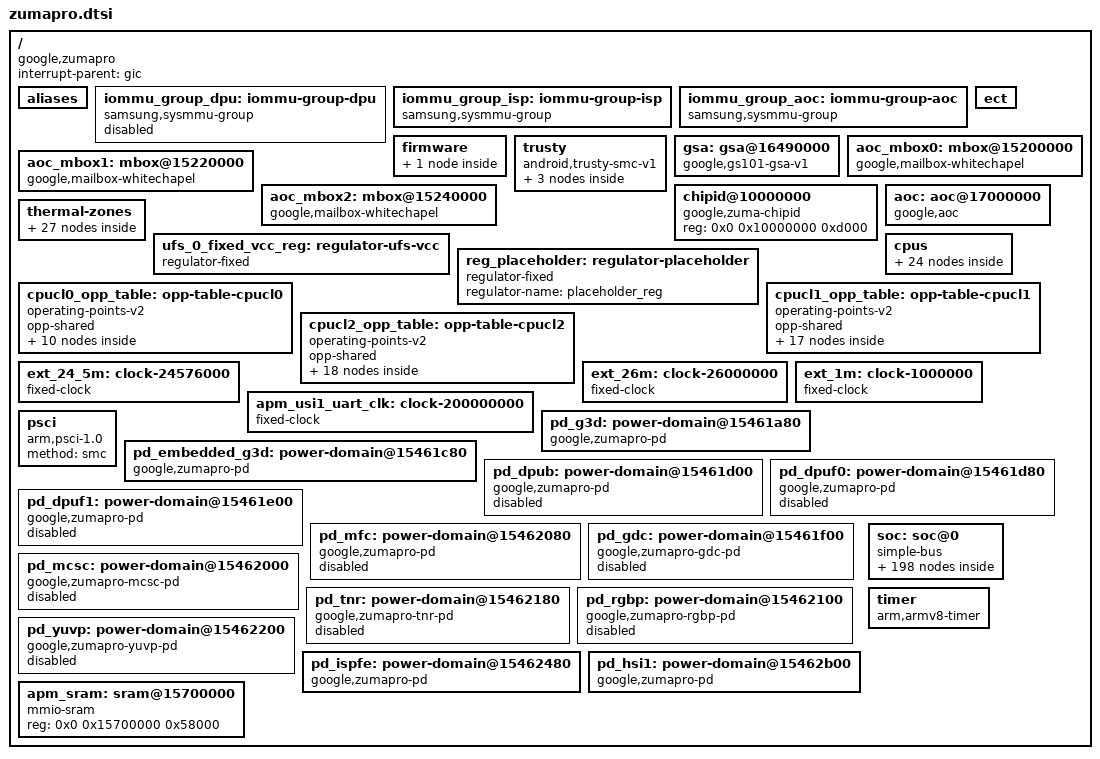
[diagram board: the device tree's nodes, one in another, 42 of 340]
// SPDX-License-Identifier: GPL-2.0-only
/*
 * Google Tensor G4 "Zumapro" SoC skeleton.
 *
 * Hardware values are taken from the downstream Pixel 9a/Tegu dump in
 * ../../../../../../research/dumped.dts unless another source is named.
 */

#include <dt-bindings/clock/google,zumapro-acpm.h>
#include <dt-bindings/clock/google,zumapro.h>
#include <dt-bindings/gpio/gpio.h>
#include <dt-bindings/interconnect/google,zumapro.h>
#include <dt-bindings/interrupt-controller/arm-gic.h>
#include <dt-bindings/interrupt-controller/irq.h>
#include <dt-bindings/interconnect/google,zumapro.h>
#include <dt-bindings/thermal/thermal.h>
#include <dt-bindings/soc/samsung,exynos-usi.h>
#include "zumapro-pinctrl.h"

/ {
	/*
	 * Source: downstream compatible strings are "google,ZUMA PRO TEGU",
	 * "google,ZUMA PRO" in research/dumped.dts:6.  The lowercase spelling
	 * follows the upstream convention documented in google.yaml.
	 */
	compatible = "google,zumapro";
	#address-cells = <2>;
	#size-cells = <1>;

	/* Source: interrupt-parent points at the GIC in research/dumped.dts:7. */
	interrupt-parent = <&gic>;

	/*
	 * Source: downstream aliases in research/dumped.dts:5759-5772.
	 * Keep the pinctrl aliases aligned with downstream controller numbering.
	 */
	aliases {
		pinctrl0 = &pinctrl_alive;
		pinctrl1 = &pinctrl_eint;
		pinctrl2 = &pinctrl_far_alive;
		pinctrl3 = &pinctrl_gsacore0;
		pinctrl4 = &pinctrl_gsacore1;
		pinctrl5 = &pinctrl_gsacore2;
		pinctrl6 = &pinctrl_gsacore3;
		pinctrl7 = &pinctrl_gsacore4;
		pinctrl8 = &pinctrl_hsi0;
		pinctrl9 = &pinctrl_hsi1;
		pinctrl10 = &pinctrl_hsi2;
		pinctrl11 = &pinctrl_peric0;
		pinctrl12 = &pinctrl_peric1;
		i2c2 = &hsi2c_2;
		i2c3 = &hsi2c_3;
		i2c4 = &hsi2c_4;
		i2c5 = &hsi2c_5;
		i2c6 = &hsi2c_6;
		i2c9 = &hsi2c_9;
		i2c10 = &hsi2c_10;
		ufs0 = &ufs_0;
	};

	/*
	 * Source: downstream iommu_group_dpu in zumapro-sysmmu.dtsi and
	 * research/dumped.dts:762.  TRACE NEEDED: validate how the downstream
	 * v9 group driver maps DECON0's two DPUF System MMUs before wiring a
	 * mainline DECON node to this group.
	 */
	iommu_group_dpu: iommu-group-dpu {
		compatible = "samsung,sysmmu-group";
		status = "disabled";
	};

	/*
	 * Source: downstream iommu_group_isp in research/dumped.dts:768.  The
	 * camera's three System MMUs share one group and one page table, and
	 * the v9 driver requires the group object to exist: without a
	 * samsung,iommu-group phandle it falls back to generic_device_group(),
	 * whose group carries no driver data, and every attach then fails with
	 * -EPROBE_DEFER -- which the IOMMU core warns about and does not
	 * retry, leaving the camera on dma-direct.
	 */
	iommu_group_isp: iommu-group-isp {
		compatible = "samsung,sysmmu-group";
	};

	/*
	 * Source: downstream iommu_group_aoc in research/dumped.dts:837.
	 * The AoC device references this group via samsung,iommu-group.
	 * Enabled (unlike the DPU group above) because AoC is being wired up.
	 */
	iommu_group_aoc: iommu-group-aoc {
		compatible = "samsung,sysmmu-group";
	};

	/*
	 * Source: GS101 upstream binding requires an empty ect node
	 * (Documentation/devicetree/bindings/arm/google.yaml).  The Zumapro
	 * downstream tree also has ECT reserved memory at dumped.dts:1320.
	 */
	ect {
	};

	/*
	 * Source: gs101.dtsi ACPM pattern.  Protocol identity with gs101 was
	 * hardware-verified on the Pixel 9a: the channel table at SRAM+0xa000
	 * parses with the mainline gs101 initdata structs (16 channels, PMIC
	 * on channel 2), and a full boot of the downstream kernel traced
	 * under the m1n1 hypervisor showed the identical doorbell/queue/PMIC
	 * wire protocol, so the gs101 fallback compatible drives the zumapro
	 * ACPM firmware unmodified.  See research/tracing/acpm-channels.md
	 * and research/tracing/acpm-boot-rail-snapshot.md.
	 */
	firmware {
		acpm_ipc: power-management {
			compatible = "google,zumapro-acpm-ipc",
				     "google,gs101-acpm-ipc";
			mboxes = <&ap2apm_mailbox>;
			shmem = <&apm_sram>;
			/*
			 * clk-acpm registers its ACPM-DVFS clocks against this
			 * node (the child clk device has no of_node, so the clk
			 * core falls back to the parent), so consumers reference
			 * them as <&acpm_ipc id>, where id is the ACPM DVFS
			 * domain index (e.g. 7 = G3D, 8 = G3DL2).
			 */
			#clock-cells = <1>;

		};
	};

	/*
	 * Trusty TEE.  SMC transport to the bootloader-started Trusty (TZSW);
	 * no MMIO.  Children are the IRQ forwarder, the log, and the virtio
	 * transport that carries tipc.  ipi-range mirrors research/dumped.dts
	 * (trusty/irq ipi-range = <8 15 8>).  Needed for the AoC GSA-hwmgr
	 * firmware-start path (docs/platform/aoc.md).
	 */
	trusty {
		compatible = "android,trusty-smc-v1";

		irq {
			compatible = "android,trusty-irq-v1";
			ipi-range = <8 15 8>;
		};

		log {
			compatible = "android,trusty-log-v1";
		};

		virtio {
			compatible = "android,trusty-virtio-v1";
		};
	};

	/*
	 * Google Security Authenticator (GSA) client.  Hardware mailbox at
	 * 0x16490000 for firmware-image authentication, plus a Trusty tipc
	 * channel (hwmgr) for coprocessor start.  The s2mpu phandle and the
	 * log-region / gsa_gsc child are omitted -- pKVM, GSC and the GSA log
	 * are disabled for this minimal bring-up.  Needed to authenticate and
	 * start AoC (docs/platform/aoc.md).  IRQ from research/dumped.dts
	 * (gsa-ns interrupts = <0 0x177 4>).
	 */
	gsa: gsa@16490000 {
		compatible = "google,gs101-gsa-v1";
		reg = <0x0 0x16490000 0x1000>;
		interrupts = <GIC_SPI 375 IRQ_TYPE_LEVEL_HIGH 0>;
	};

	/*
	 * Whitechapel mailbox controllers for AoC.  Source: downstream
	 * mbox@15200000/15220000/15240000 in research/dumped.dts:13198-13232.
	 * Each carries 16 AoC<->AP channels; the AoC node below fans all 48
	 * out through them.  reg/interrupts/mbox-name and the
	 * wc-mbox-non-wake-channels mask are verbatim from the dump.
	 */
	aoc_mbox0: mbox@15200000 {
		compatible = "google,mailbox-whitechapel";
		reg = <0x0 0x15200000 0x1000>;
		interrupts = <GIC_SPI 77 IRQ_TYPE_LEVEL_HIGH 0>;
		mbox-name = "aoc_a32_ap";
		#mbox-cells = <1>;
		wc-mbox-non-wake-channels = <0xf000>;
	};

	aoc_mbox1: mbox@15220000 {
		compatible = "google,mailbox-whitechapel";
		reg = <0x0 0x15220000 0x1000>;
		interrupts = <GIC_SPI 78 IRQ_TYPE_LEVEL_HIGH 0>;
		mbox-name = "aoc_f1_ap";
		#mbox-cells = <1>;
		wc-mbox-non-wake-channels = <0xf000>;
	};

	aoc_mbox2: mbox@15240000 {
		compatible = "google,mailbox-whitechapel";
		reg = <0x0 0x15240000 0x1000>;
		interrupts = <GIC_SPI 79 IRQ_TYPE_LEVEL_HIGH 0>;
		mbox-name = "aoc_p6_ap";
		#mbox-cells = <1>;
		wc-mbox-non-wake-channels = <0xf000>;
	};

	/*
	 * SoC chip-id block.  Source: downstream chipid@10000000 in
	 * research/dumped.dts:14927 (reg verbatim).  No in-tree driver binds this
	 * compatible; the AoC chip-id reader (aoc_chipid.c) maps it to forward the
	 * SoC product-id/type/revision to AoC firmware via fw_data.
	 */
	chipid@10000000 {
		compatible = "google,zuma-chipid";
		reg = <0x0 0x10000000 0xd000>;
	};

	/*
	 * Always-On Compute coprocessor.  Source: downstream aoc@17000000 in
	 * research/dumped.dts:13234.  reg regions (blk_aoc, aoc_req, aoc_s2mpu,
	 * ssmt_aoc), the watchdog interrupt, the 48-channel mailbox fan-out and
	 * every scalar tuning word are verbatim from the dump.  Dropped from the
	 * dump: pinctrl-0/-names (driver never uses pinctrl; the phandle pointed
	 * at aoc-vsync-pins) and sensor_1v8/3v3-supply + sensor_power_list (would
	 * pull in regulators; sensor power is deferred).
	 */
	aoc: aoc@17000000 {
		compatible = "google,aoc";
		reg = <0x0 0x17000000 0x2000000>,
		      <0x0 0x154b0000 0x1000>,
		      <0x0 0x190c0000 0x1000>,
		      <0x0 0x19060000 0x5000>;
		reg-names = "blk_aoc", "aoc_req", "aoc_s2mpu", "ssmt_aoc";
		interrupts = <GIC_SPI 130 IRQ_TYPE_LEVEL_HIGH 0>;
		interrupt-names = "watchdog";
		iommus = <&sysmmu_aoc>;
		samsung,iommu-group = <&iommu_group_aoc>;
		memory-region = <&aoc_reserved>;
		/* gsa-enabled = "true"; -- read as a bool; a string value warns */
		gsa-enabled;
		gsa-device = <&gsa>;
		mbox-channels = <48>;
		mbox-names = "aoc2ap";
		mboxes = <&aoc_mbox0 0>, <&aoc_mbox0 1>, <&aoc_mbox0 2>,
			 <&aoc_mbox0 3>, <&aoc_mbox0 4>, <&aoc_mbox0 5>,
			 <&aoc_mbox0 6>, <&aoc_mbox0 7>, <&aoc_mbox0 8>,
			 <&aoc_mbox0 9>, <&aoc_mbox0 10>, <&aoc_mbox0 11>,
			 <&aoc_mbox0 12>, <&aoc_mbox0 13>, <&aoc_mbox0 14>,
			 <&aoc_mbox0 15>,
			 <&aoc_mbox1 0>, <&aoc_mbox1 1>, <&aoc_mbox1 2>,
			 <&aoc_mbox1 3>, <&aoc_mbox1 4>, <&aoc_mbox1 5>,
			 <&aoc_mbox1 6>, <&aoc_mbox1 7>, <&aoc_mbox1 8>,
			 <&aoc_mbox1 9>, <&aoc_mbox1 10>, <&aoc_mbox1 11>,
			 <&aoc_mbox1 12>, <&aoc_mbox1 13>, <&aoc_mbox1 14>,
			 <&aoc_mbox1 15>,
			 <&aoc_mbox2 0>, <&aoc_mbox2 1>, <&aoc_mbox2 2>,
			 <&aoc_mbox2 3>, <&aoc_mbox2 4>, <&aoc_mbox2 5>,
			 <&aoc_mbox2 6>, <&aoc_mbox2 7>, <&aoc_mbox2 8>,
			 <&aoc_mbox2 9>, <&aoc_mbox2 10>, <&aoc_mbox2 11>,
			 <&aoc_mbox2 12>, <&aoc_mbox2 13>, <&aoc_mbox2 14>,
			 <&aoc_mbox2 15>;
		acpm-ipc-channel = <0x0d>;
		force-vnom = <0x00>;
		pcu-base = <0x1400000>;
		gpio-base = <0x1c00000>;
		pcu-db-set-offset = <0x1f004>;
		pcu-db-clr-offset = <0x1f008>;
		cp-aperture-start-offset = <0x7fdf80>;
		cp-aperture-end-offset = <0x7fffff>;
		clock-divider = <0x01>;
		channel-max-pending-msgs = <0x80>;
		block-channel-threshold = <0x40>;
		notify-on-state-transition = "true";
		hotword-supported = "true";
		chre-supported = "true";
		aoc-board-cfg = "TG4";
		aoc-board-id = <0x60b02>;
		aoc-board-rev = <0x10000>;
		prevent-fw-load = <0x00>;
		gnss-type = <0x02>;
	};

	/*
	 * ACPM TMU zones.  The ACPM firmware only *measures* on a bare boot (its
	 * throttling governor is configured by the downstream kernel, not the
	 * bootloader), so the CPU-cluster zones own throttling in Linux via
	 * cpufreq cooling under the power_allocator (IPA) PID governor -- the
	 * mainline analog of downstream's use-pi-thermal.  step_wise only
	 * limit-cycles on the fast X4; IPA holds the setpoint (HW-validated).
	 * Each CPU zone has a SINGLE passive control trip (the IPA setpoint,
	 * downstream BIG 90 / MID,LITTLE 95, dumped.dts:17894+) plus a critical
	 * backstop.  With one passive trip IPA runs always-on and its band is the
	 * control temperature itself, so estimate_pid_constants() derives gentle
	 * gains (k_po~17) -- a second "switch-on" passive trip narrows the band
	 * into steep gains and resets the PID integral whenever the fast X4 dips
	 * below it, collapsing the controller into a bang-bang relay (HW-confirmed
	 * 45<->100 C swing).  sustainable-power is measured per cluster with the
	 * S2MPG14 ODPM meter under an all-core load: BIG=1200 (its draw while IPA
	 * holds it at the 90 C trip); MID=1500 and LITTLE=1000 are the clusters'
	 * full-tilt power -- they only reach ~80/60 C, well below their 95 C trip,
	 * so their value is a never-actuated safety-net feed-forward.
	 * Cluster<->sensor: cpu7 (X4)=BIG tzid0, cpu4 (A720)=MID tzid1, cpu0
	 * (A520)=LITTLE tzid2.  G3D/ISP/TPU/AUR stay monitor-only.
	 *
	 * Trip *detection* is now the TMU interrupt's job: it fires when the zone
	 * leaves the thermal core's trip window, so a hard ramp no longer waits
	 * for a poll to be noticed.  polling-delay-passive stays at 25 ms because
	 * IPA's PID needs periodic samples once it is regulating; the interrupt
	 * arms that state immediately instead of up to a poll period late.
	 *
	 * polling-delay must NOT be 0, even with interrupts.  These zones have a
	 * single passive trip, so gov_power_allocator's setup leaves
	 * params->trip_switch_on NULL (it is the *first* of two or more passive
	 * trips), and power_allocator_manage() gates allow_maximum_power() on it.
	 * IPA therefore has no explicit release path here: it only unwinds a
	 * throttle through repeated allocate_power() calls as the zone cools.
	 * Once the zone drops out of the trip's hysteresis band tz->passive falls
	 * to 0 and the 25 ms passive poll stops, so with polling-delay = 0 nothing
	 * would ever run the governor again and the last cooling state would stick
	 * forever -- HW-observed: cpu7 pinned at 13/17 (1745 of 3105 MHz) at 41 C
	 * idle until something else poked the zone.  The cool-side poll is what
	 * releases the throttle, which is why 1 s is enough now that it no longer
	 * has to *detect* anything.  (Upstream gs101 can use 0 because its ladder
	 * has two passive trips, so allow_maximum_power() is reachable there.)
	 */
	thermal-zones {
		big-thermal {
			polling-delay = <1000>;
			polling-delay-passive = <25>;
			thermal-sensors = <&tmu_top 0>;
			sustainable-power = <1200>;

			trips {
				/*
				 * Single passive trip = always-on IPA: the band is
				 * the control temperature itself (90 C), which makes
				 * estimate_pid_constants() derive gentle gains
				 * (k_po~17).  A second "switch-on" passive trip would
				 * narrow the band into steep gains AND reset the PID
				 * integral every time the fast X4 dips below it, which
				 * degrades the controller into a bang-bang relay
				 * (HW-confirmed).  This is also step_wise's throttle
				 * point when that fallback governor is selected.
				 */
				big_alert: throttle {
					temperature = <90000>;
					hysteresis = <5000>;
					type = "passive";
				};

				big_crit: critical {
					temperature = <115000>;
					hysteresis = <1000>;
					type = "critical";
				};
			};

			cooling-maps {
				map0 {
					trip = <&big_alert>;
					cooling-device = <&cpu7 THERMAL_NO_LIMIT THERMAL_NO_LIMIT>;
				};
			};
		};

		mid-thermal {
			polling-delay = <1000>;
			polling-delay-passive = <25>;
			thermal-sensors = <&tmu_top 1>;
			/*
			 * Measured ~1500 mW full-tilt (ODPM, all-core load); MID
			 * peaks ~80 C, 15 C below its control trip, so like LITTLE
			 * this is a never-actuated safety-net feed-forward.
			 */
			sustainable-power = <1500>;

			trips {
				/* Always-on IPA, single passive trip; see big-thermal. */
				mid_alert: throttle {
					temperature = <95000>;
					hysteresis = <5000>;
					type = "passive";
				};

				mid_crit: critical {
					temperature = <115000>;
					hysteresis = <1000>;
					type = "critical";
				};
			};

			cooling-maps {
				map0 {
					trip = <&mid_alert>;
					cooling-device = <&cpu4 THERMAL_NO_LIMIT THERMAL_NO_LIMIT>;
				};
			};
		};

		little-thermal {
			polling-delay = <1000>;
			polling-delay-passive = <25>;
			thermal-sensors = <&tmu_top 2>;
			/*
			 * Measured ~1000 mW full-tilt (ODPM, all-core load -- the
			 * EM estimate of ~440 mW was ~2x low for the A520).  LITTLE
			 * peaks ~60 C, 35 C below its control trip, so this never
			 * actuates; it is a safety-net feed-forward only.
			 */
			sustainable-power = <1000>;

			trips {
				/* Always-on IPA, single passive trip; see big-thermal. */
				little_alert: throttle {
					temperature = <95000>;
					hysteresis = <5000>;
					type = "passive";
				};

				little_crit: critical {
					temperature = <115000>;
					hysteresis = <1000>;
					type = "critical";
				};
			};

			cooling-maps {
				map0 {
					trip = <&little_alert>;
					cooling-device = <&cpu0 THERMAL_NO_LIMIT THERMAL_NO_LIMIT>;
				};
			};
		};

		/*
		 * Throttle temps are downstream's (throttle 90 C, and a 115 C
		 * critical backstop matching the CPU zones).  The sensor reads
		 * live at all times because pd_g3d is samsung,always-on, so
		 * there is no collapsed-domain reading to guard against.
		 *
		 * sustainable-power is the measured full-tilt figure, matching
		 * the top of the OPP table's own measured power (glmark2 pinned
		 * at 940 MHz reached only 63 C, so the part sustains this
		 * without approaching the trip -- like MID and LITTLE, this is a
		 * feed-forward safety net rather than something that actuates).
		 *
		 * It has to be set explicitly, and not just for accuracy: with a
		 * single passive trip the IPA gains come from
		 * estimate_pid_constants() as sustainable_power over the control
		 * temperature, so a small value truncates k_po and k_pu to ZERO
		 * and the budget collapses to sustainable_power alone.  Letting
		 * the kernel estimate it here produced 28 mW, which pinned the
		 * GPU at cooling state 7 -- capped at 521 MHz -- while idling at
		 * 48 C, 40 C below the trip.
		 */
		g3d-thermal {
			polling-delay = <1000>;
			polling-delay-passive = <25>;
			thermal-sensors = <&tmu_sub 0>;
			sustainable-power = <740>;

			trips {
				/* Always-on IPA, single passive trip; see big-thermal. */
				g3d_alert: throttle {
					temperature = <90000>;
					hysteresis = <5000>;
					type = "passive";
				};

				g3d_crit: critical {
					temperature = <115000>;
					hysteresis = <1000>;
					type = "critical";
				};
			};

			cooling-maps {
				map0 {
					trip = <&g3d_alert>;
					cooling-device = <&gpu THERMAL_NO_LIMIT THERMAL_NO_LIMIT>;
				};
			};
		};

		isp-thermal {
			polling-delay = <0>;
			polling-delay-passive = <0>;
			thermal-sensors = <&tmu_sub 1>;
		};

		tpu-thermal {
			polling-delay = <0>;
			polling-delay-passive = <0>;
			thermal-sensors = <&tmu_sub 2>;
		};

		aur-thermal {
			polling-delay = <0>;
			polling-delay-passive = <0>;
			thermal-sensors = <&tmu_sub 3>;
		};
	};

	/*
	 * Source: dumped.dts:7858-7863. The pre-guest m1n1 readout shows
	 * gpp0-1 is an output but low at handoff, so Linux must assert this
	 * fixed-regulator GPIO before UFS link startup.
	 */
	ufs_0_fixed_vcc_reg: regulator-ufs-vcc {
		compatible = "regulator-fixed";
		regulator-name = "ufs-vcc";
		gpio = <&gpp0 1 GPIO_ACTIVE_HIGH>;
		regulator-boot-on;
		enable-active-high;
	};

	/*
	 * Placeholder supply for rails that are real but not yet driver-managed,
	 * mirroring the gs101 reg_placeholder approach.  The USB controller/PHY
	 * rails (downstream m_ldo8/m_ldo9/m_ldo19 under sub_pd_hsi0, left enabled
	 * by the bootloader) are wired here so the mainline drivers'
	 * regulator_get() calls resolve to a real fixed supply rather than an
	 * implicit dummy.
	 *
	 * TODO: replace with the real s2mpg14/15 PMIC rails once that driver
	 * exists.  Expected mapping: vdd -> m_ldo8, vdda12 -> m_ldo9, and
	 * vdd33 (plus the eUSB repeater) -> m_ldo19.
	 */
	reg_placeholder: regulator-placeholder {
		compatible = "regulator-fixed";
		regulator-name = "placeholder_reg";
	};

	cpus {
		/*
		 * Source: CPU address/size cells match research/dumped.dts:3065-3066.
		 */
		#address-cells = <2>;
		#size-cells = <0>;

		/*
		 * Source: downstream cpu-map is flattened in dumped.dts:3068-3106,
		 * while the cluster grouping below follows downstream cpupm/acme
		 * sibling CPU groups in dumped.dts:3248-3275 and 3327-3369.
		 */
		cpu-map {
			cluster0 {
				core0 {
					cpu = <&cpu0>;
				};
				core1 {
					cpu = <&cpu1>;
				};
				core2 {
					cpu = <&cpu2>;
				};
				core3 {
					cpu = <&cpu3>;
				};
			};

			cluster1 {
				core0 {
					cpu = <&cpu4>;
				};
				core1 {
					cpu = <&cpu5>;
				};
				core2 {
					cpu = <&cpu6>;
				};
			};

			cluster2 {
				core0 {
					cpu = <&cpu7>;
				};
			};
		};

		/*
		 * Source: reg, enable-method, idle-state assignment, capacity, and
		 * dynamic power values are copied from research/dumped.dts:3108-3188.
		 * Downstream only reports compatible = "arm,armv9.2"; the concrete
		 * Cortex compatibles below are inferred from the downstream Hayes,
		 * Hunter, and Hunter-ELP idle-state names at dumped.dts:3198,
		 * dumped.dts:3210, and dumped.dts:3222.  Verify against MIDR on
		 * hardware before treating the CPU compatible strings as final.
		 */
		cpu0: cpu@0 {
			device_type = "cpu";
			compatible = "arm,cortex-a520";
			reg = <0x0 0x0>;
			clocks = <&acpm_ipc ZUMAPRO_CLK_ACPM_DVFS_CPUCL0>;
			operating-points-v2 = <&cpucl0_opp_table>;
			enable-method = "psci";
			cpu-idle-states = <&hayes_cpu_sleep>;
			capacity-dmips-mhz = <0xc1>;
			dynamic-power-coefficient = <0x46>;
			#cooling-cells = <2>;
		};

		cpu1: cpu@100 {
			device_type = "cpu";
			compatible = "arm,cortex-a520";
			reg = <0x0 0x100>;
			clocks = <&acpm_ipc ZUMAPRO_CLK_ACPM_DVFS_CPUCL0>;
			operating-points-v2 = <&cpucl0_opp_table>;
			enable-method = "psci";
			cpu-idle-states = <&hayes_cpu_sleep>;
			capacity-dmips-mhz = <0xc1>;
			dynamic-power-coefficient = <0x46>;
		};

		cpu2: cpu@200 {
			device_type = "cpu";
			compatible = "arm,cortex-a520";
			reg = <0x0 0x200>;
			clocks = <&acpm_ipc ZUMAPRO_CLK_ACPM_DVFS_CPUCL0>;
			operating-points-v2 = <&cpucl0_opp_table>;
			enable-method = "psci";
			cpu-idle-states = <&hayes_cpu_sleep>;
			capacity-dmips-mhz = <0xc1>;
			dynamic-power-coefficient = <0x46>;
		};

		cpu3: cpu@300 {
			device_type = "cpu";
			compatible = "arm,cortex-a520";
			reg = <0x0 0x300>;
			clocks = <&acpm_ipc ZUMAPRO_CLK_ACPM_DVFS_CPUCL0>;
			operating-points-v2 = <&cpucl0_opp_table>;
			enable-method = "psci";
			cpu-idle-states = <&hayes_cpu_sleep>;
			capacity-dmips-mhz = <0xc1>;
			dynamic-power-coefficient = <0x46>;
		};

		cpu4: cpu@400 {
			device_type = "cpu";
			compatible = "arm,cortex-a720";
			reg = <0x0 0x400>;
			clocks = <&acpm_ipc ZUMAPRO_CLK_ACPM_DVFS_CPUCL1>;
			operating-points-v2 = <&cpucl1_opp_table>;
			enable-method = "psci";
			cpu-idle-states = <&hunter_cpu_sleep>;
			capacity-dmips-mhz = <0x39f>;
			dynamic-power-coefficient = <0x201>;
			#cooling-cells = <2>;
		};

		cpu5: cpu@500 {
			device_type = "cpu";
			compatible = "arm,cortex-a720";
			reg = <0x0 0x500>;
			clocks = <&acpm_ipc ZUMAPRO_CLK_ACPM_DVFS_CPUCL1>;
			operating-points-v2 = <&cpucl1_opp_table>;
			enable-method = "psci";
			cpu-idle-states = <&hunter_cpu_sleep>;
			capacity-dmips-mhz = <0x39f>;
			dynamic-power-coefficient = <0x201>;
		};

		cpu6: cpu@600 {
			device_type = "cpu";
			compatible = "arm,cortex-a720";
			reg = <0x0 0x600>;
			clocks = <&acpm_ipc ZUMAPRO_CLK_ACPM_DVFS_CPUCL1>;
			operating-points-v2 = <&cpucl1_opp_table>;
			enable-method = "psci";
			cpu-idle-states = <&hunter_cpu_sleep>;
			capacity-dmips-mhz = <0x39f>;
			dynamic-power-coefficient = <0x201>;
		};

		cpu7: cpu@700 {
			device_type = "cpu";
			compatible = "arm,cortex-x4";
			reg = <0x0 0x700>;
			clocks = <&acpm_ipc ZUMAPRO_CLK_ACPM_DVFS_CPUCL2>;
			operating-points-v2 = <&cpucl2_opp_table>;
			enable-method = "psci";
			cpu-idle-states = <&hunterelp_cpu_sleep>;
			capacity-dmips-mhz = <0x400>;
			dynamic-power-coefficient = <0x2f5>;
			#cooling-cells = <2>;
		};

		idle-states {
			/*
			 * Source: idle-state values come from research/dumped.dts:3195-3228.
			 * entry-method is normalized to "psci" per psci.yaml; downstream
			 * used "arm,psci".
			 */
			entry-method = "psci";

			hayes_cpu_sleep: cpu-hayes-sleep {
				idle-state-name = "c2";
				compatible = "arm,idle-state";
				arm,psci-suspend-param = <0x10000>;
				local-timer-stop;
				entry-latency-us = <0x46>;
				exit-latency-us = <0xa0>;
				min-residency-us = <0x7d0>;
			};

			hunter_cpu_sleep: cpu-hunter-sleep {
				idle-state-name = "c2";
				compatible = "arm,idle-state";
				arm,psci-suspend-param = <0x10000>;
				local-timer-stop;
				entry-latency-us = <0x96>;
				exit-latency-us = <0xbe>;
				min-residency-us = <0x9c4>;
			};

			hunterelp_cpu_sleep: cpu-hunterelp-sleep {
				idle-state-name = "c2";
				compatible = "arm,idle-state";
				arm,psci-suspend-param = <0x10000>;
				local-timer-stop;
				entry-latency-us = <0xeb>;
				exit-latency-us = <0xdc>;
				min-residency-us = <0xdac>;
			};
		};
	};

	/*
	 * CPU operating points for the three clusters.  Frequencies are the
	 * downstream pixel-em "default" profile (research/dumped.dts:3360, the
	 * cpu0/cpu4/cpu7 ladders) and match the exynos-acme per-domain
	 * min/max-freq at research/dumped.dts:3326-3370.  The supplying clock is
	 * the ACPM DVFS domain for each cluster (CPUCL0/1/2 = ids 2/3/4 per
	 * private/.../cal-if/zuma/acpm_dvfs_zuma.h), so ACPM owns the rail
	 * voltage; cpufreq-dt binds via the platdev fallback once cpu@0 has
	 * operating-points-v2.
	 *
	 * opp-microvolt is NOT actuated here: the CPUs carry no cpu-supply, so the
	 * OPP core never programs a rail (ACPM still owns voltage).  It exists only
	 * so cpufreq-dt builds an Energy Model (P = C*V^2*f), which makes the
	 * cpufreq cooling devices power actors so the thermal power_allocator (IPA)
	 * governor can hold the CPU zones at their trip instead of letting step_wise
	 * oscillate.  These values are an ESTIMATED monotonic V/f curve (~0.6 V min
	 * to ~1.05 V max); IPA's feedback tolerates the approximation.
	 * TODO: replace with the real per-chip ASV ladder read from the ACPM fvmap
	 * at runtime (a small fvmap-reader EM driver; see docs/subsystems/power/reference/thermal-acpm-tmu.md).
	 */
	cpucl0_opp_table: opp-table-cpucl0 {
		compatible = "operating-points-v2";
		opp-shared;

		opp-820000000  { opp-hz = /bits/ 64 <820000000>;  opp-microvolt = <600000>; };
		opp-955000000  { opp-hz = /bits/ 64 <955000000>;  opp-microvolt = <625000>; };
		opp-1098000000 { opp-hz = /bits/ 64 <1098000000>; opp-microvolt = <650000>; };
		opp-1197000000 { opp-hz = /bits/ 64 <1197000000>; opp-microvolt = <675000>; };
		opp-1328000000 { opp-hz = /bits/ 64 <1328000000>; opp-microvolt = <700000>; };
		opp-1425000000 { opp-hz = /bits/ 64 <1425000000>; opp-microvolt = <725000>; };
		opp-1548000000 { opp-hz = /bits/ 64 <1548000000>; opp-microvolt = <755000>; };
		opp-1696000000 { opp-hz = /bits/ 64 <1696000000>; opp-microvolt = <800000>; };
		opp-1849000000 { opp-hz = /bits/ 64 <1849000000>; opp-microvolt = <850000>; };
		opp-1950000000 { opp-hz = /bits/ 64 <1950000000>; opp-microvolt = <900000>; };
	};

	cpucl1_opp_table: opp-table-cpucl1 {
		compatible = "operating-points-v2";
		opp-shared;

		opp-357000000  { opp-hz = /bits/ 64 <357000000>;  opp-microvolt = <575000>; };
		opp-578000000  { opp-hz = /bits/ 64 <578000000>;  opp-microvolt = <600000>; };
		opp-648000000  { opp-hz = /bits/ 64 <648000000>;  opp-microvolt = <615000>; };
		opp-787000000  { opp-hz = /bits/ 64 <787000000>;  opp-microvolt = <640000>; };
		opp-910000000  { opp-hz = /bits/ 64 <910000000>;  opp-microvolt = <665000>; };
		opp-1065000000 { opp-hz = /bits/ 64 <1065000000>; opp-microvolt = <690000>; };
		opp-1221000000 { opp-hz = /bits/ 64 <1221000000>; opp-microvolt = <715000>; };
		opp-1328000000 { opp-hz = /bits/ 64 <1328000000>; opp-microvolt = <740000>; };
		opp-1418000000 { opp-hz = /bits/ 64 <1418000000>; opp-microvolt = <765000>; };
		opp-1549000000 { opp-hz = /bits/ 64 <1549000000>; opp-microvolt = <790000>; };
		opp-1795000000 { opp-hz = /bits/ 64 <1795000000>; opp-microvolt = <825000>; };
		opp-1945000000 { opp-hz = /bits/ 64 <1945000000>; opp-microvolt = <850000>; };
		opp-2130000000 { opp-hz = /bits/ 64 <2130000000>; opp-microvolt = <890000>; };
		opp-2245000000 { opp-hz = /bits/ 64 <2245000000>; opp-microvolt = <915000>; };
		opp-2367000000 { opp-hz = /bits/ 64 <2367000000>; opp-microvolt = <940000>; };
		opp-2450000000 { opp-hz = /bits/ 64 <2450000000>; opp-microvolt = <965000>; };
		opp-2600000000 { opp-hz = /bits/ 64 <2600000000>; opp-microvolt = <1000000>; };
	};

	cpucl2_opp_table: opp-table-cpucl2 {
		compatible = "operating-points-v2";
		opp-shared;

		opp-700000000  { opp-hz = /bits/ 64 <700000000>;  opp-microvolt = <600000>; };
		opp-1164000000 { opp-hz = /bits/ 64 <1164000000>; opp-microvolt = <640000>; };
		opp-1396000000 { opp-hz = /bits/ 64 <1396000000>; opp-microvolt = <665000>; };
		opp-1557000000 { opp-hz = /bits/ 64 <1557000000>; opp-microvolt = <690000>; };
		opp-1745000000 { opp-hz = /bits/ 64 <1745000000>; opp-microvolt = <715000>; };
		opp-1885000000 { opp-hz = /bits/ 64 <1885000000>; opp-microvolt = <740000>; };
		opp-1999000000 { opp-hz = /bits/ 64 <1999000000>; opp-microvolt = <765000>; };
		opp-2147000000 { opp-hz = /bits/ 64 <2147000000>; opp-microvolt = <790000>; };
		opp-2294000000 { opp-hz = /bits/ 64 <2294000000>; opp-microvolt = <815000>; };
		opp-2363000000 { opp-hz = /bits/ 64 <2363000000>; opp-microvolt = <840000>; };
		opp-2499000000 { opp-hz = /bits/ 64 <2499000000>; opp-microvolt = <865000>; };
		opp-2687000000 { opp-hz = /bits/ 64 <2687000000>; opp-microvolt = <900000>; };
		opp-2802000000 { opp-hz = /bits/ 64 <2802000000>; opp-microvolt = <940000>; };
		opp-2914000000 { opp-hz = /bits/ 64 <2914000000>; opp-microvolt = <975000>; };
		opp-2943000000 { opp-hz = /bits/ 64 <2943000000>; opp-microvolt = <990000>; };
		opp-2970000000 { opp-hz = /bits/ 64 <2970000000>; opp-microvolt = <1000000>; };
		opp-3015000000 { opp-hz = /bits/ 64 <3015000000>; opp-microvolt = <1025000>; };
		opp-3105000000 { opp-hz = /bits/ 64 <3105000000>; opp-microvolt = <1050000>; };
	};

	/*
	 * Source: fixed clock frequencies/names are from research/dumped.dts:15042-15070.
	 *
	 * ext_24_5m is the 24.576 MHz oscillator (fin_pll / OSCCLK), the PLL and
	 * CMU reference: downstream cal-if sets FIN_HZ_24P576M and the device's
	 * debugfs reads fin_pll = 24576000.  This is the clock the CMU "oscclk"
	 * inputs use.  Do NOT confuse it with ext_26m below, which is the separate
	 * 26 MHz TCXO (UMUX_CLKCMU_HSI0_TCXO) and is not the CMU oscclk.
	 */
	ext_24_5m: clock-24576000 {
		compatible = "fixed-clock";
		#clock-cells = <0>;
		clock-frequency = <24576000>;
		clock-output-names = "oscclk";
	};

	ext_26m: clock-26000000 {
		compatible = "fixed-clock";
		#clock-cells = <0>;
		clock-frequency = <26000000>;
		clock-output-names = "ext-26m";
	};

	ext_1m: clock-1000000 {
		compatible = "fixed-clock";
		#clock-cells = <0>;
		clock-frequency = <1000000>;
		clock-output-names = "ext-1m";
	};

	/*
	 * BLK_ALIVE APM_USI1 UART (uart18 = Bluetooth HCI) baud clock.
	 * Downstream dmesg reports "155d0000.serial: Clock rate : 200000000".
	 * CMU_APM is not modeled yet and this rail is owned by ACPM and left
	 * running, so model it as a fixed-clock; replace with the real
	 * DOUT_CLK_APM_USI1_UART once CMU_APM lands.
	 */
	apm_usi1_uart_clk: clock-200000000 {
		compatible = "fixed-clock";
		#clock-cells = <0>;
		clock-frequency = <200000000>;
		clock-output-names = "apm_usi1_uart";
	};

	/*
	 * Source: PSCI compatible/method are from research/dumped.dts:3235-3239.
	 */
	psci {
		compatible = "arm,psci-1.0";
		method = "smc";
	};

	/*
	 * GPU (Mali-G715 / Tensor G4 "G3D") PM domains.  Source: downstream
	 * research/dumped_uart.dts:2699-2719 and the Phase-0 power-on trace
	 * (docs/subsystems/gpu/reference/gpu-power-trace-results.md).  Two domains: pd_g3d (top, the
	 * EL3-protected PMU register -> secure SMC path) and pd_embedded_g3d
	 * (the shader cores, a child of pd_g3d).
	 *
	 * Both are samsung,always-on.  On silicon the bootloader hands the GPU
	 * over fully powered (both PMU status regs 0x15461a84/0x15461c84 read 1),
	 * and the mainline power-OFF sequence times out on the cores domain (the
	 * CMU handshake the downstream pmucal performs around the transition is
	 * not yet replicated here), so genpd_power_off_unused cannot gate them.
	 * For first light we adopt the live, powered state (as the display splash
	 * pipeline does) instead of exercising an unproven off->on cycle; real
	 * runtime-PM power-cycling can drop always-on once the off-sequence works.
	 */
	pd_g3d: power-domain@15461a80 {
		compatible = "google,zumapro-pd";
		reg = <0x0 0x15461a80 0x20>,
		      <0x0 0x1ee00800 0x4>;
		reg-names = "pmu", "cmu";
		samsung,secure-pd-id = <0x1ee10204>;
		samsung,always-on;
		#power-domain-cells = <0>;
		label = "G3D";
	};

	pd_embedded_g3d: power-domain@15461c80 {
		compatible = "google,zumapro-pd";
		reg = <0x0 0x15461c80 0x20>;
		reg-names = "pmu";
		power-domains = <&pd_g3d>;
		samsung,always-on;
		#power-domain-cells = <0>;
		label = "G3D_CORES";
	};

	/*
	 * Display PM domains.  Source: downstream zumapro-pm-domains.dtsi and
	 * research/dumped.dts:2721-2754.  Keep disabled until the display clock,
	 * SysMMU, DSIM, and DECON drivers can consume them together; enabling
	 * these too early could hand genpd control of the bootloader splash path.
	 */
	pd_dpub: power-domain@15461d00 {
		compatible = "google,zumapro-pd";
		reg = <0x0 0x15461d00 0x20>,
		      <0x0 0x19400800 0x4>;
		reg-names = "pmu", "cmu";
		samsung,secure-pd-id = <0x19410204>;
		samsung,always-on;
		#power-domain-cells = <0>;
		label = "DPUB";
		status = "disabled";
	};

	pd_dpuf0: power-domain@15461d80 {
		compatible = "google,zumapro-pd";
		reg = <0x0 0x15461d80 0x20>,
		      <0x0 0x19800800 0x4>;
		reg-names = "pmu", "cmu";
		samsung,secure-pd-id = <0x19810204>;
		samsung,always-on;
		#power-domain-cells = <0>;
		power-domains = <&pd_dpub>;
		label = "DPUF0";
		status = "disabled";
	};

	pd_dpuf1: power-domain@15461e00 {
		compatible = "google,zumapro-pd";
		reg = <0x0 0x15461e00 0x20>,
		      <0x0 0x19c00800 0x4>;
		reg-names = "pmu", "cmu";
		samsung,secure-pd-id = <0x19c10204>;
		samsung,always-on;
		#power-domain-cells = <0>;
		power-domains = <&pd_dpub>;
		label = "DPUF1";
		status = "disabled";
	};

	/* MFC PMU configuration/status and secure TZPC save/restore identifier. */
	pd_mfc: power-domain@15462080 {
		compatible = "google,zumapro-pd";
		reg = <0x0 0x15462080 0x20>;
		reg-names = "pmu";
		samsung,secure-pd-id = <0x1a410204>;
		#power-domain-cells = <0>;
		label = "MFC";
		status = "disabled";
	};

	/*
	 * BLK_GDC is also a BE-core dependency: downstream documents that RGBP's
	 * command loader resides there, even when GDC receives no per-frame
	 * program.  Its dedicated compatible restores the CMU and opens the S2MPU
	 * before the GDC System MMU resumes.  Keep it passive with the other
	 * back-end domains until the native BE-core driver owns their lifecycle.
	 */
	pd_gdc: power-domain@15461f00 {
		compatible = "google,zumapro-gdc-pd";
		reg = <0x0 0x15461f00 0x20>,
		      <0x0 0x1d400000 0x10000>,
		      <0x0 0x1d420000 0x404>,
		      <0x0 0x1d4f0000 0x10000>;
		reg-names = "pmu", "cmu", "bus", "s2mpu0";
		samsung,secure-pd-id = <0x1d410204>;
		#power-domain-cells = <0>;
		label = "GDC";
		status = "disabled";
	};

	/*
	 * BLK_MCSC is the final scaler/output domain in the camera back end.
	 * Source: downstream pd-mcsc@15462000 and the Pixel 9a camera startup
	 * trace.  Its dedicated compatible restores the CMU/Q-channel state and
	 * opens the S2MPU before the MCSC System MMU resumes.  Keep it passive
	 * until BE-core owns the MCSC reset and interrupt lifecycle.
	 */
	pd_mcsc: power-domain@15462000 {
		compatible = "google,zumapro-mcsc-pd";
		reg = <0x0 0x15462000 0x20>,
		      <0x0 0x1d000000 0x10000>,
		      <0x0 0x1d020000 0x10c>,
		      <0x0 0x1d0d0000 0x10000>;
		reg-names = "pmu", "cmu", "bus", "s2mpu0";
		samsung,secure-pd-id = <0x1d010204>;
		#power-domain-cells = <0>;
		label = "MCSC";
		status = "disabled";
	};

	/*
	 * BLK_TNR contains the GTNR merge and align blocks.  Source: downstream
	 * pd-tnr@15462180 and the Pixel 9a camera startup trace.  All three
	 * S2MPUs reset closed with the shared domain, so restore them together
	 * even though the initial spatial GTNR path only consumes merge S0/S1.
	 * Keep the domain passive until BE-core owns the GTNR lifecycle.
	 */
	pd_tnr: power-domain@15462180 {
		compatible = "google,zumapro-tnr-pd";
		reg = <0x0 0x15462180 0x20>,
		      <0x0 0x1cc00000 0x10000>,
		      <0x0 0x1cc20000 0x110>,
		      <0x0 0x1ccb0000 0x10000>,
		      <0x0 0x1ccf0000 0x10000>,
		      <0x0 0x1cd30000 0x10000>;
		reg-names = "pmu", "cmu", "bus", "s2mpu0", "s2mpu1",
			    "s2mpu2";
		samsung,secure-pd-id = <0x1cc10204>;
		#power-domain-cells = <0>;
		label = "TNR";
		status = "disabled";
	};

	/*
	 * Camera back-end processing domains.  Source: downstream Zumapro
	 * pd-rgbp@15462100 and pd-yuvp@15462200.  MCFP lives in BLK_RGBP;
	 * YUVP is a separate domain.  Their dedicated compatibles replay the
	 * source-backed CMU/Q-channel state and open the S2MPUs at the genpd
	 * power-on boundary, before any System MMU can resume.  Keep both passive
	 * until the native BE-core driver owns the processing-block resets.
	 */
	pd_rgbp: power-domain@15462100 {
		compatible = "google,zumapro-rgbp-pd";
		reg = <0x0 0x15462100 0x20>,
		      <0x0 0x1c400000 0x10000>,
		      <0x0 0x1c420000 0x404>,
		      <0x0 0x1c4d0000 0x10000>,
		      <0x0 0x1c510000 0x10000>;
		reg-names = "pmu", "cmu", "bus", "s2mpu0", "s2mpu1";
		samsung,secure-pd-id = <0x1c410204>;
		#power-domain-cells = <0>;
		label = "RGBP";
		status = "disabled";
	};

	pd_yuvp: power-domain@15462200 {
		compatible = "google,zumapro-yuvp-pd";
		reg = <0x0 0x15462200 0x20>,
		      <0x0 0x1c800000 0x10000>,
		      <0x0 0x1c820000 0x10c>,
		      <0x0 0x1c8a0000 0x10000>;
		reg-names = "pmu", "cmu", "bus", "s2mpu0";
		samsung,secure-pd-id = <0x1c810204>;
		#power-domain-cells = <0>;
		label = "YUVP";
		status = "disabled";
	};

	/*
	 * BLK_ISPFE is the camera receive complex: the CSIS link/PHY block, the
	 * ISPFE front end and its PDMA.  Source: downstream
	 * research/dumped.dts:2892-2901 (pd-ispfe@15462480: need_smc
	 * 0x1c010204, cmu_id 0x1c000000).
	 *
	 * Unlike the display and G3D domains this one is neither always-on nor
	 * disabled: the driver powers it up when it opens the block, and
	 * exynos_pd_probe() reads the live PMU state before pm_genpd_init(), so
	 * a domain found off is registered off.  Whether it *is* off when the
	 * kernel takes over has not been measured, and it matters: if the
	 * bootloader leaves it powered (as it does for DPU and G3D),
	 * genpd_power_off_unused() will run the off-sequence against it at
	 * late_initcall_sync, which no zumapro domain has yet done on real
	 * silicon.  The sequence matches downstream's ispfe_off[] exactly --
	 * CMU CONTROLLER_OPTION bit 24 clear, then PMU 0x2480 bit 0 clear --
	 * so it should be safe, but it is not proven.
	 *
	 * Powering the domain does NOT bring CMU_ISPFE up.  Downstream's
	 * ispfe_on[] is two PMU accesses; the CMU is programmed separately by
	 * pmucal_rae_restore_seq() replaying 51 saved registers into
	 * 0x1c000000 -- the NOC mux user at +0x600, two dividers at
	 * +0x1800/+0x1804, and a QCH_CON run from +0x301c that includes the
	 * block's own Q-channel and one per CSIS link.  exynos_pd_power() only
	 * writes the CONTROLLER_OPTION at +0x800, so the rest is the ISPFE
	 * driver's job.  (The downstream LWIS node's UMUX_CLKCMU_ISPFE is not a
	 * CMU_TOP gate to add: in an unfiltered capture of a whole camera
	 * session the only CMU_TOP writes are the CIS_CLK Q-channels, which are
	 * the sensor master clocks.)
	 */
	pd_ispfe: power-domain@15462480 {
		compatible = "google,zumapro-pd";
		reg = <0x0 0x15462480 0x20>,
		      <0x0 0x1c000800 0x4>;
		reg-names = "pmu", "cmu";
		samsung,secure-pd-id = <0x1c010204>;
		#power-domain-cells = <0>;
		label = "ISPFE";
	};

	/*
	 * BLK_HSI1 hosts the modem's PCIe CH0 root complex (Gen3 x2).
	 * Downstream leaves its exynos-pd node disabled (the domain is never
	 * kernel-managed there, and ACPM has a dedicated SYS_SLEEP_HSI1ON
	 * suspend mode for when the modem link stays up), so model it
	 * always-on: if the bootloader hands the domain over powered this is
	 * a no-op, and if not, genpd powers it up before the CMU_HSI1/PCIe
	 * probes touch the block.  PMU offset and secure ID are from
	 * research/dumped.dts:2927-2936 (pd-hsi1@15462B00: need_smc
	 * 0x12010204, cmu_id 0x12000000).
	 */
	pd_hsi1: power-domain@15462b00 {
		compatible = "google,zumapro-pd";
		reg = <0x0 0x15462b00 0x20>,
		      <0x0 0x12000800 0x4>;
		reg-names = "pmu", "cmu";
		samsung,secure-pd-id = <0x12010204>;
		samsung,always-on;
		#power-domain-cells = <0>;
		label = "HSI1";
	};

	soc: soc@0 {
		compatible = "simple-bus";
		#address-cells = <1>;
		#size-cells = <1>;

		/*
		 * Source: bus shape follows upstream GS101 in gs101.dtsi:529-532.
		 * The 0x40000000 span covers the MMIO addresses used below from the
		 * downstream dump.  The second window passes through the PCIe CH1
		 * outbound + ECAM region at 0x6000_0000..0x6100_0000 (the pcie@13120000
		 * "config" reg and "ranges" memory window) which lives above the first
		 * span; without it of_translate_address() returns OF_BAD_ADDR for those.
		 */
		ranges = <0x0 0x0 0x0 0x40000000>,
			 /*
			  * PCIe CH0 (modem) outbound + ECAM window: the
			  * pcie@12100000 "config" reg (0x40ffe000) and its
			  * memory window (CPU 0x40000000 -> PCI 0x14e00000)
			  * start exactly at the top of the first span.
			  */
			 <0x40000000 0x0 0x40000000 0x1000000>,
			 <0x60000000 0x0 0x60000000 0x1000000>;

		/*
		 * Source: downstream CMU_TOP block base/size and PERIC0 parent
		 * registers are from the Zuma cmucal-sfr.c tables.  This first
		 * upstream clock slice only exposes the PERIC0 feeds used by the
		 * already-working debug UART.
		 */
		cmu_top: clock-controller@26040000 {
			compatible = "google,zumapro-cmu-top";
			reg = <0x26040000 0x10000>;
			#clock-cells = <1>;
			clocks = <&ext_24_5m>;
			clock-names = "oscclk";
		};

		/* MFC NoC QoS ports, from the downstream Zuma BTS description. */
		bts: interconnect@26c48380 {
			compatible = "google,zumapro-bts";
			reg = <0x26c48380 0x80>, <0x26c48400 0x80>;
			reg-names = "mfc0", "mfc1";
			clocks = <&acpm_ipc ZUMAPRO_CLK_ACPM_DVFS_MIF>,
				 <&acpm_ipc ZUMAPRO_CLK_ACPM_DVFS_INT>;
			clock-names = "mif", "int";
			#interconnect-cells = <1>;
			status = "disabled";
		};

		/*
		 * CMU_MISC clocks the Multi-Core Timer (MCT).  Modelled only far
		 * enough to gate the MCT register-access pclk; the NOC USER mux
		 * selects either the oscillator or the CMU_TOP MISC feed.
		 */
		cmu_misc: clock-controller@10010000 {
			compatible = "google,zumapro-cmu-misc";
			reg = <0x10010000 0x10000>;
			#clock-cells = <1>;
			clocks = <&ext_24_5m>,
				 <&cmu_top CLK_DOUT_CMU_MISC_NOC>;
			clock-names = "oscclk", "bus";
		};

		/*
		 * The two TMU instances.  The firmware owns the TMU: the AP maps
		 * only the INTPEND registers and takes the interrupt, and does
		 * temperatures, thresholds and IRQ acknowledge over ACPM IPC
		 * channel 9 (hardware-verified,
		 * research/tracing/acpm-channels.md).
		 *
		 * The thermal-sensor cell is the index local to each instance;
		 * the driver maps it to the global firmware tzid.  Sources:
		 * downstream BIG/MID/LITTLE@100A0000 and G3D/ISP/TPU/AUR@100B0000
		 * (research/dumped.dts:17702-17878).
		 *
		 * No clocks property: the TMU APB PCLK gates the INTPEND reads,
		 * but CMU_MISC has no TMU gates modelled yet and the bootloader
		 * leaves the clock running.  See docs/subsystems/power/reference/thermal-acpm-tmu.md.
		 */
		tmu_top: tmu@100a0000 {
			compatible = "google,zumapro-tmu-top";
			reg = <0x100a0000 0x800>;
			interrupts = <GIC_SPI 787 IRQ_TYPE_LEVEL_HIGH 0>;
			samsung,acpm-ipc = <&acpm_ipc>;
			#thermal-sensor-cells = <1>;
		};

		tmu_sub: tmu@100b0000 {
			compatible = "google,zumapro-tmu-sub";
			reg = <0x100b0000 0x800>;
			interrupts = <GIC_SPI 804 IRQ_TYPE_LEVEL_HIGH 0>;
			samsung,acpm-ipc = <&acpm_ipc>;
			#thermal-sensor-cells = <1>;
		};

		/*
		 * CMU_HSI0 feeds the USB block (DWC3 + USB-DRD/eUSB PHY).  The
		 * base and the CMU_TOP NOC feed come from research/dumped.dts and
		 * the downstream zuma cmucal tables.  The USB reference clock is
		 * not a CMU_TOP feed; it is derived from the CMU_HSI0-internal
		 * PLL_USB (see clk-zumapro.c and docs/archive/usb/needs-hardware-2026-05.md).
		 * USB is already running at fastboot handoff.
		 */
		cmu_hsi0: clock-controller@11000000 {
			compatible = "google,zumapro-cmu-hsi0";
			reg = <0x11000000 0x10000>;
			#clock-cells = <1>;
			clocks = <&ext_24_5m>,
				 <&cmu_top CLK_DOUT_CMU_HSI0_NOC>,
				 <&cmu_top CLK_DOUT_CMU_HSI0_PERI>;
			clock-names = "oscclk", "noc", "peri";
		};

		/*
		 * Source: display CMU bases come from dumped.dts pd-dpub,
		 * pd-dpuf0, and pd-dpuf1 cmu_id values; register offsets come
		 * from downstream Zuma CMUCAL.  TRACE NEEDED: validate selected
		 * display mux parents/rates under Linux before allowing DRM to
		 * program those clocks.
		 */
		cmu_dpub: clock-controller@19400000 {
			compatible = "google,zumapro-cmu-dpub";
			reg = <0x19400000 0x10000>;
			#clock-cells = <1>;
			clocks = <&ext_24_5m>,
				 <&cmu_top CLK_DOUT_CMU_DPUB_NOC>,
				 <&cmu_top CLK_DOUT_CMU_DPUB_DSIM>;
			clock-names = "oscclk", "bus", "dsim";
			power-domains = <&pd_dpub>;
			status = "disabled";
		};

		cmu_dpuf0: clock-controller@19800000 {
			compatible = "google,zumapro-cmu-dpuf0";
			reg = <0x19800000 0x8000>;
			#clock-cells = <1>;
			clocks = <&ext_24_5m>,
				 <&cmu_top CLK_DOUT_CMU_DPUF0_NOC>;
			clock-names = "oscclk", "bus";
			power-domains = <&pd_dpuf0>;
			status = "disabled";
		};

		cmu_dpuf1: clock-controller@19c00000 {
			compatible = "google,zumapro-cmu-dpuf1";
			reg = <0x19c00000 0x8000>;
			#clock-cells = <1>;
			clocks = <&ext_24_5m>,
				 <&cmu_top CLK_DOUT_CMU_DPUF1_NOC>;
			clock-names = "oscclk", "bus";
			power-domains = <&pd_dpuf1>;
			status = "disabled";
		};

		cmu_mfc: clock-controller@1a400000 {
			compatible = "google,zumapro-cmu-mfc";
			reg = <0x1a400000 0x10000>;
			#clock-cells = <1>;
			clocks = <&ext_24_5m>,
				 <&cmu_top CLK_DOUT_CMU_MFC_MFC>;
			clock-names = "oscclk", "bus";
			power-domains = <&pd_mfc>;
			samsung,sysreg = <&sysreg_mfc>;
			status = "disabled";
		};

		/*
		 * CMU_MFC accesses this only while the domain is active. A clock
		 * reference here would pin the runtime-PM clock provider on.
		 */
		sysreg_mfc: syscon@1a420000 {
			compatible = "google,zumapro-mfc-sysreg", "syscon";
			reg = <0x1a420000 0x1000>;
			status = "disabled";
		};

		/* One SysMMU with two PMMUs, both using stream configuration 0x138. */
		sysmmu_mfc: iommu@1a470000 {
			compatible = "samsung,sysmmu-v9";
			reg = <0x1a470000 0x10000>;
			clocks = <&cmu_mfc CLK_GOUT_MFC_SYSMMU_S0_CLK>;
			clock-names = "gate";
			interrupts = <GIC_SPI 518 IRQ_TYPE_LEVEL_HIGH 0>,
				     <GIC_SPI 519 IRQ_TYPE_LEVEL_HIGH 0>;
			power-domains = <&pd_mfc>;
			samsung,qos = <15>;
			samsung,secure-irq;
			samsung,secure-base = <0x1a480000>;
			samsung,port-name = "MFC";
			samsung,pmmu0-default-stream = <0x138>;
			samsung,pmmu1-default-stream = <0x138>;
			#iommu-cells = <0>;
			access-controllers = <&s2mpu_mfc>;
			status = "disabled";
		};

		/* MFC's stage-2 protection unit shares the SysMMU clock domain. */
		s2mpu_mfc: access-controller@1a4a0000 {
			compatible = "google,zumapro-s2mpu";
			reg = <0x1a4a0000 0x10000>;
			clocks = <&cmu_mfc CLK_GOUT_MFC_SYSMMU_S0_CLK>;
			clock-names = "bus";
			interrupts = <GIC_SPI 520 IRQ_TYPE_LEVEL_HIGH 0>;
			power-domains = <&pd_mfc>;
			#access-controller-cells = <0>;
			status = "disabled";
		};

		mfc: codec@1a4d0000 {
			compatible = "google,zumapro-mfc";
			reg = <0x1a4d0000 0x10000>;
			interrupts = <GIC_SPI 515 IRQ_TYPE_LEVEL_HIGH 0>;
			clocks = <&cmu_mfc CLK_GOUT_MFC_MFC_ACLK>,
				 <&acpm_ipc ZUMAPRO_CLK_ACPM_DVFS_MFC>;
			clock-names = "mfc", "sclk_mfc";
			interconnects = <&bts ZUMAPRO_BTS_MASTER_MFC
					 &bts ZUMAPRO_BTS_SLAVE_MIF>;
			interconnect-names = "memory";
			power-domains = <&pd_mfc>;
			iommus = <&sysmmu_mfc>;
			status = "disabled";
		};


		/*
		 * Source: downstream sysmmu_dpuf0/sysmmu_dpuf1 in
		 * zumapro-sysmmu.dtsi and research/dumped.dts:882-916.  These
		 * are Samsung System MMU v9 blocks, not compatible with the
		 * legacy mainline Exynos System MMU driver.  Keep them disabled
		 * until the v9 driver can program the PMMU stream tables and
		 * secure fault registers.
		 */
		sysmmu_dpuf0: iommu@19840000 {
			compatible = "samsung,sysmmu-v9";
			reg = <0x19840000 0x10000>;
			interrupts = <GIC_SPI 277 IRQ_TYPE_LEVEL_HIGH 0>,
				     <GIC_SPI 278 IRQ_TYPE_LEVEL_HIGH 0>;
			power-domains = <&pd_dpuf0>;
			samsung,qos = <15>;
			samsung,secure-irq;
			samsung,secure-base = <0x19850000>;
			samsung,port-name = "DPU F0";
			samsung,pmmu0-default-stream = <0x600014a>;
			samsung,pmmu0-stream-property =
				<0x01 0x600014a 0x101 0x40 0x7f>,
				<0x02 0xa01011b 0x101 0x01 0x7f>,
				<0x03 0xa01011b 0x101 0x41 0x7f>,
				<0x04 0x2015a 0x101 0x08 0x7f>,
				<0x05 0x2015a 0x101 0x48 0x7f>,
				<0x06 0x103015a 0x101 0x0c 0x7f>,
				<0x07 0x103015a 0x101 0x4c 0x7f>,
				<0x08 0xb04011b 0x101 0x09 0x7f>,
				<0x09 0xb04011b 0x101 0x49 0x7f>,
				<0x0a 0xc05010b 0x101 0x0d 0x7f>,
				<0x0b 0xc05010b 0x101 0x4d 0x7f>,
				<0x0c 0x706013a 0x101 0x10 0x7f>,
				<0x0d 0x706010a 0x101 0x50 0x7f>,
				<0x0e 0xd07011b 0x101 0x11 0x7f>,
				<0x0f 0xd07011b 0x101 0x51 0x7f>,
				<0x10 0x208015a 0x101 0x18 0x7f>,
				<0x11 0x208015a 0x101 0x58 0x7f>,
				<0x12 0x309015a 0x101 0x1c 0x7f>,
				<0x13 0x309015a 0x101 0x5c 0x7f>,
				<0x14 0xe0a011b 0x101 0x19 0x7f>,
				<0x15 0xe0a011b 0x101 0x59 0x7f>,
				<0x16 0xf0b010b 0x101 0x1d 0x7f>,
				<0x17 0xf0b010b 0x101 0x5d 0x7f>,
				<0x18 0x140c010b 0x101 0x13 0x7f>,
				<0x19 0x140c010b 0x101 0x53 0x7f>,
				<0x1a 0x150d010b 0x101 0x0b 0x7f>,
				<0x1b 0x150d010b 0x101 0x4b 0x7f>,
				<0x1c 0x160e010b 0x201 0x00 0x7f>,
				<0x1d 0x160e010b 0x201 0x40 0x7f>,
				<0x1e 0x170f010b 0x201 0x10 0x7f>,
				<0x1f 0x170f010b 0x201 0x50 0x7f>,
				<0x20 0x1814010b 0x201 0x04 0x7f>,
				<0x21 0x1814010b 0x201 0x44 0x7f>,
				<0x22 0x1915010b 0x201 0x14 0x7f>,
				<0x23 0x1915010b 0x201 0x54 0x7f>,
				<0x24 0x1010011b 0x101 0x21 0x7f>,
				<0x25 0x1010011b 0x101 0x61 0x7f>,
				<0x26 0x1111011b 0x101 0x29 0x7f>,
				<0x27 0x1111011b 0x101 0x69 0x7f>,
				<0x28 0x1212010b 0x101 0x2d 0x7f>,
				<0x29 0x1212010b 0x101 0x6d 0x7f>,
				<0x2a 0x1313011b 0x101 0x31 0x7f>,
				<0x2b 0x1313011b 0x101 0x71 0x7f>;
			samsung,pmmu1-default-stream = <0x800014a>;
			samsung,pmmu1-stream-property =
				<0x01 0x800014a 0x101 0x60 0x7f>,
				<0x02 0x1001011b 0x101 0x21 0x7f>,
				<0x03 0x1001011b 0x101 0x61 0x7f>,
				<0x04 0x402015a 0x101 0x28 0x7f>,
				<0x05 0x402015a 0x101 0x68 0x7f>,
				<0x06 0x503015a 0x101 0x2c 0x7f>,
				<0x07 0x503015a 0x101 0x6c 0x7f>,
				<0x08 0x1104011b 0x101 0x29 0x7f>,
				<0x09 0x1104011b 0x101 0x69 0x7f>,
				<0x0a 0x1205010b 0x101 0x2d 0x7f>,
				<0x0b 0x1205010b 0x101 0x6d 0x7f>,
				<0x0c 0x906014a 0x101 0x30 0x7f>,
				<0x0d 0x906014a 0x101 0x70 0x7f>,
				<0x0e 0x1307011b 0x101 0x31 0x7f>,
				<0x0f 0x1307011b 0x101 0x71 0x7f>,
				<0x10 0x1a08011a 0x101 0x2b 0x7f>,
				<0x11 0x1a08011a 0x101 0x6b 0x7f>,
				<0x12 0xa09011b 0x101 0x01 0x7f>,
				<0x13 0xa09011b 0x101 0x41 0x7f>,
				<0x14 0xb0a011b 0x101 0x09 0x7f>,
				<0x15 0xb0a011b 0x101 0x49 0x7f>,
				<0x16 0xc0b011b 0x101 0x0d 0x7f>,
				<0x17 0xc0b011b 0x101 0x4d 0x7f>,
				<0x18 0xd0c011b 0x101 0x11 0x7f>,
				<0x19 0xd0c011b 0x101 0x51 0x7f>,
				<0x1a 0xe0d011b 0x101 0x19 0x7f>,
				<0x1b 0xe0d011b 0x101 0x59 0x7f>,
				<0x1c 0xf0e011b 0x101 0x1d 0x7f>,
				<0x1d 0xf0e011b 0x101 0x5d 0x7f>;
			#iommu-cells = <0>;
			status = "disabled";
		};

		sysmmu_dpuf1: iommu@19c40000 {
			compatible = "samsung,sysmmu-v9";
			reg = <0x19c40000 0x10000>;
			interrupts = <GIC_SPI 304 IRQ_TYPE_LEVEL_HIGH 0>,
				     <GIC_SPI 305 IRQ_TYPE_LEVEL_HIGH 0>;
			power-domains = <&pd_dpuf1>;
			samsung,qos = <15>;
			samsung,secure-irq;
			samsung,secure-base = <0x19c50000>;
			samsung,port-name = "DPU F1";
			samsung,pmmu0-default-stream = <0x600014a>;
			samsung,pmmu0-stream-property =
				<0x01 0x600014a 0x101 0x40 0x7f>,
				<0x02 0xa01011b 0x101 0x01 0x7f>,
				<0x03 0xa01011b 0x101 0x41 0x7f>,
				<0x04 0x2015a 0x101 0x08 0x7f>,
				<0x05 0x2015a 0x101 0x48 0x7f>,
				<0x06 0x103015a 0x101 0x0c 0x7f>,
				<0x07 0x103015a 0x101 0x4c 0x7f>,
				<0x08 0xb04011b 0x101 0x09 0x7f>,
				<0x09 0xb04011b 0x101 0x49 0x7f>,
				<0x0a 0xc05010b 0x101 0x0d 0x7f>,
				<0x0b 0xc05010b 0x101 0x4d 0x7f>,
				<0x0c 0x706013a 0x101 0x10 0x7f>,
				<0x0d 0x706010a 0x101 0x50 0x7f>,
				<0x0e 0xd07011b 0x101 0x11 0x7f>,
				<0x0f 0xd07011b 0x101 0x51 0x7f>,
				<0x10 0x208015a 0x101 0x18 0x7f>,
				<0x11 0x208015a 0x101 0x58 0x7f>,
				<0x12 0x309015a 0x101 0x1c 0x7f>,
				<0x13 0x309015a 0x101 0x5c 0x7f>,
				<0x14 0xe0a011b 0x101 0x19 0x7f>,
				<0x15 0xe0a011b 0x101 0x59 0x7f>,
				<0x16 0xf0b010b 0x101 0x1d 0x7f>,
				<0x17 0xf0b010b 0x101 0x5d 0x7f>,
				<0x18 0x140c010b 0x101 0x13 0x7f>,
				<0x19 0x140c010b 0x101 0x53 0x7f>,
				<0x1a 0x150d010b 0x101 0x0b 0x7f>,
				<0x1b 0x150d010b 0x101 0x4b 0x7f>,
				<0x1c 0x160e010b 0x201 0x00 0x7f>,
				<0x1d 0x160e010b 0x201 0x40 0x7f>,
				<0x1e 0x170f010b 0x201 0x10 0x7f>,
				<0x1f 0x170f010b 0x201 0x50 0x7f>,
				<0x20 0x1814010b 0x201 0x04 0x7f>,
				<0x21 0x1814010b 0x201 0x44 0x7f>,
				<0x22 0x1915010b 0x201 0x14 0x7f>,
				<0x23 0x1915010b 0x201 0x54 0x7f>,
				<0x24 0x1010011b 0x101 0x21 0x7f>,
				<0x25 0x1010011b 0x101 0x61 0x7f>,
				<0x26 0x1111011b 0x101 0x29 0x7f>,
				<0x27 0x1111011b 0x101 0x69 0x7f>,
				<0x28 0x1212010b 0x101 0x2d 0x7f>,
				<0x29 0x1212010b 0x101 0x6d 0x7f>,
				<0x2a 0x1313011b 0x101 0x31 0x7f>,
				<0x2b 0x1313011b 0x101 0x71 0x7f>;
			samsung,pmmu1-default-stream = <0x800014a>;
			samsung,pmmu1-stream-property =
				<0x01 0x800014a 0x101 0x60 0x7f>,
				<0x02 0x1001011b 0x101 0x21 0x7f>,
				<0x03 0x1001011b 0x101 0x61 0x7f>,
				<0x04 0x402015a 0x101 0x28 0x7f>,
				<0x05 0x402015a 0x101 0x68 0x7f>,
				<0x06 0x503015a 0x101 0x2c 0x7f>,
				<0x07 0x503015a 0x101 0x6c 0x7f>,
				<0x08 0x1104011b 0x101 0x29 0x7f>,
				<0x09 0x1104011b 0x101 0x69 0x7f>,
				<0x0a 0x1205010b 0x101 0x2d 0x7f>,
				<0x0b 0x1205010b 0x101 0x6d 0x7f>,
				<0x0c 0x906014a 0x101 0x30 0x7f>,
				<0x0d 0x906014a 0x101 0x70 0x7f>,
				<0x0e 0x1307011b 0x101 0x31 0x7f>,
				<0x0f 0x1307011b 0x101 0x71 0x7f>,
				<0x10 0x1a08011a 0x101 0x2b 0x7f>,
				<0x11 0x1a08011a 0x101 0x6b 0x7f>,
				<0x12 0xa09011b 0x101 0x01 0x7f>,
				<0x13 0xa09011b 0x101 0x41 0x7f>,
				<0x14 0xb0a011b 0x101 0x09 0x7f>,
				<0x15 0xb0a011b 0x101 0x49 0x7f>,
				<0x16 0xc0b011b 0x101 0x0d 0x7f>,
				<0x17 0xc0b011b 0x101 0x4d 0x7f>,
				<0x18 0xd0c011b 0x101 0x11 0x7f>,
				<0x19 0xd0c011b 0x101 0x51 0x7f>,
				<0x1a 0xe0d011b 0x101 0x19 0x7f>,
				<0x1b 0xe0d011b 0x101 0x59 0x7f>,
				<0x1c 0xf0e011b 0x101 0x1d 0x7f>,
				<0x1d 0xf0e011b 0x101 0x5d 0x7f>;
			#iommu-cells = <0>;
			status = "disabled";
		};

		/*
		 * Source: downstream sysmmu@19090000 in research/dumped.dts:1266.
		 * AoC's Samsung System MMU v9.  The boot log confirms the pairing:
		 * "aoc 17000000.aoc: has sysmmu 19090000.sysmmu".  reg, both fault
		 * interrupts, secure-base and the PMMU0 stream table are verbatim
		 * from the dump.  No power-domains: the dump node has none and no
		 * pd_aoc label exists.  The dump's sysmmu,leave-enabled-on-suspend
		 * is dropped -- the v9 driver never reads it and the binding is
		 * additionalProperties:false.  Left enabled to match the dump.
		 */
		sysmmu_aoc: iommu@19090000 {
			compatible = "samsung,sysmmu-v9";
			reg = <0x19090000 0x10000>;
			interrupts = <GIC_SPI 132 IRQ_TYPE_LEVEL_HIGH 0>,
				     <GIC_SPI 133 IRQ_TYPE_LEVEL_HIGH 0>;
			samsung,qos = <15>;
			samsung,secure-irq;
			samsung,secure-base = <0x190a0000>;
			samsung,port-name = "AOC";
			samsung,pmmu0-default-stream = <0x10b>;
			samsung,pmmu0-stream-property =
				<0x01 0x100010b 0x301 0x02 0x3f>,
				<0x02 0x10b 0x301 0x03 0x3f>,
				<0x03 0x10b 0x301 0x04 0x3f>,
				<0x04 0x10b 0x301 0x05 0x3f>,
				<0x05 0x10b 0x301 0x06 0x3f>,
				<0x06 0x10b 0x301 0x09 0x3f>,
				<0x07 0x10b 0x301 0x0a 0x3f>,
				<0x08 0x10b 0x301 0x0b 0x3f>,
				<0x09 0x10b 0x301 0x0c 0x3f>,
				<0x0a 0x10b 0x301 0x0d 0x3f>,
				<0x0b 0x10b 0x301 0x0e 0x3f>,
				<0x0c 0x10b 0x301 0x20 0x3f>,
				<0x0d 0x10b 0x301 0x21 0x3f>,
				<0x0e 0x10b 0x301 0x22 0x3f>,
				<0x0f 0x10b 0x301 0x23 0x3f>,
				<0x10 0x10b 0x301 0x24 0x3f>,
				<0x11 0x10b 0x301 0x25 0x3f>,
				<0x12 0x10b 0x301 0x26 0x3f>,
				<0x13 0x10b 0x301 0x27 0x3f>,
				<0x14 0x10b 0x301 0x28 0x3f>,
				<0x15 0x10b 0x301 0x30 0x3f>,
				<0x16 0x10b 0x301 0x31 0x3f>,
				<0x17 0x10b 0x301 0x32 0x3f>,
				<0x18 0x10b 0x301 0x33 0x3f>,
				<0x19 0x10b 0x301 0x34 0x3f>,
				<0x1a 0x10b 0x301 0x35 0x3f>,
				<0x1b 0x10b 0x301 0x36 0x3f>,
				<0x1c 0x10b 0x301 0x37 0x3f>,
				<0x1d 0x10b 0x301 0x38 0x3f>;
			#iommu-cells = <0>;
		};

		/*
		 * Source: downstream drmdpp0/drmdecon0 in
		 * research/dumped.dts:222-235 and 585-628.  These are
		 * topology-only for now; keep disabled until the passive
		 * scaffold has been followed by trace-validated register access.
		 */
		dpp0: dpp@19900000 {
			compatible = "google,zumapro-dpp";
			reg = <0x19900000 0x1000>,
			      <0x19930000 0x1000>,
			      <0x19940000 0x4000>,
			      <0x19950000 0x1000>,
			      <0x19960000 0x1000>,
			      <0x19980000 0x1000>;
			reg-names = "dma", "dpp", "scl_coef", "sramc",
				    "hdr_comm", "hdr";
			interrupts = <GIC_SPI 256 IRQ_TYPE_LEVEL_HIGH 0>,
				     <GIC_SPI 265 IRQ_TYPE_LEVEL_HIGH 0>;
			interrupt-names = "dma", "dpp";
			google,dpp-attributes = <0x6d0867>; /* downstream attr */
			google,axi-port = <0>; /* downstream port */
			google,scale-down = <4>; /* downstream scale_down */
			google,scale-up = <8>; /* downstream scale_up */
			google,dpp-id = <0>; /* downstream dpp,id */
			status = "disabled";
		};

		decon0: display-controller@19470000 {
			compatible = "google,zumapro-decon";
			reg = <0x19470000 0x6000>,
			      <0x19480000 0xe000>,
			      <0x19490000 0x10000>,
			      <0x194a0000 0xe000>,
			      <0x194d0000 0xf000>,
			      <0x194f0000 0x10000>,
			      <0x1990e000 0x1000>;
			reg-names = "main", "win", "sub", "wincon", "dqe",
				    "dqe-cgc", "cgc-dma";
			interrupts = <GIC_SPI 243 IRQ_TYPE_LEVEL_HIGH 0>,
				     <GIC_SPI 242 IRQ_TYPE_LEVEL_HIGH 0>,
				     <GIC_SPI 241 IRQ_TYPE_LEVEL_HIGH 0>,
				     <GIC_SPI 240 IRQ_TYPE_LEVEL_HIGH 0>,
				     <GIC_SPI 239 IRQ_TYPE_LEVEL_HIGH 0>,
				     <GIC_SPI 255 IRQ_TYPE_LEVEL_HIGH 0>;
			interrupt-names = "frame_start", "frame_done", "extra",
					  "dimming_start", "dimming_end",
					  "cgc-dma";
			google,decon-id = <0>; /* downstream decon,id */
			google,cgc-dma-id = <18>; /* downstream cgc-dma,id */
			iommus = <&sysmmu_dpuf0>, <&sysmmu_dpuf1>;
			samsung,iommu-group = <&iommu_group_dpu>;
			samsung,tzmp;
			power-domains = <&pd_dpuf0>, <&pd_dpuf1>;
			google,max-windows = <14>; /* downstream max_win */
			dpps = <&dpp0>;
			status = "disabled";

			ports {
				#address-cells = <1>;
				#size-cells = <0>;

				port@0 {
					reg = <0>;

					decon0_out: endpoint {
						remote-endpoint = <&dsi0_in>;
					};
				};
			};
		};

		/*
		 * Source: downstream disp_ss@19421000 in research/dumped.dts:476.
		 * The D-PHY driver uses offset 0x8 to hand DPHY reset ownership to
		 * software and release M_RESETN_M0.  TRACE NEEDED: validate those
		 * sysreg writes during the first DSIM enable/disable experiment.
		 */
		sysreg_dpub: syscon@19421000 {
			compatible = "google,zumapro-disp-sysreg", "syscon";
			reg = <0x19421000 0x10>;
			clocks = <&cmu_dpub CLK_GOUT_DPUB_SYSREG_PCLK>;
			power-domains = <&pd_dpub>;
			status = "disabled";
		};

		/*
		 * Source: downstream dphy_m4s4_dsim0@19460000 plus the DSIM-owned
		 * "dphy-extra" and "dphy" ranges in research/dumped.dts:483-494.
		 * Mainline keeps the DSIM register window separate and gives these
		 * PHY windows to the PHY provider to avoid overlapping resources.
		 */
		mipi_phy_dsim0: phy@19460000 {
			compatible = "google,zumapro-mipi-dphy";
			reg = <0x19460000 0x100>,
			      <0x19460100 0x700>;
			reg-names = "bias", "dphy";
			#phy-cells = <1>;
			clocks = <&ext_24_5m>;
			clock-names = "ref";
			samsung,sysreg = <&sysreg_dpub>;
			samsung,id = <0>;
			power-domains = <&pd_dpub>;
			status = "disabled";
		};

		/*
		 * Source: downstream drmdsim@19440000 in research/dumped.dts:491.
		 * The downstream binding uses phy-names = "dsim_dphy"; the mainline
		 * binding uses the common "dsim" name while the driver keeps a
		 * downstream-compatible fallback.
		 */
		dsi0: dsi@19440000 {
			compatible = "google,zumapro-mipi-dsi";
			reg = <0x19440000 0x300>;
			interrupts = <GIC_SPI 252 IRQ_TYPE_LEVEL_HIGH 0>;
			clocks = <&cmu_dpub CLK_GOUT_DPUB_DSIM0_ALVCLK>,
				 <&cmu_dpub CLK_GOUT_DPUB_DSIM0_OSCCLK>;
			clock-names = "bus", "osc";
			power-domains = <&pd_dpub>;
			phys = <&mipi_phy_dsim0 0>;
			phy-names = "dsim";
			samsung,pll-clock-frequency = <24576000>;
			samsung,burst-clock-frequency = <1102000000>;
			samsung,esc-clock-frequency = <20000000>;
			vddcore-supply = <&reg_placeholder>;
			vddio-supply = <&reg_placeholder>;
			#address-cells = <1>;
			#size-cells = <0>;
			status = "disabled";

			panel: panel@0 {
				compatible = "google,gs-tg4c";
				reg = <0>;
				reset-gpios = <&gpp0 0 GPIO_ACTIVE_HIGH>;
				te-gpios = <&gpp0 3 GPIO_ACTIVE_HIGH>;
				pinctrl-names = "default";
				pinctrl-0 = <&disp_te_pri_on>;
				vci-supply = <&reg_placeholder>;
				vddi-supply = <&reg_placeholder>;
				vddd-supply = <&reg_placeholder>;
				status = "disabled";

				port {
					panel_in: endpoint {
						remote-endpoint = <&dsi0_out>;
					};
				};
			};

			ports {
				#address-cells = <1>;
				#size-cells = <0>;

				port@0 {
					reg = <0>;

					dsi0_in: endpoint {
						remote-endpoint = <&decon0_out>;
					};
				};

				port@1 {
					reg = <1>;

					dsi0_out: endpoint {
						data-lanes = <1 2 3 4>;
						remote-endpoint = <&panel_in>;
					};
				};
			};
		};

		/*
		 * GPU: Mali-G715 (Valhall CSF, arch 11.2, product tTUx), driven by
		 * mainline panthor.  Register base, interrupts and power domains are
		 * the downstream mali@1F000000 node.  Disabled here; enabled per
		 * board in zumapro-tegu.dts once the CSF firmware blob is staged.
		 *
		 * Clocks are ACPM-backed.  The GPU has two independent ACPM DVFS
		 * domains, each with its own PLL and its own S2MPG15 rail: G3D
		 * (ACPM id 7, PLL_G3D, the shader stacks) and G3DL2 (id 8,
		 * PLL_G3D_L2, the top-level/L2 block).  Downstream drives them as a
		 * paired ladder, and only the G3D column is unique per operating
		 * point -- the G3DL2 column repeats (four shader points share L2
		 * 900 MHz).  The OPP core keys on clock index 0, so index 0 must be
		 * G3D; G3DL2 rides along as "coregroup".
		 *
		 * No mali-supply: the S2MPG15 GPU bucks are regulator-always-on and
		 * ACPM applies the ASV/ECT voltage for the frequency it is asked
		 * for, so every OPP is frequency-only and the AP never programs a
		 * GPU rail.
		 */
		gpu: gpu@1f000000 {
			compatible = "google,zumapro-mali", "arm,mali-valhall-csf";
			reg = <0x1f000000 0x480000>;
			#cooling-cells = <2>;
			clocks = <&acpm_ipc ZUMAPRO_CLK_ACPM_DVFS_G3D>,
				 <&acpm_ipc ZUMAPRO_CLK_ACPM_DVFS_G3DL2>;
			clock-names = "core", "coregroup";
			interrupts = <GIC_SPI 347 IRQ_TYPE_LEVEL_HIGH 0>,
				     <GIC_SPI 348 IRQ_TYPE_LEVEL_HIGH 0>,
				     <GIC_SPI 346 IRQ_TYPE_LEVEL_HIGH 0>;
			interrupt-names = "job", "mmu", "gpu";
			operating-points-v2 = <&gpu_opp_table>;
			power-domains = <&pd_g3d>, <&pd_embedded_g3d>;
			power-domain-names = "top", "cores";
			status = "disabled";

			/*
			 * The downstream 14-row DVFS table, whose top row is
			 * this part's declared 940 MHz shader maximum.
			 * Each row carries both rates, G3D first and G3DL2
			 * second, because ACPM moves only the domain it is asked
			 * for: requesting 302 MHz on G3D leaves PLL_G3D_L2 at its
			 * 160 MHz idle setting, so the pairing has to come from
			 * here.
			 *
			 * opp-microwatt is what the Energy Model is built from,
			 * and these are MEASURED: mean ODPM S2S_VDD_G3D over a
			 * 10 s glmark2 terrain run pinned at each rung, rounded
			 * to 10 mW, about the noise floor of the reading.  Three
			 * points came back 2-4% below the rung beneath them --
			 * inside that noise -- and were raised one step to keep
			 * the table increasing.
			 *
			 * Two known biases, both understating, which is the safe
			 * direction for a thermal budget: ODPM does not meter the
			 * L2 rail (S8S_VDD_G3D_L2 is not one of the 12 muxed
			 * channels), and the figures include whatever the
			 * compositor was doing at the time.
			 *
			 * This replaces a dynamic-power-coefficient plus invented
			 * per-OPP voltages, which underestimated the bottom rung
			 * by 4.7x -- 28 mW modelled against 135 mW measured.
			 */
			gpu_opp_table: opp-table {
				compatible = "operating-points-v2";

				opp-150000000 {
					opp-hz = /bits/ 64 <150000000>,
						 /bits/ 64 <160000000>;
					opp-microwatt = <140000>;
				};

				opp-302000000 {
					opp-hz = /bits/ 64 <302000000>,
						 /bits/ 64 <386000000>;
					opp-microwatt = <210000>;
				};

				opp-337000000 {
					opp-hz = /bits/ 64 <337000000>,
						 /bits/ 64 <430000000>;
					opp-microwatt = <240000>;
				};

				opp-376000000 {
					opp-hz = /bits/ 64 <376000000>,
						 /bits/ 64 <531000000>;
					opp-microwatt = <250000>;
				};

				opp-419000000 {
					opp-hz = /bits/ 64 <419000000>,
						 /bits/ 64 <531000000>;
					opp-microwatt = <270000>;
				};

				opp-467000000 {
					opp-hz = /bits/ 64 <467000000>,
						 /bits/ 64 <659000000>;
					opp-microwatt = <320000>;
				};

				opp-521000000 {
					opp-hz = /bits/ 64 <521000000>,
						 /bits/ 64 <659000000>;
					opp-microwatt = <350000>;
				};

				opp-580000000 {
					opp-hz = /bits/ 64 <580000000>,
						 /bits/ 64 <749000000>;
					opp-microwatt = <420000>;
				};

				opp-649000000 {
					opp-hz = /bits/ 64 <649000000>,
						 /bits/ 64 <749000000>;
					opp-microwatt = <430000>;
				};

				opp-723000000 {
					opp-hz = /bits/ 64 <723000000>,
						 /bits/ 64 <900000000>;
					opp-microwatt = <500000>;
				};

				opp-807000000 {
					opp-hz = /bits/ 64 <807000000>,
						 /bits/ 64 <900000000>;
					opp-microwatt = <550000>;
				};

				opp-850000000 {
					opp-hz = /bits/ 64 <850000000>,
						 /bits/ 64 <900000000>;
					opp-microwatt = <600000>;
				};

				opp-890000000 {
					opp-hz = /bits/ 64 <890000000>,
						 /bits/ 64 <900000000>;
					opp-microwatt = <610000>;
				};

				opp-940000000 {
					opp-hz = /bits/ 64 <940000000>,
						 /bits/ 64 <950000000>;
					opp-microwatt = <740000>;
				};
			};
		};

		/*
		 * Legacy exynos4210-mct global/local timer block.  On Zumapro its
		 * interrupts are not wired -- the L0-L7 SPIs below are actually
		 * raised by the v3 MCT block (mct_v3@100d0000), and the legacy
		 * global comparator IRQ (G0, SPI 754) never fires.  Driving it with
		 * the exynos4210-mct driver hangs deep idle (broadcast never wakes)
		 * and SMP bring-up (local timers never tick), so keep it disabled
		 * and use the v3 block instead.  Source: research/dumped.dts.
		 */
		mct: timer@10050000 {
			compatible = "samsung,exynos4210-mct";
			reg = <0x10050000 0x800>;
			clocks = <&ext_24_5m>, <&cmu_misc CLK_GOUT_MISC_MCT_PCLK>;
			clock-names = "fin_pll", "mct";
			interrupts = <GIC_SPI 754 IRQ_TYPE_LEVEL_HIGH 0>,
				     <GIC_SPI 755 IRQ_TYPE_LEVEL_HIGH 0>,
				     <GIC_SPI 756 IRQ_TYPE_LEVEL_HIGH 0>,
				     <GIC_SPI 757 IRQ_TYPE_LEVEL_HIGH 0>,
				     <GIC_SPI 758 IRQ_TYPE_LEVEL_HIGH 0>,
				     <GIC_SPI 759 IRQ_TYPE_LEVEL_HIGH 0>,
				     <GIC_SPI 760 IRQ_TYPE_LEVEL_HIGH 0>,
				     <GIC_SPI 761 IRQ_TYPE_LEVEL_HIGH 0>,
				     <GIC_SPI 762 IRQ_TYPE_LEVEL_HIGH 0>,
				     <GIC_SPI 763 IRQ_TYPE_LEVEL_HIGH 0>,
				     <GIC_SPI 764 IRQ_TYPE_LEVEL_HIGH 0>,
				     <GIC_SPI 765 IRQ_TYPE_LEVEL_HIGH 0>;
			status = "disabled";
		};

		/*
		 * v3 MCT: free-running counter + per-CPU comparators in the
		 * always-on MISC block.  The comparators keep counting across the
		 * c2 CPU power-down state in which the ARM architected timer stops,
		 * so each one is registered below the architected timer's rating and
		 * becomes its CPU's one-shot wakeup device -- no broadcast timer is
		 * needed (and this SoC has no usable global comparator).  Interrupts
		 * are the nine local lines L0-L8 (GIC_SPI 758-766); the driver uses
		 * one per possible CPU.  reg/clocks/div from downstream zuma cmucal
		 * + DT.
		 */
		mct_v3: timer@100d0000 {
			compatible = "samsung,exynos-mct-v3";
			reg = <0x100d0000 0x800>;
			clocks = <&ext_24_5m>, <&cmu_misc CLK_GOUT_MISC_MCT_PCLK>;
			clock-names = "fin_pll", "mct";
			interrupts = <GIC_SPI 758 IRQ_TYPE_LEVEL_HIGH 0>,
				     <GIC_SPI 759 IRQ_TYPE_LEVEL_HIGH 0>,
				     <GIC_SPI 760 IRQ_TYPE_LEVEL_HIGH 0>,
				     <GIC_SPI 761 IRQ_TYPE_LEVEL_HIGH 0>,
				     <GIC_SPI 762 IRQ_TYPE_LEVEL_HIGH 0>,
				     <GIC_SPI 763 IRQ_TYPE_LEVEL_HIGH 0>,
				     <GIC_SPI 764 IRQ_TYPE_LEVEL_HIGH 0>,
				     <GIC_SPI 765 IRQ_TYPE_LEVEL_HIGH 0>,
				     <GIC_SPI 766 IRQ_TYPE_LEVEL_HIGH 0>;
			div = <1>;
		};

		/*
		 * Source: GIC address, redistributor size, and PPI partitions are
		 * from research/dumped.dts:15011-15031.
		 */
		gic: interrupt-controller@10400000 {
			compatible = "arm,gic-v3";
			#address-cells = <0>;
			#interrupt-cells = <4>;
			interrupt-controller;
			reg = <0x10400000 0x10000>,
			      <0x10440000 0x200000>;
			interrupts = <GIC_PPI 9 IRQ_TYPE_LEVEL_HIGH 0>;

			ppi-partitions {
				ppi_cluster0: interrupt-partition-0 {
					affinity = <&cpu0 &cpu1 &cpu2 &cpu3 &cpu4 &cpu5 &cpu6>;
				};

				ppi_cluster1: interrupt-partition-1 {
					affinity = <&cpu7>;
				};
			};
		};

		/*
		 * Source: downstream CMU_PERIC0 block base/size is from
		 * cmucal-sfr.c.  The sysreg range is from the downstream
		 * zumapro-usi.dtsi sysreg_peric0 node.
		 */
		cmu_peric0: clock-controller@10800000 {
			compatible = "google,zumapro-cmu-peric0";
			reg = <0x10800000 0x10000>;
			#clock-cells = <1>;
			clocks = <&ext_24_5m>,
				 <&cmu_top CLK_DOUT_CMU_PERIC0_NOC>,
				 <&cmu_top CLK_DOUT_CMU_PERIC0_IP>;
			clock-names = "oscclk", "bus", "ip";
			samsung,sysreg = <&sysreg_peric0>;
		};

		sysreg_peric0: syscon@10820000 {
			compatible = "google,zumapro-peric0-sysreg", "syscon";
			reg = <0x10820000 0x10000>;
		};

		/*
		 * Source: debug UART address, IRQ, FIFO size, and CMU_PERIC0
		 * clock path are from research/dumped.dts:15121-15136 and the
		 * downstream Zuma cmucal data.  The compatible and clock-name
		 * spelling use the upstream GS101 UART binding/driver.
		 */
		serial_0: serial@10870000 {
			compatible = "google,gs101-uart";
			reg = <0x10870000 0x100>;
			clocks = <&cmu_peric0 CLK_GOUT_PERIC0_USI0_UART_PCLK>,
				 <&cmu_peric0 CLK_GOUT_PERIC0_USI0_UART_IPCLK>;
			clock-names = "uart", "clk_uart_baud0";
			interrupts = <GIC_SPI 641 IRQ_TYPE_LEVEL_HIGH 0>;
			pinctrl-names = "default";
			pinctrl-0 = <&uart0_bus>;
			samsung,uart-fifosize = <256>;
			status = "okay";
		};

		/*
		 * The four camera buses.  USI2..USI5 in I2C mode carry,
		 * respectively, the ultrawide sensor and its EEPROM, the front
		 * sensor and its EEPROM, the auxiliary devices (camera PMIC,
		 * PP3200_CAM_BB buck-boost, flash LED driver), and the main
		 * sensor with its combined AF/OIS/EEPROM part.
		 *
		 * Source: research/dumped.dts hsi2c@10890000, hsi2c@108A0000,
		 * hsi2c@108B0000 and hsi2c@108C0000 for the addresses, IRQs,
		 * bus rates and USI mode offsets, and zumapro-pinctrl.dtsi for
		 * the pinmux.  The USI mode register offsets follow the same
		 * +0x4 stride as USI6's 0x1014.  Devices live in the board
		 * file.
		 *
		 * Each USI's serial-engine clock is pinned to the 200 MHz the
		 * vendor kernel asks for, off the PERIC0 IP feed.  Nothing
		 * else selects that mux, so without this each bus would
		 * inherit whatever the bootloader left -- possibly oscclk at
		 * 24.576 MHz -- and i2c-exynos5 derives its bus timing from
		 * that rate with no lower bound check.  The rate request stops
		 * at the mux, which carries CLK_SET_RATE_NO_REPARENT and does
		 * not propagate, so it cannot disturb the PERIC0 IP feed the
		 * debug UART shares.
		 */
		usi2: usi@108900c0 {
			compatible = "google,gs101-usi", "samsung,exynos850-usi";
			reg = <0x108900c0 0x20>;
			ranges;
			#address-cells = <1>;
			#size-cells = <1>;
			clocks = <&cmu_peric0 CLK_GOUT_PERIC0_USI2_USI_PCLK>,
				 <&cmu_peric0 CLK_DOUT_PERIC0_USI2_USI>;
			clock-names = "pclk", "ipclk";
			assigned-clocks = <&cmu_peric0 CLK_MOUT_PERIC0_USI2_USI_USER>,
					  <&cmu_peric0 CLK_DOUT_PERIC0_USI2_USI>;
			assigned-clock-parents = <&cmu_top CLK_DOUT_CMU_PERIC0_IP>;
			assigned-clock-rates = <0>, <200000000>;
			samsung,sysreg = <&sysreg_peric0 0x1004>;
			status = "disabled";

			hsi2c_2: i2c@10890000 {
				compatible = "google,gs101-hsi2c",
					     "samsung,exynosautov9-hsi2c";
				reg = <0x10890000 0xc0>;
				#address-cells = <1>;
				#size-cells = <0>;
				clocks = <&cmu_peric0 CLK_DOUT_PERIC0_USI2_USI>,
					 <&cmu_peric0 CLK_GOUT_PERIC0_USI2_USI_PCLK>;
				clock-names = "hsi2c", "hsi2c_pclk";
				interrupts = <GIC_SPI 643 IRQ_TYPE_LEVEL_HIGH 0>;
				pinctrl-names = "default";
				pinctrl-0 = <&hsi2c2_bus>;
				clock-frequency = <400000>;
				status = "disabled";
			};
		};

		usi3: usi@108a00c0 {
			compatible = "google,gs101-usi", "samsung,exynos850-usi";
			reg = <0x108a00c0 0x20>;
			ranges;
			#address-cells = <1>;
			#size-cells = <1>;
			clocks = <&cmu_peric0 CLK_GOUT_PERIC0_USI3_USI_PCLK>,
				 <&cmu_peric0 CLK_DOUT_PERIC0_USI3_USI>;
			clock-names = "pclk", "ipclk";
			assigned-clocks = <&cmu_peric0 CLK_MOUT_PERIC0_USI3_USI_USER>,
					  <&cmu_peric0 CLK_DOUT_PERIC0_USI3_USI>;
			assigned-clock-parents = <&cmu_top CLK_DOUT_CMU_PERIC0_IP>;
			assigned-clock-rates = <0>, <200000000>;
			samsung,sysreg = <&sysreg_peric0 0x1008>;
			status = "disabled";

			hsi2c_3: i2c@108a0000 {
				compatible = "google,gs101-hsi2c",
					     "samsung,exynosautov9-hsi2c";
				reg = <0x108a0000 0xc0>;
				#address-cells = <1>;
				#size-cells = <0>;
				clocks = <&cmu_peric0 CLK_DOUT_PERIC0_USI3_USI>,
					 <&cmu_peric0 CLK_GOUT_PERIC0_USI3_USI_PCLK>;
				clock-names = "hsi2c", "hsi2c_pclk";
				interrupts = <GIC_SPI 644 IRQ_TYPE_LEVEL_HIGH 0>;
				pinctrl-names = "default";
				pinctrl-0 = <&hsi2c3_bus>;
				clock-frequency = <400000>;
				status = "disabled";
			};
		};

		usi4: usi@108b00c0 {
			compatible = "google,gs101-usi", "samsung,exynos850-usi";
			reg = <0x108b00c0 0x20>;
			ranges;
			#address-cells = <1>;
			#size-cells = <1>;
			clocks = <&cmu_peric0 CLK_GOUT_PERIC0_USI4_USI_PCLK>,
				 <&cmu_peric0 CLK_DOUT_PERIC0_USI4_USI>;
			clock-names = "pclk", "ipclk";
			assigned-clocks = <&cmu_peric0 CLK_MOUT_PERIC0_USI4_USI_USER>,
					  <&cmu_peric0 CLK_DOUT_PERIC0_USI4_USI>;
			assigned-clock-parents = <&cmu_top CLK_DOUT_CMU_PERIC0_IP>;
			assigned-clock-rates = <0>, <200000000>;
			samsung,sysreg = <&sysreg_peric0 0x100c>;
			status = "disabled";

			hsi2c_4: i2c@108b0000 {
				compatible = "google,gs101-hsi2c",
					     "samsung,exynosautov9-hsi2c";
				reg = <0x108b0000 0xc0>;
				#address-cells = <1>;
				#size-cells = <0>;
				clocks = <&cmu_peric0 CLK_DOUT_PERIC0_USI4_USI>,
					 <&cmu_peric0 CLK_GOUT_PERIC0_USI4_USI_PCLK>;
				clock-names = "hsi2c", "hsi2c_pclk";
				interrupts = <GIC_SPI 645 IRQ_TYPE_LEVEL_HIGH 0>;
				pinctrl-names = "default";
				pinctrl-0 = <&hsi2c4_bus>;
				/* The rate the vendor kernel runs this bus at. */
				clock-frequency = <390000>;
				status = "disabled";
			};
		};

		usi5: usi@108c00c0 {
			compatible = "google,gs101-usi", "samsung,exynos850-usi";
			reg = <0x108c00c0 0x20>;
			ranges;
			#address-cells = <1>;
			#size-cells = <1>;
			clocks = <&cmu_peric0 CLK_GOUT_PERIC0_USI5_USI_PCLK>,
				 <&cmu_peric0 CLK_DOUT_PERIC0_USI5_USI>;
			clock-names = "pclk", "ipclk";
			assigned-clocks = <&cmu_peric0 CLK_MOUT_PERIC0_USI5_USI_USER>,
					  <&cmu_peric0 CLK_DOUT_PERIC0_USI5_USI>;
			assigned-clock-parents = <&cmu_top CLK_DOUT_CMU_PERIC0_IP>;
			assigned-clock-rates = <0>, <200000000>;
			samsung,sysreg = <&sysreg_peric0 0x1010>;
			status = "disabled";

			hsi2c_5: i2c@108c0000 {
				compatible = "google,gs101-hsi2c",
					     "samsung,exynosautov9-hsi2c";
				reg = <0x108c0000 0xc0>;
				#address-cells = <1>;
				#size-cells = <0>;
				clocks = <&cmu_peric0 CLK_DOUT_PERIC0_USI5_USI>,
					 <&cmu_peric0 CLK_GOUT_PERIC0_USI5_USI_PCLK>;
				clock-names = "hsi2c", "hsi2c_pclk";
				interrupts = <GIC_SPI 646 IRQ_TYPE_LEVEL_HIGH 0>;
				pinctrl-names = "default";
				pinctrl-0 = <&hsi2c5_bus>;
				clock-frequency = <400000>;
				status = "disabled";
			};
		};

		/*
		 * Source: downstream hsi2c_6 and USI6 pinmux data are from
		 * zumapro-usi.dtsi and zumapro-pinctrl.dtsi.  Only the bare
		 * controller is enabled for now; consumers stay out until the
		 * bus is validated on hardware.
		 */
		usi6: usi@108d00c0 {
			compatible = "google,gs101-usi", "samsung,exynos850-usi";
			reg = <0x108d00c0 0x20>;
			ranges;
			#address-cells = <1>;
			#size-cells = <1>;
			clocks = <&cmu_peric0 CLK_GOUT_PERIC0_USI6_USI_PCLK>,
				 <&cmu_peric0 CLK_DOUT_PERIC0_USI6_USI>;
			clock-names = "pclk", "ipclk";
			samsung,sysreg = <&sysreg_peric0 0x1014>;
			status = "disabled";

			hsi2c_6: i2c@108d0000 {
				compatible = "google,gs101-hsi2c",
					     "samsung,exynosautov9-hsi2c";
				reg = <0x108d0000 0xc0>;
				#address-cells = <1>;
				#size-cells = <0>;
				clocks = <&cmu_peric0 CLK_DOUT_PERIC0_USI6_USI>,
					 <&cmu_peric0 CLK_GOUT_PERIC0_USI6_USI_PCLK>;
				clock-names = "hsi2c", "hsi2c_pclk";
				interrupts = <GIC_SPI 647 IRQ_TYPE_LEVEL_HIGH 0>;
				pinctrl-names = "default";
				pinctrl-0 = <&hsi2c6_bus>;
				status = "disabled";
			};
		};

		/*
		 * Source: downstream CMU_PERIC1 block base/size is from
		 * cmucal-sfr.c.  The sysreg range, USI10 address, IRQ,
		 * mode offset, pinmux, and EEPROM child are from
		 * research/dumped.dts and downstream zumapro-usi.dtsi.
		 */
		cmu_peric1: clock-controller@10c00000 {
			compatible = "google,zumapro-cmu-peric1";
			reg = <0x10c00000 0x10000>;
			#clock-cells = <1>;
			clocks = <&ext_24_5m>,
				 <&cmu_top CLK_DOUT_CMU_PERIC1_NOC>,
				 <&cmu_top CLK_DOUT_CMU_PERIC1_IP>;
			clock-names = "oscclk", "bus", "ip";
			samsung,sysreg = <&sysreg_peric1>;
		};

		sysreg_peric1: syscon@10c20000 {
			compatible = "google,zumapro-peric1-sysreg", "syscon";
			reg = <0x10c20000 0x10000>;
		};

		/*
		 * BLK_ALIVE APM sysreg.  Hosts the APM USI SW_CONF (protocol
		 * select) registers; APM_USI1 SW_CONF is at offset 0x4.  Base and
		 * offset are from research/dumped.dts:5787 (syscon@154204E0) and
		 * the downstream serial@155D0000 samsung,usi-offset = <0x4>.
		 */
		sysreg_apm: syscon@154204e0 {
			compatible = "google,zumapro-apm-sysreg", "syscon";
			reg = <0x154204e0 0x1000>;
		};

		/*
		 * BLK_ALIVE APM_USI1 in UART mode = "uart18" (ttySAC18), the
		 * Bluetooth HCI transport for the BCM4383 combo chip.  UART base,
		 * IRQ (GIC_SPI 71) and the USI SW_CONF offset are from
		 * research/dumped.dts serial@155D0000; the gpa3 4-wire pinmux is
		 * uart18_bus.  Unlike the peric USI nodes the bootloader does not
		 * pre-select UART mode on this always-on block, so the USI wrapper
		 * sets samsung,mode = <USI_MODE_UART>.  Reg split (serial 0xc0,
		 * USI at +0xc0) follows the exynosautov920 USI-UART pattern so the
		 * two windows do not overlap.
		 */
		usi_apm_uart: usi@155d00c0 {
			compatible = "google,gs101-usi", "samsung,exynos850-usi";
			reg = <0x155d00c0 0x20>;
			ranges;
			#address-cells = <1>;
			#size-cells = <1>;
			clocks = <&apm_usi1_uart_clk>, <&apm_usi1_uart_clk>;
			clock-names = "pclk", "ipclk";
			samsung,sysreg = <&sysreg_apm 0x4>;
			samsung,mode = <USI_MODE_UART>;
			status = "disabled";

			serial_18: serial@155d0000 {
				compatible = "google,gs101-uart";
				reg = <0x155d0000 0xc0>;
				clocks = <&apm_usi1_uart_clk>,
					 <&apm_usi1_uart_clk>;
				clock-names = "uart", "clk_uart_baud0";
				interrupts = <GIC_SPI 71 IRQ_TYPE_LEVEL_HIGH 0>;
				pinctrl-names = "default";
				pinctrl-0 = <&uart18_bus>;
				samsung,uart-fifosize = <256>;
				status = "disabled";
			};
		};

		/*
		 * USI9 in I2C mode.  The bus carries the eUSB2 repeater at
		 * 0x3e, which is what converts the eUSB2 PHY's 1.0 V
		 * signalling to the 3.3 V D+/D- on the USB connector; on tegu
		 * it also carries NFC at 0x08 and the haptics codec at 0x43.
		 * The USI SW_CONF selector for USI9 is at sysreg_peric1 +
		 * 0x1004, one word below USI10's, as on gs101.
		 *
		 * clock-frequency is 400 kHz for bring-up; the vendor kernel
		 * runs this bus at 950 kHz, which every device on it tolerates
		 * but none requires.
		 */
		usi9: usi@10c900c0 {
			compatible = "google,gs101-usi", "samsung,exynos850-usi";
			reg = <0x10c900c0 0x20>;
			ranges;
			#address-cells = <1>;
			#size-cells = <1>;
			clocks = <&cmu_peric1 CLK_GOUT_PERIC1_USI9_USI_PCLK>,
				 <&cmu_peric1 CLK_DOUT_PERIC1_USI9_USI>;
			clock-names = "pclk", "ipclk";
			samsung,sysreg = <&sysreg_peric1 0x1004>;
			status = "disabled";

			hsi2c_9: i2c@10c90000 {
				compatible = "google,gs101-hsi2c",
					     "samsung,exynosautov9-hsi2c";
				reg = <0x10c90000 0xc0>;
				#address-cells = <1>;
				#size-cells = <0>;
				clocks = <&cmu_peric1 CLK_DOUT_PERIC1_USI9_USI>,
					 <&cmu_peric1 CLK_GOUT_PERIC1_USI9_USI_PCLK>;
				clock-names = "hsi2c", "hsi2c_pclk";
				interrupts = <GIC_SPI 657 IRQ_TYPE_LEVEL_HIGH 0>;
				clock-frequency = <400000>;
				pinctrl-names = "default";
				pinctrl-0 = <&hsi2c9_bus>;
				status = "disabled";
			};
		};

		usi10: usi@10ca00c0 {
			compatible = "google,gs101-usi", "samsung,exynos850-usi";
			reg = <0x10ca00c0 0x20>;
			ranges;
			#address-cells = <1>;
			#size-cells = <1>;
			clocks = <&cmu_peric1 CLK_GOUT_PERIC1_USI10_USI_PCLK>,
				 <&cmu_peric1 CLK_DOUT_PERIC1_USI10_USI>;
			clock-names = "pclk", "ipclk";
			samsung,sysreg = <&sysreg_peric1 0x1008>;
			status = "disabled";

			hsi2c_10: i2c@10ca0000 {
				compatible = "google,gs101-hsi2c",
					     "samsung,exynosautov9-hsi2c";
				reg = <0x10ca0000 0xc0>;
				#address-cells = <1>;
				#size-cells = <0>;
				clocks = <&cmu_peric1 CLK_DOUT_PERIC1_USI10_USI>,
					 <&cmu_peric1 CLK_GOUT_PERIC1_USI10_USI_PCLK>;
				clock-names = "hsi2c", "hsi2c_pclk";
				interrupts = <GIC_SPI 658 IRQ_TYPE_LEVEL_HIGH 0>;
				clock-frequency = <400000>;
				pinctrl-names = "default";
				pinctrl-0 = <&hsi2c10_bus>;
				status = "disabled";
			};
		};

		/*
		 * CMU_HSI1 clocks the modem's PCIe CH0 root complex (Gen3 x2,
		 * pcie@12100000).  Base and feeds are from the downstream Zuma
		 * cmucal-sfr.c/cmucal-node.c tables like CMU_HSI2 below; the
		 * block sits in pd-hsi1.
		 */
		cmu_hsi1: clock-controller@12000000 {
			compatible = "google,zumapro-cmu-hsi1";
			reg = <0x12000000 0x10000>;
			#clock-cells = <1>;
			clocks = <&ext_24_5m>,
				 <&cmu_top CLK_DOUT_CMU_HSI1_NOC>,
				 <&cmu_top CLK_DOUT_CMU_HSI1_PCIE>;
			clock-names = "oscclk", "bus", "pcie";
			samsung,sysreg = <&sysreg_hsi1>;
			power-domains = <&pd_hsi1>;
		};

		/*
		 * SYSREG_HSI1: reg base/size from research/dumped.dts:8172
		 * (the pcie@12100000 "sysreg" region).  Also the home of the
		 * HSI1 shareability control (offset 0x704) the modem's
		 * cache-coherent DMA setup will need later.
		 */
		sysreg_hsi1: syscon@12020000 {
			compatible = "google,zumapro-hsi1-sysreg", "syscon";
			reg = <0x12020000 0x2000>;
			clocks = <&cmu_hsi1 CLK_GOUT_HSI1_SYSREG_HSI1_PCLK>;
		};

		/*
		 * Source: CMU_HSI2 UFS-related registers are from downstream
		 * Zuma cmucal-sfr.c/cmucal-node.c.  The node shape follows
		 * upstream GS101, with the Zumapro base address from
		 * research/dumped.dts:4753 and downstream zuma-ufs.dtsi.
		 */
		cmu_hsi2: clock-controller@13000000 {
			compatible = "google,zumapro-cmu-hsi2";
			reg = <0x13000000 0x10000>;
			#clock-cells = <1>;
			clocks = <&ext_24_5m>,
				 <&cmu_top CLK_DOUT_CMU_HSI2_NOC>,
				 <&cmu_top CLK_DOUT_CMU_HSI2_PCIE>,
				 <&cmu_top CLK_DOUT_CMU_HSI2_UFS_EMBD>,
				 <&cmu_top CLK_DOUT_CMU_HSI2_MMC_CARD>;
			clock-names = "oscclk", "bus", "pcie", "ufs", "mmc";
			samsung,sysreg = <&sysreg_hsi2>;
		};

		sysreg_hsi2: syscon@13020000 {
			compatible = "google,zumapro-hsi2-sysreg", "syscon";
			reg = <0x13020000 0x1000>;
			clocks = <&cmu_hsi2 CLK_GOUT_HSI2_SYSREG_HSI2_PCLK>;
		};

		ufs_0: ufs@13200000 {
			compatible = "google,zumapro-ufs";
			reg = <0x13200000 0x200>,
			      <0x13201100 0x200>,
			      <0x13280000 0xa000>,
			      <0x132a0000 0x100>;
			reg-names = "hci", "vs_hci", "unipro", "ufsp";
			interrupts = <GIC_SPI 466 IRQ_TYPE_LEVEL_HIGH 0>;
			clocks = <&cmu_hsi2 CLK_GOUT_HSI2_UFS_EMBD_I_ACLK>,
				 <&cmu_hsi2 CLK_GOUT_HSI2_UFS_EMBD_I_CLK_UNIPRO>,
				 <&cmu_hsi2 CLK_GOUT_HSI2_UFS_EMBD_I_FMP_CLK>,
				 <&cmu_hsi2 CLK_GOUT_HSI2_QE_UFS_EMBD_HSI2_ACLK>,
				 <&cmu_hsi2 CLK_GOUT_HSI2_QE_UFS_EMBD_HSI2_PCLK>,
				 <&cmu_hsi2 CLK_GOUT_HSI2_SYSREG_HSI2_PCLK>;
			clock-names = "core_clk", "sclk_unipro_main", "fmp",
				      "aclk", "pclk", "sysreg";
			dma-coherent;
			freq-table-hz = <0 0>, <0 0>, <0 0>,
					<0 0>, <0 0>, <0 0>;
			pinctrl-names = "default";
			pinctrl-0 = <&ufs_rst_n &ufs_refclk_out>;
			phys = <&ufs_0_phy>;
			phy-names = "ufs-phy";
			samsung,sysreg = <&sysreg_hsi2 0x710>;
			vcc-supply = <&ufs_0_fixed_vcc_reg>;
			status = "okay";
		};

		ufs_0_phy: phy@13204000 {
			compatible = "google,zumapro-ufs-phy";
			reg = <0x13204000 0x4000>;
			reg-names = "phy-pma";
			#phy-cells = <0>;
			clocks = <&ext_24_5m>;
			clock-names = "ref_clk";
			samsung,pmu-syscon = <&pmu_system_controller 0x3ec0>;
			status = "okay";
		};

		/*
		 * PCIe GEN3_0 (CH0/HSI1) root complex and PHY for the Exynos
		 * Modem 5300 (Gen3 x2).  Addresses, interrupts and ranges are
		 * from research/dumped.dts:8161-8198 (pcie@12100000); the PHY
		 * regions are the controller's "phy"/"pcs"/"udbg"/"soc"
		 * windows.  The outbound window is non-identity: PCI
		 * 0x14e00000 maps to CPU 0x40000000 (the modem doorbell BAR
		 * lives at PCI 0x14e60000).  Both nodes stay disabled here
		 * and are enabled by the board once the endpoint's power-on
		 * sequencing is in place.
		 */
		pcie0_phy: pcie-phy@12140000 {
			compatible = "google,zumapro-pcie-x2-phy";
			reg = <0x12140000 0x3000>,
			      <0x12120000 0x5000>,
			      <0x12130000 0xd000>,
			      <0x12110000 0x5000>;
			reg-names = "pma", "pcs", "pll", "soc";
			clocks = <&cmu_hsi1 CLK_GOUT_HSI1_PCIE_GEN3_0_PHY_REFCLK_IN>,
				 <&cmu_hsi1 CLK_GOUT_HSI1_PCIE_GEN3_0_PIPE_PAL_APB_PCLK>,
				 <&cmu_hsi1 CLK_GOUT_HSI1_PCIE_GEN3_0_UDBG_APB_PCLK>;
			clock-names = "ref", "apb", "udbg";
			samsung,pmu-syscon = <&pmu_system_controller 0x3ec4>;
			power-domains = <&pd_hsi1>;
			#phy-cells = <0>;
			status = "disabled";
		};

		pcie0: pcie@12100000 {
			compatible = "google,zumapro-pcie";
			reg = <0x12100000 0x2000>,
			      <0x12400000 0x381000>,
			      <0x40ffe000 0x2000>;
			reg-names = "elbi", "dbi", "config";
			#address-cells = <3>;
			#size-cells = <2>;
			#interrupt-cells = <1>;
			device_type = "pci";
			/*
			 * "msi1".."msi4" are the DWC iMSI-RX "separated MSI"
			 * group 1-4 outputs (MSI data 32/64/96/128): the Exynos
			 * modem fires one per PKTPROC DL queue in exclusive
			 * irq_mode, each on its own GIC line so a DL reply is
			 * delivered without waiting on the shared "msi" (group 0).
			 */
			interrupts = <GIC_SPI 414 IRQ_TYPE_LEVEL_HIGH 0>,
				     <GIC_SPI 416 IRQ_TYPE_LEVEL_HIGH 0>,
				     <GIC_SPI 417 IRQ_TYPE_LEVEL_HIGH 0>,
				     <GIC_SPI 418 IRQ_TYPE_LEVEL_HIGH 0>,
				     <GIC_SPI 419 IRQ_TYPE_LEVEL_HIGH 0>,
				     <GIC_SPI 420 IRQ_TYPE_LEVEL_HIGH 0>;
			interrupt-names = "intr", "msi", "msi1", "msi2", "msi3", "msi4";
			interrupt-map-mask = <0 0 0 0>;
			interrupt-map = <0 0 0 0 &gic GIC_SPI 414 IRQ_TYPE_LEVEL_HIGH 0>;
			clocks = <&cmu_hsi1 CLK_GOUT_HSI1_PCIE_GEN3_0_DBI_ACLK>,
				 <&cmu_hsi1 CLK_GOUT_HSI1_PCIE_GEN3_0_MSTR_ACLK>,
				 <&cmu_hsi1 CLK_GOUT_HSI1_PCIE_GEN3_0_SLV_ACLK>,
				 <&cmu_hsi1 CLK_GOUT_HSI1_PCIE_GEN3_0_DRIVER_APB_CLK>;
			clock-names = "dbi", "mstr", "slv", "apb";
			phys = <&pcie0_phy>;
			phy-names = "pcie";
			samsung,pmu-syscon = <&pmu_system_controller 0x3ec4>;
			num-lanes = <2>;
			max-link-speed = <3>;
			bus-range = <0x00 0xff>;
			ranges = <0x82000000 0 0x14e00000 0x40000000 0 0xff0000>;
			power-domains = <&pd_hsi1>;
			status = "disabled";
		};

		/*
		 * PCIe GEN3A_1 root complex and PHY for the on-board WiFi
		 * (Broadcom BCM4383).  Addresses, interrupts and ranges are from
		 * research/dumped.dts:8217-8265 (pcie@13120000); the PHY register
		 * regions are the controller's "phy"/"pcs"/"udbg"/"soc" windows.
		 * Both nodes stay disabled here and are enabled by the board.
		 */
		pcie_phy: pcie-phy@13160000 {
			compatible = "google,zumapro-pcie-phy";
			reg = <0x13160000 0x3000>,
			      <0x13140000 0x5000>,
			      <0x13150000 0xd000>,
			      <0x13130000 0x5000>;
			reg-names = "pma", "pcs", "pll", "soc";
			clocks = <&cmu_hsi2 CLK_GOUT_HSI2_PCIE_GEN3A_1_PHY_REFCLK_IN>,
				 <&cmu_hsi2 CLK_GOUT_HSI2_PCIE_GEN3A_1_PIPE_PAL_APB_PCLK>,
				 <&cmu_hsi2 CLK_GOUT_HSI2_PCIE_GEN3A_1_UDBG_APB_PCLK>;
			clock-names = "ref", "apb", "udbg";
			samsung,pmu-syscon = <&pmu_system_controller 0x3ec8>;
			#phy-cells = <0>;
			status = "disabled";
		};

		pcie: pcie@13120000 {
			compatible = "google,zumapro-pcie";
			reg = <0x13120000 0x2000>,
			      <0x13400000 0x381000>,
			      <0x60ffe000 0x2000>;
			reg-names = "elbi", "dbi", "config";
			#address-cells = <3>;
			#size-cells = <2>;
			#interrupt-cells = <1>;
			device_type = "pci";
			interrupts = <GIC_SPI 439 IRQ_TYPE_LEVEL_HIGH 0>,
				     <GIC_SPI 441 IRQ_TYPE_LEVEL_HIGH 0>;
			interrupt-names = "intr", "msi";
			interrupt-map-mask = <0 0 0 0>;
			interrupt-map = <0 0 0 0 &gic GIC_SPI 439 IRQ_TYPE_LEVEL_HIGH 0>;
			clocks = <&cmu_hsi2 CLK_GOUT_HSI2_PCIE_GEN3A_1_DBI_ACLK>,
				 <&cmu_hsi2 CLK_GOUT_HSI2_PCIE_GEN3A_1_MSTR_ACLK>,
				 <&cmu_hsi2 CLK_GOUT_HSI2_PCIE_GEN3A_1_SLV_ACLK>,
				 <&cmu_hsi2 CLK_GOUT_HSI2_PCIE_GEN3A_1_DRIVER_APB_CLK>;
			clock-names = "dbi", "mstr", "slv", "apb";
			phys = <&pcie_phy>;
			phy-names = "pcie";
			samsung,pmu-syscon = <&pmu_system_controller 0x3ec8>;
			num-lanes = <1>;
			max-link-speed = <2>;
			bus-range = <0x00 0xff>;
			ranges = <0x82000000 0 0x60000000 0x60000000 0 0xff0000>;
			status = "disabled";
		};

		/*
		 * USB2 high-speed peripheral path (Pixel 9a boots over fastboot, so
		 * USB is live at handoff).  Structural template: the in-tree
		 * exynos2200.dtsi USB block; all addresses/clocks/IRQs are zumapro's
		 * own, from research/dumped.dts and the hardware MMIO trace
		 * (docs/archive/usb/needs-hardware-2026-05.md H1/H2/H3, docs/decisions/0002).
		 *
		 * The combo USB32DRD PHY's "phy" reg (0x11100000) holds the DRD
		 * link-control registers the driver writes (LINKCTRL 0x04, CLKRST
		 * 0x0c, UTMI 0x10, HSP_MISC 0x114 — trace-confirmed).  Only this
		 * single region is mapped: the SuperSpeed combo PCS (0x11130000) /
		 * PMA (0x11140000) are intentionally left out for first high-speed
		 * bring-up so the heavily-accessed SuperSpeed path is not touched.
		 * The HS init is delegated to the Synopsys eUSB2 "hs" phy below.
		 *
		 * The combo PHY itself takes no regulator supply (its driver data has
		 * none); the eUSB2 PHY and the DWC3 wrapper draw vdd/vdda12 and
		 * vdd33/vdd10 from the fixed reg_placeholder, since the real rails are
		 * PMIC-managed and left on by the bootloader.  The reused exynos2200
		 * PHY ops do drive the PMU USB2.0 isolation bit (offset 0x3eb0) via the
		 * pmu-syscon regmap on init/exit; on this live-at-handoff path the init
		 * de-isolation is effectively a no-op because it is already enabled.
		 */
		usb32drd: phy@11100000 {
			compatible = "google,zumapro-usb32drd-phy";
			reg = <0x11100000 0x200>;

			clocks = <&cmu_hsi0 CLK_MOUT_HSI0_NOC_USER>;
			clock-names = "phy";

			#phy-cells = <1>;
			phys = <&usb_hsphy>;
			phy-names = "hs";

			samsung,pmu-syscon = <&pmu_system_controller>;

			status = "okay";
		};

		/*
		 * Synopsys eUSB2 HS PHY.  The EUSBCON control block is a separate
		 * MMIO resource at 0x11110000 (downstream reg index 1); its register
		 * offsets (RST 0x0, COMMON 0x4, PLLCFG0 0x8, PLLCFG1 0xc, TX 0x14,
		 * TESTSE 0x20) match the mainline phy-snps-eusb2 Exynos variant and
		 * the downstream eusb-con-reg.h exactly (docs/decisions/0002).  "ref" is
		 * the 19.2 MHz USB reference (PLL_USB/32, trace-confirmed), which
		 * selects the eUSB2 PLL config (fb_div 0x170, ref_div 0 — matches
		 * downstream).
		 */
		usb_hsphy: phy@11110000 {
			compatible = "google,zumapro-eusb2-phy";
			reg = <0x11110000 0x200>;

			clocks = <&cmu_hsi0 CLK_DOUT_HSI0_USB>,
				 <&cmu_hsi0 CLK_MOUT_HSI0_NOC_USER>,
				 <&cmu_hsi0 CLK_DOUT_HSI0_EUSB>;
			clock-names = "ref", "bus", "ctrl";

			/* Placeholder rails until s2mpg14/15 PMIC support lands. */
			vdd-supply = <&reg_placeholder>;
			vdda12-supply = <&reg_placeholder>;

			#phy-cells = <0>;

			status = "okay";
		};

		/*
		 * DWC3 wrapper + core.  Wrapper IRQ 402 (0x192) and the snps quirks
		 * are from research/dumped.dts.  dr_mode = peripheral and
		 * maximum-speed = high-speed for first bring-up: the live DT requests
		 * super-speed with force_gen1, but mainline's exynos2200-style combo
		 * PHY ops drive only the HS (UTMI/eUSB2) path, so SuperSpeed is
		 * deferred until the combo PCS/PMA path is brought up and validated.
		 */
		usb: usb@11210000 {
			compatible = "google,zumapro-dwusb3";
			ranges = <0x0 0x11210000 0x10000>;

			clocks = <&cmu_hsi0 CLK_GOUT_HSI0_USB32DRD_LINK>,
				 <&cmu_hsi0 CLK_DOUT_HSI0_USB>,
				 <&cmu_top CLK_DOUT_CMU_HSI0_NOC>;
			clock-names = "aclk", "sclk", "bus";

			/* Placeholder rails until s2mpg14/15 PMIC support lands. */
			vdd33-supply = <&reg_placeholder>;
			vdd10-supply = <&reg_placeholder>;

			/*
			 * The USB32DRD PHY/link gates access to the child DWC3
			 * core's global registers: suspend's phy_exit() isolates
			 * the link, so the resume path must re-init the PHY before
			 * reading GUSB* registers. Needed because an aborted
			 * suspend can resume DWC3 without resuming the PHY provider.
			 */
			samsung,phy-init-before-setup;

			#address-cells = <1>;
			#size-cells = <1>;

			status = "okay";

			usb_dwc3: usb@0 {
				compatible = "snps,dwc3";
				reg = <0x0 0x10000>;

				clocks = <&cmu_hsi0 CLK_DOUT_HSI0_USB>;
				clock-names = "ref";

				interrupts = <GIC_SPI 402 IRQ_TYPE_LEVEL_HIGH 0>;

				phys = <&usb32drd 0>;
				phy-names = "usb2-phy";

				dr_mode = "peripheral";
				maximum-speed = "high-speed";

				snps,quirk-frame-length-adjustment = <0x20>;
				snps,has-lpm-erratum;
				snps,lpm-nyet-threshold = /bits/ 8 <0>;
				snps,usb2-gadget-lpm-disable;
				snps,dis-u2-freeclk-exists-quirk;
				snps,dis-u1-entry-quirk;
				snps,dis-u2-entry-quirk;
			};
		};

		/*
		 * Source: the BLK_HSI0 sysreg base/size and the USI2 SW_CONF
		 * offset (0x101c) are from research/dumped.dts spi@111D0000
		 * (samsung,usi-phandle/samsung,usi-offset) and the downstream
		 * zumapro-usi.dtsi ("BLK_HSI0 USI2_HSI0").
		 */
		sysreg_hsi0: syscon@11020000 {
			compatible = "google,zumapro-hsi0-sysreg", "syscon";
			reg = <0x11020000 0x10000>;
		};

		/*
		 * BLK_HSI0 USI2 in SPI mode: the touchscreen bus on tegu.
		 * Address/IRQ are from research/dumped.dts spi@111D0000;
		 * the node layout mirrors the in-tree gs101 USI/SPI nodes.
		 *
		 * Deliberately no "dmas": spi-s3c64xx then uses its polling
		 * fallback, so the downstream pdma1 (PL330) does not need to
		 * be brought up for first touch bring-up.
		 *
		 * No power-domains: BLK_HSI0 is kept on by the bootloader for
		 * the (always-live) USB block, like the other HSI0 nodes.
		 */
		usi2_hsi0: usi@111d00c0 {
			compatible = "google,gs101-usi", "samsung,exynos850-usi";
			reg = <0x111d00c0 0x20>;
			ranges;
			#address-cells = <1>;
			#size-cells = <1>;
			clocks = <&cmu_hsi0 CLK_GOUT_HSI0_USI2_USI_PCLK>,
				 <&cmu_hsi0 CLK_GOUT_HSI0_USI2_USI_CLK>;
			clock-names = "pclk", "ipclk";
			samsung,sysreg = <&sysreg_hsi0 0x101c>;
			status = "disabled";

			spi_20: spi@111d0000 {
				compatible = "google,gs101-spi";
				reg = <0x111d0000 0x30>;
				#address-cells = <1>;
				#size-cells = <0>;
				clocks = <&cmu_hsi0 CLK_GOUT_HSI0_USI2_USI_PCLK>,
					 <&cmu_hsi0 CLK_GOUT_HSI0_USI2_USI_CLK>;
				clock-names = "spi", "spi_busclk0";
				interrupts = <GIC_SPI 408 IRQ_TYPE_LEVEL_HIGH 0>;
				status = "disabled";
			};
		};

		/*
		 * USI3_HSI0 in SPI mode: the KEPLER GNSS receiver (spi_21 on
		 * Tegu).  Address, IRQ and sysreg offset from downstream
		 * research/dumped.dts (spi@111E0000, GIC SPI 0x199,
		 * samsung,usi-offset 0x1020); the CMU offsets behind the clock
		 * IDs come from the vendor cal-if cmucal-sfr.c.  Like spi_20
		 * and hsi2c_19, no bus pinctrl: the dumped node carries none.
		 */
		usi3_hsi0: usi@111e00c0 {
			compatible = "google,gs101-usi", "samsung,exynos850-usi";
			reg = <0x111e00c0 0x20>;
			ranges;
			#address-cells = <1>;
			#size-cells = <1>;
			clocks = <&cmu_hsi0 CLK_GOUT_HSI0_USI3_USI_PCLK>,
				 <&cmu_hsi0 CLK_GOUT_HSI0_USI3_USI_CLK>;
			clock-names = "pclk", "ipclk";
			samsung,sysreg = <&sysreg_hsi0 0x1020>;
			status = "disabled";

			spi_21: spi@111e0000 {
				compatible = "google,gs101-spi";
				reg = <0x111e0000 0x30>;
				#address-cells = <1>;
				#size-cells = <0>;
				clocks = <&cmu_hsi0 CLK_GOUT_HSI0_USI3_USI_PCLK>,
					 <&cmu_hsi0 CLK_GOUT_HSI0_USI3_USI_CLK>;
				clock-names = "spi", "spi_busclk0";
				interrupts = <GIC_SPI 409 IRQ_TYPE_LEVEL_HIGH 0>;
				status = "disabled";
			};
		};

		/*
		 * USI4_HSI0 in I2C mode: the speaker amplifiers (hsi2c_19 on
		 * Tegu).  Address/IRQ/sysreg offset from downstream
		 * zumapro-usi.dtsi and research/dumped.dts (hsi2c@111F0000,
		 * GIC SPI 0x19a, usi-offset 0x1024).  Like the working spi_20
		 * (USI2_HSI0), no bus pinctrl: the dumped node carries none and
		 * the bootloader leaves the pins muxed.
		 */
		usi4_hsi0: usi@111f00c0 {
			compatible = "google,gs101-usi", "samsung,exynos850-usi";
			reg = <0x111f00c0 0x20>;
			ranges;
			#address-cells = <1>;
			#size-cells = <1>;
			clocks = <&cmu_hsi0 CLK_GOUT_HSI0_USI4_USI_PCLK>,
				 <&cmu_hsi0 CLK_GOUT_HSI0_USI4_USI_CLK>;
			clock-names = "pclk", "ipclk";
			samsung,sysreg = <&sysreg_hsi0 0x1024>;
			status = "disabled";

			hsi2c_19: i2c@111f0000 {
				compatible = "google,gs101-hsi2c",
					     "samsung,exynosautov9-hsi2c";
				reg = <0x111f0000 0xc0>;
				#address-cells = <1>;
				#size-cells = <0>;
				clocks = <&cmu_hsi0 CLK_GOUT_HSI0_USI4_USI_CLK>,
					 <&cmu_hsi0 CLK_GOUT_HSI0_USI4_USI_PCLK>;
				clock-names = "hsi2c", "hsi2c_pclk";
				interrupts = <GIC_SPI 410 IRQ_TYPE_LEVEL_HIGH 0>;
				status = "disabled";
			};
		};

		/*
		 * Source: pinctrl controller addresses/IRQs are from:
		 *  - peric0: research/dumped.dts:3393-3397
		 *  - peric1: research/dumped.dts:4139-4143
		 *  - hsi0:   research/dumped.dts:4519-4523
		 *  - hsi1:   research/dumped.dts:4628-4632
		 *  - hsi2:   research/dumped.dts:4753-4757
		 *  - eint:   research/dumped.dts:4787-4791
		 *  - alive:  research/dumped.dts:4932-4936
		 *  - far:    research/dumped.dts:5182-5186
		 *  - gsacore blocks: research/dumped.dts:5257-5316
		 *
		 * Enable only the non-GSA pinctrl banks needed for current bring-up.
		 * HSI0/HSI1 stay disabled until their PCIe-side consumers are added.
		 * The GSA-owned banks below stay disabled because they belong to the
		 * secure GSA domain.
		 */
		pinctrl_peric0: pinctrl@10840000 {
			compatible = "google,zumapro-pinctrl";
			reg = <0x10840000 0x1000>;
			interrupts = <GIC_SPI 634 IRQ_TYPE_LEVEL_HIGH 0>;
			status = "okay";

			gpp0: gpp0-gpio-bank {
				gpio-controller;
				#gpio-cells = <2>;
				interrupt-controller;
				#interrupt-cells = <2>;
			};

			gpp1: gpp1-gpio-bank {
				gpio-controller;
				#gpio-cells = <2>;
				interrupt-controller;
				#interrupt-cells = <2>;
			};

			gpp2: gpp2-gpio-bank {
				gpio-controller;
				#gpio-cells = <2>;
				interrupt-controller;
				#interrupt-cells = <2>;
			};

			gpp3: gpp3-gpio-bank {
				gpio-controller;
				#gpio-cells = <2>;
				interrupt-controller;
				#interrupt-cells = <2>;
			};

			gpp4: gpp4-gpio-bank {
				gpio-controller;
				#gpio-cells = <2>;
				interrupt-controller;
				#interrupt-cells = <2>;
			};

			gpp5: gpp5-gpio-bank {
				gpio-controller;
				#gpio-cells = <2>;
				interrupt-controller;
				#interrupt-cells = <2>;
			};

			gpp6: gpp6-gpio-bank {
				gpio-controller;
				#gpio-cells = <2>;
				interrupt-controller;
				#interrupt-cells = <2>;
			};

			gpp7: gpp7-gpio-bank {
				gpio-controller;
				#gpio-cells = <2>;
				interrupt-controller;
				#interrupt-cells = <2>;
			};

			gpp8: gpp8-gpio-bank {
				gpio-controller;
				#gpio-cells = <2>;
				interrupt-controller;
				#interrupt-cells = <2>;
			};

			gpp9: gpp9-gpio-bank {
				gpio-controller;
				#gpio-cells = <2>;
				interrupt-controller;
				#interrupt-cells = <2>;
			};

			gpp10: gpp10-gpio-bank {
				gpio-controller;
				#gpio-cells = <2>;
				interrupt-controller;
				#interrupt-cells = <2>;
			};

			gpp11: gpp11-gpio-bank {
				gpio-controller;
				#gpio-cells = <2>;
				interrupt-controller;
				#interrupt-cells = <2>;
			};

			gpp12: gpp12-gpio-bank {
				gpio-controller;
				#gpio-cells = <2>;
				interrupt-controller;
				#interrupt-cells = <2>;
			};

			gpp13: gpp13-gpio-bank {
				gpio-controller;
				#gpio-cells = <2>;
				interrupt-controller;
				#interrupt-cells = <2>;
			};

			gpp14: gpp14-gpio-bank {
				gpio-controller;
				#gpio-cells = <2>;
				interrupt-controller;
				#interrupt-cells = <2>;
			};

			gpp15: gpp15-gpio-bank {
				gpio-controller;
				#gpio-cells = <2>;
				interrupt-controller;
				#interrupt-cells = <2>;
			};

			gpp17: gpp17-gpio-bank {
				gpio-controller;
				#gpio-cells = <2>;
				interrupt-controller;
				#interrupt-cells = <2>;
			};

			gpp16: gpp16-gpio-bank {
				gpio-controller;
				#gpio-cells = <2>;
				interrupt-controller;
				#interrupt-cells = <2>;
			};

			/* USI_PERIC0_UART_DBG */
			uart0_bus: uart0-bus-pins {
				samsung,pins = "gpp1-2", "gpp1-3";
				samsung,pin-function = <ZUMAPRO_PIN_FUNC_2>;
				samsung,pin-pud = <ZUMAPRO_PIN_PULL_NONE>;
			};

			hsi2c6_bus: hsi2c6-bus-pins {
				samsung,pins = "gpp12-0", "gpp12-1";
				samsung,pin-function = <ZUMAPRO_PIN_FUNC_3>;
				samsung,pin-pud = <ZUMAPRO_PIN_PULL_UP>;
				samsung,pin-drv = <ZUMAPRO_PIN_DRV_X1>;
			};

			/*
			 * The four camera buses.  Source:
			 * research/dumped.dts hsi2c2-bus, hsi2c3-bus,
			 * hsi2c4-bus and hsi2c5-bus.  The auxiliary bus is the
			 * odd one out, selecting no internal pull, which is
			 * what a bus with board pull-ups looks like.
			 *
			 * Downstream parks the three sensor buses as plain
			 * inputs while the camera is off (its "off_i2c" state)
			 * and only selects the I2C function on power-up, to
			 * avoid feeding an unpowered sensor through the pull.
			 * Mainline's i2c core has only a "default" state, so
			 * these stay in I2C function; the leakage is one
			 * internal pull-up per line into the sensor's I/O
			 * clamp.
			 */
			hsi2c2_bus: hsi2c2-bus-pins {
				samsung,pins = "gpp4-0", "gpp4-1";
				samsung,pin-function = <ZUMAPRO_PIN_FUNC_3>;
				samsung,pin-pud = <ZUMAPRO_PIN_PULL_UP>;
				samsung,pin-drv = <ZUMAPRO_PIN_DRV_X1>;
			};

			hsi2c3_bus: hsi2c3-bus-pins {
				samsung,pins = "gpp6-0", "gpp6-1";
				samsung,pin-function = <ZUMAPRO_PIN_FUNC_3>;
				samsung,pin-pud = <ZUMAPRO_PIN_PULL_UP>;
				samsung,pin-drv = <ZUMAPRO_PIN_DRV_X1>;
			};

			hsi2c4_bus: hsi2c4-bus-pins {
				samsung,pins = "gpp8-0", "gpp8-1";
				samsung,pin-function = <ZUMAPRO_PIN_FUNC_3>;
				samsung,pin-pud = <ZUMAPRO_PIN_PULL_NONE>;
				samsung,pin-drv = <ZUMAPRO_PIN_DRV_X1>;
			};

			hsi2c5_bus: hsi2c5-bus-pins {
				samsung,pins = "gpp10-0", "gpp10-1";
				samsung,pin-function = <ZUMAPRO_PIN_FUNC_3>;
				samsung,pin-pud = <ZUMAPRO_PIN_PULL_UP>;
				samsung,pin-drv = <ZUMAPRO_PIN_DRV_X1>;
			};

			/* Source: research/dumped.dts:3550-3561. */
			disp_te_pri_on: disp-te-pri-on-pins {
				samsung,pins = "gpp0-3";
				samsung,pin-function = <ZUMAPRO_PIN_FUNC_EINT>;
			};

			disp_te_pri_off: disp-te-pri-off-pins {
				samsung,pins = "gpp0-3";
				samsung,pin-function = <ZUMAPRO_PIN_FUNC_INPUT>;
			};
		};

		pinctrl_peric1: pinctrl@10c40000 {
			compatible = "google,zumapro-pinctrl";
			reg = <0x10c40000 0x1000>;
			interrupts = <GIC_SPI 649 IRQ_TYPE_LEVEL_HIGH 0>;
			status = "okay";

			gpp19: gpp19-gpio-bank {
				gpio-controller;
				#gpio-cells = <2>;
				interrupt-controller;
				#interrupt-cells = <2>;
			};

			gpp20: gpp20-gpio-bank {
				gpio-controller;
				#gpio-cells = <2>;
				interrupt-controller;
				#interrupt-cells = <2>;
			};

			gpp21: gpp21-gpio-bank {
				gpio-controller;
				#gpio-cells = <2>;
				interrupt-controller;
				#interrupt-cells = <2>;
			};

			gpp24: gpp24-gpio-bank {
				gpio-controller;
				#gpio-cells = <2>;
				interrupt-controller;
				#interrupt-cells = <2>;
			};

			gpp22: gpp22-gpio-bank {
				gpio-controller;
				#gpio-cells = <2>;
				interrupt-controller;
				#interrupt-cells = <2>;
			};

			gpp23: gpp23-gpio-bank {
				gpio-controller;
				#gpio-cells = <2>;
				interrupt-controller;
				#interrupt-cells = <2>;
			};

			hsi2c10_bus: hsi2c10-bus-pins {
				samsung,pins = "gpp20-0", "gpp20-1";
				samsung,pin-function = <ZUMAPRO_PIN_FUNC_2>;
				samsung,pin-pud = <ZUMAPRO_PIN_PULL_NONE>;
				samsung,pin-drv = <ZUMAPRO_PIN_DRV_X1>;
			};

			hsi2c9_bus: hsi2c9-bus-pins {
				samsung,pins = "gpp19-4", "gpp19-5";
				samsung,pin-function = <ZUMAPRO_PIN_FUNC_2>;
				samsung,pin-pud = <ZUMAPRO_PIN_PULL_NONE>;
				samsung,pin-drv = <ZUMAPRO_PIN_DRV_X1>;
			};
		};

		pinctrl_hsi0: pinctrl@12040000 {
			compatible = "google,zumapro-pinctrl";
			reg = <0x12040000 0x1000>;
			interrupts = <GIC_SPI 413 IRQ_TYPE_LEVEL_HIGH 0>;
			status = "disabled";

			gph0: gph0-gpio-bank {
				gpio-controller;
				#gpio-cells = <2>;
				interrupt-controller;
				#interrupt-cells = <2>;
			};

			gph1: gph1-gpio-bank {
				gpio-controller;
				#gpio-cells = <2>;
				interrupt-controller;
				#interrupt-cells = <2>;
			};

			gph2: gph2-gpio-bank {
				gpio-controller;
				#gpio-cells = <2>;
				interrupt-controller;
				#interrupt-cells = <2>;
			};
		};

		pinctrl_hsi1: pinctrl@13040000 {
			compatible = "google,zumapro-pinctrl";
			reg = <0x13040000 0x1000>;
			clocks = <&cmu_hsi2 CLK_GOUT_HSI2_GPIO_HSI2_PCLK>;
			clock-names = "pclk";
			interrupts = <GIC_SPI 432 IRQ_TYPE_LEVEL_HIGH 0>;
			status = "disabled";

			gph3: gph3-gpio-bank {
				gpio-controller;
				#gpio-cells = <2>;
				interrupt-controller;
				#interrupt-cells = <2>;
			};

			gph4: gph4-gpio-bank {
				gpio-controller;
				#gpio-cells = <2>;
				interrupt-controller;
				#interrupt-cells = <2>;
			};
		};

		pinctrl_hsi2: pinctrl@13060000 {
			compatible = "google,zumapro-pinctrl";
			reg = <0x13060000 0x1000>;
			clocks = <&cmu_hsi2 CLK_GOUT_HSI2_GPIO_HSI2UFS_PCLK>;
			clock-names = "pclk";
			interrupts = <GIC_SPI 433 IRQ_TYPE_LEVEL_HIGH 0>;
			status = "okay";

			gph5: gph5-gpio-bank {
				gpio-controller;
				#gpio-cells = <2>;
				interrupt-controller;
				#interrupt-cells = <2>;
			};

			ufs_rst_n: ufs-rst-n-pins {
				samsung,pins = "gph5-1";
				samsung,pin-function = <ZUMAPRO_PIN_FUNC_2>;
				samsung,pin-pud = <ZUMAPRO_PIN_PULL_NONE>;
				samsung,pin-con-pdn = <ZUMAPRO_PIN_CON_PDN_OUTPUT_HIGH>;
				samsung,pin-pud-pdn = <ZUMAPRO_PIN_PULL_NONE>;
			};

			ufs_refclk_out: ufs-refclk-out-pins {
				samsung,pins = "gph5-0";
				samsung,pin-function = <ZUMAPRO_PIN_FUNC_2>;
				samsung,pin-pud = <ZUMAPRO_PIN_PULL_NONE>;
				samsung,pin-con-pdn = <ZUMAPRO_PIN_CON_PDN_OUTPUT_HIGH>;
				samsung,pin-pud-pdn = <ZUMAPRO_PIN_PULL_NONE>;
				samsung,pin-drv = <ZUMAPRO_PIN_DRV_X3>;
			};
		};

		pinctrl_eint: pinctrl@15060000 {
			compatible = "google,zumapro-pinctrl";
			reg = <0x15060000 0x1000>;
			status = "okay";

			gpn0: gpn0-gpio-bank {
				gpio-controller;
				#gpio-cells = <2>;
				interrupt-controller;
				#interrupt-cells = <2>;
				interrupt-parent = <&gic>;
				interrupts = <GIC_SPI 0 IRQ_TYPE_LEVEL_HIGH 0>;
			};

			gpn1: gpn1-gpio-bank {
				gpio-controller;
				#gpio-cells = <2>;
				interrupt-controller;
				#interrupt-cells = <2>;
				interrupt-parent = <&gic>;
				interrupts = <GIC_SPI 1 IRQ_TYPE_LEVEL_HIGH 0>;
			};

			gpn2: gpn2-gpio-bank {
				gpio-controller;
				#gpio-cells = <2>;
				interrupt-controller;
				#interrupt-cells = <2>;
				interrupt-parent = <&gic>;
				interrupts = <GIC_SPI 2 IRQ_TYPE_LEVEL_HIGH 0>;
			};

			gpn3: gpn3-gpio-bank {
				gpio-controller;
				#gpio-cells = <2>;
				interrupt-controller;
				#interrupt-cells = <2>;
				interrupt-parent = <&gic>;
				interrupts = <GIC_SPI 3 IRQ_TYPE_LEVEL_HIGH 0>;
			};

			gpn4: gpn4-gpio-bank {
				gpio-controller;
				#gpio-cells = <2>;
				interrupt-controller;
				#interrupt-cells = <2>;
				interrupt-parent = <&gic>;
				interrupts = <GIC_SPI 4 IRQ_TYPE_LEVEL_HIGH 0>;
			};

			gpn5: gpn5-gpio-bank {
				gpio-controller;
				#gpio-cells = <2>;
				interrupt-controller;
				#interrupt-cells = <2>;
				interrupt-parent = <&gic>;
				interrupts = <GIC_SPI 5 IRQ_TYPE_LEVEL_HIGH 0>;
			};

			gpn6: gpn6-gpio-bank {
				gpio-controller;
				#gpio-cells = <2>;
				interrupt-controller;
				#interrupt-cells = <2>;
				interrupt-parent = <&gic>;
				interrupts = <GIC_SPI 6 IRQ_TYPE_LEVEL_HIGH 0>;
			};

			gpn7: gpn7-gpio-bank {
				gpio-controller;
				#gpio-cells = <2>;
				interrupt-controller;
				#interrupt-cells = <2>;
				interrupt-parent = <&gic>;
				interrupts = <GIC_SPI 7 IRQ_TYPE_LEVEL_HIGH 0>;
			};

			gpn8: gpn8-gpio-bank {
				gpio-controller;
				#gpio-cells = <2>;
				interrupt-controller;
				#interrupt-cells = <2>;
				interrupt-parent = <&gic>;
				interrupts = <GIC_SPI 8 IRQ_TYPE_LEVEL_HIGH 0>;
			};

			gpn9: gpn9-gpio-bank {
				gpio-controller;
				#gpio-cells = <2>;
				interrupt-controller;
				#interrupt-cells = <2>;
				interrupt-parent = <&gic>;
				interrupts = <GIC_SPI 9 IRQ_TYPE_LEVEL_HIGH 0>;
			};

			wakeup-interrupt-controller {
				compatible = "google,zumapro-wakeup-eint",
					     "samsung,exynos850-wakeup-eint",
					     "samsung,exynos7-wakeup-eint";
			};
		};

		/*
		 * Interrupt combiner the APM uses to forward the PMICs'
		 * in-band I3C interrupts to the AP. Its INTC0 pending register
		 * is a write-1-to-clear latch that has to be acknowledged
		 * before the level-triggered GIC line will deassert.
		 */
		sysreg_vgpio2ap: syscon@15090000 {
			compatible = "google,zumapro-vgpio2ap-sysreg", "syscon";
			reg = <0x15090000 0x1000>;
		};

		pinctrl_alive: pinctrl@154d0000 {
			compatible = "google,zumapro-pinctrl";
			reg = <0x154d0000 0x1000>;
			status = "okay";

			gpa0: gpa0-gpio-bank {
				gpio-controller;
				#gpio-cells = <2>;
				interrupt-controller;
				#interrupt-cells = <2>;
				interrupt-parent = <&gic>;
				interrupts = <GIC_SPI 10 IRQ_TYPE_LEVEL_HIGH 0>,
					     <GIC_SPI 11 IRQ_TYPE_LEVEL_HIGH 0>,
					     <GIC_SPI 12 IRQ_TYPE_LEVEL_HIGH 0>,
					     <GIC_SPI 13 IRQ_TYPE_LEVEL_HIGH 0>;
			};

			gpa1: gpa1-gpio-bank {
				gpio-controller;
				#gpio-cells = <2>;
				interrupt-controller;
				#interrupt-cells = <2>;
				interrupt-parent = <&gic>;
				interrupts = <GIC_SPI 14 IRQ_TYPE_LEVEL_HIGH 0>,
					     <GIC_SPI 15 IRQ_TYPE_LEVEL_HIGH 0>,
					     <GIC_SPI 16 IRQ_TYPE_LEVEL_HIGH 0>,
					     <GIC_SPI 17 IRQ_TYPE_LEVEL_HIGH 0>,
					     <GIC_SPI 18 IRQ_TYPE_LEVEL_HIGH 0>,
					     <GIC_SPI 19 IRQ_TYPE_LEVEL_HIGH 0>;
			};

			gpa2: gpa2-gpio-bank {
				gpio-controller;
				#gpio-cells = <2>;
				interrupt-controller;
				#interrupt-cells = <2>;
				interrupt-parent = <&gic>;
				interrupts = <GIC_SPI 20 IRQ_TYPE_LEVEL_HIGH 0>,
					     <GIC_SPI 21 IRQ_TYPE_LEVEL_HIGH 0>,
					     <GIC_SPI 22 IRQ_TYPE_LEVEL_HIGH 0>,
					     <GIC_SPI 23 IRQ_TYPE_LEVEL_HIGH 0>;
			};

			gpa3: gpa3-gpio-bank {
				gpio-controller;
				#gpio-cells = <2>;
				interrupt-controller;
				#interrupt-cells = <2>;
				interrupt-parent = <&gic>;
				interrupts = <GIC_SPI 24 IRQ_TYPE_LEVEL_HIGH 0>,
					     <GIC_SPI 25 IRQ_TYPE_LEVEL_HIGH 0>,
					     <GIC_SPI 26 IRQ_TYPE_LEVEL_HIGH 0>,
					     <GIC_SPI 27 IRQ_TYPE_LEVEL_HIGH 0>;
			};

			gpa4: gpa4-gpio-bank {
				gpio-controller;
				#gpio-cells = <2>;
				interrupt-controller;
				#interrupt-cells = <2>;
				interrupt-parent = <&gic>;
				interrupts = <GIC_SPI 28 IRQ_TYPE_LEVEL_HIGH 0>,
					     <GIC_SPI 29 IRQ_TYPE_LEVEL_HIGH 0>;
			};

			gpa6: gpa6-gpio-bank {
				gpio-controller;
				#gpio-cells = <2>;
				interrupt-controller;
				#interrupt-cells = <2>;
				interrupt-parent = <&gic>;
				interrupts = <GIC_SPI 30 IRQ_TYPE_LEVEL_HIGH 0>,
					     <GIC_SPI 31 IRQ_TYPE_LEVEL_HIGH 0>,
					     <GIC_SPI 32 IRQ_TYPE_LEVEL_HIGH 0>,
					     <GIC_SPI 33 IRQ_TYPE_LEVEL_HIGH 0>,
					     <GIC_SPI 34 IRQ_TYPE_LEVEL_HIGH 0>,
					     <GIC_SPI 35 IRQ_TYPE_LEVEL_HIGH 0>;
			};

			gpa7: gpa7-gpio-bank {
				gpio-controller;
				#gpio-cells = <2>;
				interrupt-controller;
				#interrupt-cells = <2>;
				interrupt-parent = <&gic>;
				interrupts = <GIC_SPI 36 IRQ_TYPE_LEVEL_HIGH 0>,
					     <GIC_SPI 37 IRQ_TYPE_LEVEL_HIGH 0>,
					     <GIC_SPI 38 IRQ_TYPE_LEVEL_HIGH 0>,
					     <GIC_SPI 39 IRQ_TYPE_LEVEL_HIGH 0>,
					     <GIC_SPI 40 IRQ_TYPE_LEVEL_HIGH 0>,
					     <GIC_SPI 41 IRQ_TYPE_LEVEL_HIGH 0>,
					     <GIC_SPI 42 IRQ_TYPE_LEVEL_HIGH 0>,
					     <GIC_SPI 43 IRQ_TYPE_LEVEL_HIGH 0>;
			};

			gpa8: gpa8-gpio-bank {
				gpio-controller;
				#gpio-cells = <2>;
				interrupt-controller;
				#interrupt-cells = <2>;
				interrupt-parent = <&gic>;
				interrupts = <GIC_SPI 44 IRQ_TYPE_LEVEL_HIGH 0>,
					     <GIC_SPI 45 IRQ_TYPE_LEVEL_HIGH 0>,
					     <GIC_SPI 46 IRQ_TYPE_LEVEL_HIGH 0>,
					     <GIC_SPI 47 IRQ_TYPE_LEVEL_HIGH 0>;
			};

			gpa9: gpa9-gpio-bank {
				gpio-controller;
				#gpio-cells = <2>;
				interrupt-controller;
				#interrupt-cells = <2>;
				interrupt-parent = <&gic>;
				interrupts = <GIC_SPI 48 IRQ_TYPE_LEVEL_HIGH 0>,
					     <GIC_SPI 49 IRQ_TYPE_LEVEL_HIGH 0>,
					     <GIC_SPI 50 IRQ_TYPE_LEVEL_HIGH 0>,
					     <GIC_SPI 51 IRQ_TYPE_LEVEL_HIGH 0>,
					     <GIC_SPI 52 IRQ_TYPE_LEVEL_HIGH 0>,
					     <GIC_SPI 53 IRQ_TYPE_LEVEL_HIGH 0>,
					     <GIC_SPI 54 IRQ_TYPE_LEVEL_HIGH 0>;
			};

			gpa10: gpa10-gpio-bank {
				gpio-controller;
				#gpio-cells = <2>;
				interrupt-controller;
				#interrupt-cells = <2>;
				interrupt-parent = <&gic>;
				interrupts = <GIC_SPI 55 IRQ_TYPE_LEVEL_HIGH 0>,
					     <GIC_SPI 56 IRQ_TYPE_LEVEL_HIGH 0>,
					     <GIC_SPI 57 IRQ_TYPE_LEVEL_HIGH 0>,
					     <GIC_SPI 58 IRQ_TYPE_LEVEL_HIGH 0>,
					     <GIC_SPI 59 IRQ_TYPE_LEVEL_HIGH 0>;
			};

			gpa11: gpa11-gpio-bank {
				gpio-controller;
				#gpio-cells = <2>;
			};

			gpa12: gpa12-gpio-bank {
				gpio-controller;
				#gpio-cells = <2>;
			};

			/*
			 * uart18 (APM_USI1 UART) 4-wire bus = Bluetooth HCI.
			 * gpa3-0..3 alt-func 2 from research/dumped.dts uart18_bus
			 * (downstream zumapro-pinctrl.dtsi:1200).
			 */
			uart18_bus: uart18-bus-pins {
				samsung,pins = "gpa3-0", "gpa3-1", "gpa3-2", "gpa3-3";
				samsung,pin-function = <ZUMAPRO_PIN_FUNC_2>;
				samsung,pin-pud = <ZUMAPRO_PIN_PULL_NONE>;
			};

			wakeup-interrupt-controller {
				compatible = "google,zumapro-wakeup-eint",
					     "samsung,exynos850-wakeup-eint",
					     "samsung,exynos7-wakeup-eint";
			};
		};

		pinctrl_far_alive: pinctrl@154e0000 {
			compatible = "google,zumapro-pinctrl";
			reg = <0x154e0000 0x1000>;
			status = "okay";

			gpa5: gpa5-gpio-bank {
				gpio-controller;
				#gpio-cells = <2>;
				interrupt-controller;
				#interrupt-cells = <2>;
				interrupt-parent = <&gic>;
				interrupts = <GIC_SPI 60 IRQ_TYPE_LEVEL_HIGH 0>,
					     <GIC_SPI 61 IRQ_TYPE_LEVEL_HIGH 0>,
					     <GIC_SPI 62 IRQ_TYPE_LEVEL_HIGH 0>,
					     <GIC_SPI 63 IRQ_TYPE_LEVEL_HIGH 0>,
					     <GIC_SPI 64 IRQ_TYPE_LEVEL_HIGH 0>,
					     <GIC_SPI 65 IRQ_TYPE_LEVEL_HIGH 0>,
					     <GIC_SPI 66 IRQ_TYPE_LEVEL_HIGH 0>,
					     <GIC_SPI 67 IRQ_TYPE_LEVEL_HIGH 0>;
			};

			wakeup-interrupt-controller {
				compatible = "google,zumapro-wakeup-eint",
					     "samsung,exynos850-wakeup-eint",
					     "samsung,exynos7-wakeup-eint";
			};
		};

		/*
		 * Source: PMU syscon address is from research/dumped.dts:15242-15246.
		 * Downstream uses "samsung,gs101-pmu", "syscon"; this minimal tree
		 * uses a Zumapro-specific syscon compatible so the watchdog can resolve
		 * its PMU phandle before an upstream Zumapro PMU driver exists.
		 */
		pmu_system_controller: system-controller@15460000 {
			compatible = "google,zumapro-pmu", "syscon";
			reg = <0x15460000 0x10000>;

			/*
			 * Where the bootloader takes the reboot mode from after
			 * a *warm* reset, same node and offset as gs101.  A cold
			 * reset clears this register, and then the bootloader
			 * reads the MAX77779 battery-backed scratchpad instead
			 * (nvmem-reboot-mode, see zumapro-tegu.dts) -- so the
			 * two stores are not redundant, they cover different
			 * reset types, which is why downstream's
			 * pixel-zuma-reboot.c writes both [HW 2026-08-10].  The
			 * values differ accordingly: the raw mode here, because
			 * a cold reset zeroes it, and the mode or'd with
			 * BMS_RSBM_VALID there, because battery-backed RAM has
			 * no power-on state and needs a validity marker.
			 *
			 * Reaching this register from EL1 is only possible
			 * because exynos-pmu registers an SMC-backed regmap as
			 * this node's syscon.
			 */
			reboot-mode {
				compatible = "syscon-reboot-mode";
				offset = <0x0810>; /* EXYNOS_PMU_SYSIP_DAT0 */
				mode-bootloader = <0xfc>;
				mode-charge = <0x0a>;
				mode-dm-verity-device-corrupted = <0x50>;
				mode-fastboot = <0xfa>;
				mode-reboot-ab-update = <0x52>;
				mode-recovery = <0xff>;
				mode-rescue = <0xf9>;
				mode-shutdown-thermal = <0x51>;
				mode-shutdown-thermal-battery = <0x51>;
			};
		};

		/*
		 * Source: AP2APM mailbox base and IRQ are from the downstream
		 * ACPM node in research/dumped.dts:15292-15296 (reg 0x15110000,
		 * GIC SPI 80).  The register layout was hardware-verified by
		 * tracing the downstream kernel under the m1n1 hypervisor:
		 * doorbell = 1 << channel to INTGR1 (+0x40), AP-side ack/status
		 * on INTCR0/INTSR0, exactly the gs101 driver's model.  The
		 * mailbox pclk sits in the always-on APM block with no mainline
		 * CMU support; ext_24_5m stands in for it like the watchdog
		 * clocks below.
		 */
		ap2apm_mailbox: mailbox@15110000 {
			compatible = "google,zumapro-mbox", "google,gs101-mbox";
			reg = <0x15110000 0x1000>;
			clocks = <&ext_24_5m>;
			clock-names = "pclk";
			interrupts = <GIC_SPI 80 IRQ_TYPE_LEVEL_HIGH 0>;
			#mbox-cells = <0>;
		};

		pinctrl_gsacore4: pinctrl@16140000 {
			compatible = "google,zumapro-pinctrl";
			reg = <0x16140000 0x1000>;
			status = "disabled";
		};

		pinctrl_gsacore0: pinctrl@16280000 {
			compatible = "google,zumapro-pinctrl";
			reg = <0x16280000 0x1000>;
			status = "disabled";
		};

		pinctrl_gsacore1: pinctrl@16290000 {
			compatible = "google,zumapro-pinctrl";
			reg = <0x16290000 0x1000>;
			status = "disabled";
		};

		pinctrl_gsacore2: pinctrl@162a0000 {
			compatible = "google,zumapro-pinctrl";
			reg = <0x162a0000 0x1000>;
			status = "disabled";
		};

		pinctrl_gsacore3: pinctrl@162b0000 {
			compatible = "google,zumapro-pinctrl";
			reg = <0x162b0000 0x1000>;
			status = "disabled";
		};

		/*
		 * Source: watchdog addresses, IRQs, timeout, and PMU phandle are from
		 * research/dumped.dts:15248-15268.  The compatible, clock-name, and
		 * samsung,cluster-index properties follow the upstream samsung-wdt
		 * binding used by GS101; verify PMU bit definitions before relying on
		 * reset behavior.
		 */
		watchdog_cl0: watchdog@10060000 {
			compatible = "google,gs101-wdt";
			reg = <0x10060000 0x100>;
			clocks = <&ext_24_5m>, <&ext_24_5m>;
			clock-names = "watchdog", "watchdog_src";
			interrupts = <GIC_SPI 767 IRQ_TYPE_LEVEL_HIGH 0>;
			samsung,syscon-phandle = <&pmu_system_controller>;
			samsung,cluster-index = <0>;
			timeout-sec = <30>;
			status = "disabled";
		};

		watchdog_cl1: watchdog@10070000 {
			compatible = "google,gs101-wdt";
			reg = <0x10070000 0x100>;
			clocks = <&ext_24_5m>, <&ext_24_5m>;
			clock-names = "watchdog", "watchdog_src";
			interrupts = <GIC_SPI 768 IRQ_TYPE_LEVEL_HIGH 0>;
			samsung,syscon-phandle = <&pmu_system_controller>;
			samsung,cluster-index = <1>;
			timeout-sec = <30>;
			status = "disabled";
		};

		/*
		 * Source: downstream sysmmu@1C110000/@1C150000/@1C190000 in
		 * research/dumped.dts:918-975.  BLK_ISPFE's three Samsung
		 * System MMU v9 instances, all in the same translation context:
		 * a frame buffer's IOVA shows up in every one of their
		 * IOTLB-invalidate registers, so the camera names all three and
		 * lets the v9 driver share one page table between them.
		 *
		 * Three downstream properties are deliberately not carried over.
		 * "sysmmu,async-fault" is parsed there and then never read
		 * again, so it selects nothing.  "sysmmu,ap-read-implies-write"
		 * grants write permission wherever read is granted, which only
		 * changes read-only mappings -- and every mapping the camera
		 * makes is a coherent allocation, already both.  And "s2mpus"
		 * names the stage-2 protection units, which the bootloader
		 * leaves open, as the GPU bring-up established.
		 */
		sysmmu_ispfe_s0: iommu@1c110000 {
			compatible = "samsung,sysmmu-v9";
			reg = <0x1c110000 0x10000>;
			interrupts = <GIC_SPI 488 IRQ_TYPE_LEVEL_HIGH 0>,
				     <GIC_SPI 489 IRQ_TYPE_LEVEL_HIGH 0>;
			power-domains = <&pd_ispfe>;
			samsung,qos = <15>;
			samsung,secure-irq;
			samsung,secure-base = <0x1c120000>;
			samsung,port-name = "ISPFE S0";
			samsung,pmmu0-default-stream = <0x6030106>;
			samsung,pmmu0-stream-property =
				<0x01 0x106 0x201 0x20 0x78>,
				<0x02 0x1010106 0x201 0x28 0x78>,
				<0x03 0x2020106 0x201 0x30 0x78>,
				<0x04 0x3040106 0x201 0x40 0x78>,
				<0x05 0x4050106 0x201 0x48 0x78>,
				<0x06 0x5060106 0x201 0x50 0x78>,
				<0x07 0x9080106 0x101 0x40 0x60>,
				<0x08 0x8070106 0x101 0x20 0x60>;
			samsung,pmmu1-default-stream = <0x7030106>;
			samsung,pmmu1-stream-property =
				<0x01 0x106 0x201 0x28 0x78>,
				<0x02 0x1010106 0x201 0x30 0x78>,
				<0x03 0x2020106 0x201 0x38 0x78>,
				<0x04 0x3040106 0x201 0x40 0x78>,
				<0x05 0x4050106 0x201 0x48 0x78>,
				<0x06 0x5060106 0x201 0x50 0x78>;
			#iommu-cells = <0>;
			status = "disabled";
		};

		sysmmu_ispfe_s1: iommu@1c150000 {
			compatible = "samsung,sysmmu-v9";
			reg = <0x1c150000 0x10000>;
			interrupts = <GIC_SPI 492 IRQ_TYPE_LEVEL_HIGH 0>,
				     <GIC_SPI 493 IRQ_TYPE_LEVEL_HIGH 0>;
			power-domains = <&pd_ispfe>;
			samsung,qos = <15>;
			samsung,secure-irq;
			samsung,secure-base = <0x1c160000>;
			samsung,port-name = "ISPFE S1";
			samsung,pmmu0-default-stream = <0x106>;
			#iommu-cells = <0>;
			status = "disabled";
		};

		sysmmu_ispfe_s2: iommu@1c190000 {
			compatible = "samsung,sysmmu-v9";
			reg = <0x1c190000 0x10000>;
			interrupts = <GIC_SPI 496 IRQ_TYPE_LEVEL_HIGH 0>,
				     <GIC_SPI 497 IRQ_TYPE_LEVEL_HIGH 0>;
			power-domains = <&pd_ispfe>;
			samsung,qos = <15>;
			samsung,secure-irq;
			samsung,secure-base = <0x1c1a0000>;
			samsung,port-name = "ISPFE S2";
			samsung,pmmu0-default-stream = <0x106>;
			samsung,pmmu0-stream-property =
				<0x01 0x106 0x201 0x60 0x60>,
				<0x02 0x106 0x201 0x60 0x60>,
				<0x03 0x3030106 0x201 0x00 0x60>,
				<0x04 0x1010106 0x201 0x20 0x60>,
				<0x05 0x2020106 0x201 0x60 0x60>;
			#iommu-cells = <0>;
			status = "disabled";
		};

		/*
		 * Camera back-end System MMUs.  The bases, fault IRQs, secure
		 * windows and all stream tables are the downstream Zumapro values.
		 * RGBP has two controllers with two and five PMMUs respectively;
		 * YUVP has one.  GDC has three PMMUs and is included because RGBP's
		 * command loader resides in that domain.  They stay disabled with
		 * their power domains until a BE-core consumer can restore every
		 * domain CMU and open every S2MPU before DMA is enabled.
		 */
		sysmmu_gdc: iommu@1d4c0000 {
			compatible = "samsung,sysmmu-v9";
			reg = <0x1d4c0000 0x10000>;
			interrupts = <GIC_SPI 371 IRQ_TYPE_LEVEL_HIGH 0>,
				     <GIC_SPI 372 IRQ_TYPE_LEVEL_HIGH 0>;
			power-domains = <&pd_gdc>;
			samsung,qos = <15>;
			samsung,secure-irq;
			samsung,secure-base = <0x1d4d0000>;
			samsung,port-name = "GDC";
			samsung,pmmu0-default-stream = <0x15a>;
			samsung,pmmu0-stream-property =
				<0x01 0x15a 0x101 0x04 0x1f>,
				<0x02 0x1404010a 0x101 0x08 0x1f>,
				<0x03 0x1404010a 0x101 0x0c 0x1f>,
				<0x04 0x101015a 0x101 0x10 0x1f>,
				<0x05 0x101015a 0x101 0x14 0x1f>,
				<0x06 0x806011a 0x101 0x18 0x1f>,
				<0x07 0x806011a 0x101 0x1c 0x1f>,
				<0x08 0x402015a 0x201 0x00 0x1f>,
				<0x09 0x402015a 0x201 0x04 0x1f>,
				<0x0a 0x905010b 0x201 0x08 0x1f>,
				<0x0b 0x905010b 0x201 0x0c 0x1f>,
				<0x0c 0x503015a 0x201 0x10 0x1f>,
				<0x0d 0x503015a 0x201 0x14 0x1f>,
				<0x0e 0xa07010b 0x201 0x18 0x1f>,
				<0x0f 0xa07010b 0x201 0x1c 0x1f>,
				<0x10 0x17080108 0x201 0x01 0x0f>,
				<0x11 0x17080108 0x201 0x05 0x0f>,
				<0x12 0x18090108 0x101 0x03 0x0f>,
				<0x13 0x18090108 0x101 0x06 0x0f>;
			samsung,pmmu1-default-stream = <0x200015a>;
			samsung,pmmu1-stream-property =
				<0x01 0x200015a 0x101 0x04 0x1f>,
				<0x02 0x1504010a 0x101 0x08 0x1f>,
				<0x03 0x1504010a 0x101 0x0c 0x1f>,
				<0x04 0x301015a 0x101 0x10 0x1f>,
				<0x05 0x301015a 0x101 0x14 0x1f>,
				<0x06 0xb05010a 0x101 0x18 0x1f>,
				<0x07 0xb05010a 0x101 0x1c 0x1f>,
				<0x08 0x602015a 0x201 0x00 0x1f>,
				<0x09 0x602015a 0x201 0x04 0x1f>,
				<0x0a 0x1606010b 0x201 0x08 0x1f>,
				<0x0b 0x1606010b 0x201 0x0c 0x1f>,
				<0x0c 0x703015a 0x201 0x10 0x1f>,
				<0x0d 0x703015a 0x201 0x14 0x1f>,
				<0x0e 0xc07010b 0x201 0x18 0x1f>,
				<0x0f 0xc07010b 0x201 0x1c 0x1f>,
				<0x10 0x190c0108 0x201 0x01 0x0f>,
				<0x11 0x190c0108 0x201 0x05 0x0f>,
				<0x12 0x1a0d0108 0x101 0x02 0x0f>,
				<0x13 0x1a0d0108 0x101 0x06 0x0f>,
				<0x14 0x1b0e0108 0x101 0x03 0x0f>,
				<0x15 0x1b0e0108 0x101 0x07 0x0f>,
				<0x16 0xd08010b 0x201 0x03 0x0f>,
				<0x17 0xd09010b 0x201 0x07 0x0f>,
				<0x18 0xe0a010b 0x201 0x0b 0x0f>,
				<0x19 0xe0b010b 0x201 0x0f 0x0f>;
			samsung,pmmu2-default-stream = <0xf02010b>;
			samsung,pmmu2-stream-property =
				<0x01 0xf03010b 0x201 0x01 0x07>,
				<0x02 0x1004010b 0x201 0x02 0x07>,
				<0x03 0x1005010b 0x201 0x03 0x07>,
				<0x04 0x1300010a 0x101 0x00 0x07>,
				<0x05 0x1301010a 0x101 0x01 0x07>,
				<0x06 0x1106010b 0x101 0x02 0x07>,
				<0x07 0x1107010b 0x101 0x03 0x07>,
				<0x08 0x1208010b 0x201 0x04 0x07>,
				<0x09 0x1209010b 0x201 0x05 0x07>;
			#iommu-cells = <0>;
			status = "disabled";
		};

		sysmmu_yuvp: iommu@1c870000 {
			compatible = "samsung,sysmmu-v9";
			reg = <0x1c870000 0x10000>;
			interrupts = <GIC_SPI 740 IRQ_TYPE_LEVEL_HIGH 0>,
				     <GIC_SPI 741 IRQ_TYPE_LEVEL_HIGH 0>;
			power-domains = <&pd_yuvp>;
			samsung,qos = <15>;
			samsung,secure-irq;
			samsung,secure-base = <0x1c880000>;
			samsung,port-name = "YUVP";
			samsung,pmmu0-default-stream = <0x5050108>;
			samsung,pmmu0-stream-property =
				<0x01 0x5050108 0x101 0x04 0x1f>,
				<0x02 0x000010a 0x201 0x01 0x1f>,
				<0x03 0x000010a 0x201 0x05 0x1f>,
				<0x04 0x101010a 0x201 0x09 0x1f>,
				<0x05 0x101010a 0x201 0x0d 0x1f>,
				<0x06 0x202010a 0x201 0x11 0x1f>,
				<0x07 0x202010a 0x201 0x15 0x1f>,
				<0x08 0x303010a 0x201 0x19 0x1f>,
				<0x09 0x303010a 0x201 0x1d 0x1f>,
				<0x0a 0x404010a 0x101 0x02 0x1f>,
				<0x0b 0x404010a 0x101 0x06 0x1f>,
				<0x0c 0x6060108 0x201 0x02 0x1f>,
				<0x0d 0x6060108 0x201 0x06 0x1f>;
			#iommu-cells = <0>;
			status = "disabled";
		};

		sysmmu_rgbp_s0: iommu@1c4a0000 {
			compatible = "samsung,sysmmu-v9";
			reg = <0x1c4a0000 0x10000>;
			interrupts = <GIC_SPI 675 IRQ_TYPE_LEVEL_HIGH 0>,
				     <GIC_SPI 676 IRQ_TYPE_LEVEL_HIGH 0>;
			power-domains = <&pd_rgbp>;
			samsung,qos = <15>;
			samsung,secure-irq;
			samsung,secure-base = <0x1c4b0000>;
			samsung,port-name = "RGBP S0";
			samsung,pmmu0-default-stream = <0x10b>;
			samsung,pmmu0-stream-property =
				<0x01 0x000010b 0x101 0x02 0x07>,
				<0x02 0x101010b 0x201 0x00 0x07>,
				<0x03 0x101010b 0x201 0x02 0x07>,
				<0x04 0x202010b 0x201 0x04 0x07>,
				<0x05 0x202010b 0x201 0x06 0x07>,
				<0x06 0x303010b 0x201 0x01 0x07>,
				<0x07 0x303010b 0x201 0x03 0x07>;
			samsung,pmmu1-default-stream = <0x400010b>;
			samsung,pmmu1-stream-property =
				<0x01 0x602010b 0x101 0x0c 0x0b>,
				<0x02 0x501010b 0x201 0x00 0x0b>,
				<0x04 0x602010b 0x101 0x01 0x0f>,
				<0x05 0x602010b 0x101 0x05 0x0f>,
				<0x06 0x703010b 0x201 0x01 0x0f>,
				<0x07 0x703010b 0x201 0x05 0x0f>,
				<0x08 0x804010b 0x201 0x09 0x0f>,
				<0x09 0x804010b 0x201 0x0d 0x0f>,
				<0x0a 0x905010b 0x201 0x02 0x0f>,
				<0x0b 0x905010b 0x201 0x06 0x0f>,
				<0x0c 0xa060108 0x201 0x02 0x0f>,
				<0x0d 0xa060108 0x201 0x06 0x0f>;
			#iommu-cells = <0>;
			status = "disabled";
		};

		sysmmu_rgbp_s1: iommu@1c4e0000 {
			compatible = "samsung,sysmmu-v9";
			reg = <0x1c4e0000 0x10000>;
			interrupts = <GIC_SPI 679 IRQ_TYPE_LEVEL_HIGH 0>,
				     <GIC_SPI 680 IRQ_TYPE_LEVEL_HIGH 0>;
			power-domains = <&pd_rgbp>;
			samsung,qos = <15>;
			samsung,secure-irq;
			samsung,secure-base = <0x1c4f0000>;
			samsung,port-name = "RGBP S1";
			samsung,pmmu0-default-stream = <0x15a>;
			samsung,pmmu0-stream-property =
				<0x01 0x000015a 0x101 0x00 0x05>,
				<0x02 0x001015a 0x101 0x01 0x05>,
				<0x03 0x001015a 0x101 0x01 0x05>,
				<0x04 0x302010b 0x101 0x04 0x05>,
				<0x05 0x302010b 0x101 0x04 0x05>,
				<0x06 0x303010b 0x101 0x05 0x05>,
				<0x07 0x303010b 0x101 0x05 0x05>;
			samsung,pmmu1-default-stream = <0x400010a>;
			samsung,pmmu1-stream-property =
				<0x01 0x400010a 0x101 0x01 0x03>,
				<0x02 0x201014b 0x101 0x02 0x03>,
				<0x03 0x201014b 0x101 0x03 0x03>;
			samsung,pmmu2-default-stream = <0x100015a>;
			samsung,pmmu2-stream-property =
				<0x01 0x100015a 0x101 0x01 0x03>,
				<0x02 0x401010b 0x101 0x02 0x03>,
				<0x03 0x401010b 0x101 0x03 0x03>;
			samsung,pmmu3-default-stream = <0x200014a>;
			samsung,pmmu3-stream-property =
				<0x01 0x200014a 0x101 0x04 0x0f>,
				<0x02 0x501010b 0x201 0x00 0x0f>,
				<0x03 0x501010b 0x201 0x04 0x0f>,
				<0x04 0x602010b 0x101 0x01 0x0f>,
				<0x05 0x602010b 0x101 0x05 0x0f>,
				<0x06 0x703010b 0x201 0x01 0x0f>,
				<0x07 0x703010b 0x201 0x05 0x0f>,
				<0x08 0x804010b 0x201 0x09 0x0f>,
				<0x09 0x804010b 0x201 0x0d 0x0f>,
				<0x0a 0x10050108 0x101 0x02 0x0f>,
				<0x0b 0x10050108 0x101 0x06 0x0f>;
			samsung,pmmu4-default-stream = <0xa00010b>;
			samsung,pmmu4-stream-property =
				<0x01 0xa00010b 0x101 0x08 0x1f>,
				<0x02 0xb01010b 0x201 0x00 0x1f>,
				<0x03 0xb01010b 0x201 0x08 0x1f>,
				<0x04 0xc02010b 0x201 0x10 0x1f>,
				<0x05 0xc02010b 0x201 0x18 0x1f>,
				<0x06 0xd03010b 0x101 0x01 0x1f>,
				<0x07 0xd03010b 0x101 0x09 0x1f>,
				<0x08 0xe04010b 0x101 0x02 0x1f>,
				<0x09 0xe04010b 0x101 0x0a 0x1f>,
				<0x0a 0xf05010b 0x101 0x03 0x1f>,
				<0x0b 0xf05010b 0x101 0x0b 0x1f>,
				<0x0c 0x500010b 0x101 0x04 0x1f>,
				<0x0d 0x500010b 0x101 0x0c 0x1f>;
			#iommu-cells = <0>;
			status = "disabled";
		};

		/*
		 * GTNR merge has two System MMUs in BLK_TNR.  The stream tables,
		 * secure fault windows and IRQs are copied from downstream Zumapro;
		 * both remain passive until a GTNR consumer owns the domain reset and
		 * DMA lifecycle.
		 */
		sysmmu_tnr_s0: iommu@1cc80000 {
			compatible = "samsung,sysmmu-v9";
			reg = <0x1cc80000 0x10000>;
			interrupts = <GIC_SPI 683 IRQ_TYPE_LEVEL_HIGH 0>,
				     <GIC_SPI 684 IRQ_TYPE_LEVEL_HIGH 0>;
			power-domains = <&pd_tnr>;
			samsung,qos = <15>;
			samsung,secure-irq;
			samsung,secure-base = <0x1cc90000>;
			samsung,port-name = "TNR S0";
			samsung,pmmu0-default-stream = <0x4010b>;
			samsung,pmmu0-stream-property =
				<0x01 0x004010b 0x101 0x02 0x0f>,
				<0x02 0x005010b 0x101 0x00 0x0f>,
				<0x03 0x005010b 0x101 0x02 0x0f>,
				<0x04 0x006010b 0x201 0x00 0x0f>,
				<0x05 0x006010b 0x201 0x02 0x0f>,
				<0x06 0x007010b 0x201 0x04 0x0f>,
				<0x07 0x007010b 0x201 0x06 0x0f>,
				<0x08 0x108010b 0x201 0x08 0x0f>,
				<0x09 0x108010b 0x201 0x0a 0x0f>,
				<0x0a 0x109010b 0x201 0x0c 0x0f>,
				<0x0b 0x109010b 0x201 0x0e 0x0f>,
				<0x0c 0x200010a 0x101 0x01 0x0f>,
				<0x0d 0x200010a 0x101 0x03 0x0f>,
				<0x0e 0x201010a 0x101 0x05 0x0f>,
				<0x0f 0x201010a 0x101 0x07 0x0f>,
				<0x10 0x302010a 0x101 0x09 0x0f>,
				<0x11 0x302010a 0x101 0x0b 0x0f>,
				<0x12 0x303010a 0x101 0x0d 0x0f>,
				<0x13 0x303010a 0x101 0x0f 0x0f>;
			samsung,pmmu1-default-stream = <0x404010b>;
			samsung,pmmu1-stream-property =
				<0x01 0x404010b 0x201 0x02 0x0f>,
				<0x02 0x405010b 0x201 0x04 0x0f>,
				<0x03 0x405010b 0x201 0x06 0x0f>,
				<0x04 0x506010b 0x201 0x08 0x0f>,
				<0x05 0x506010b 0x201 0x0a 0x0f>,
				<0x06 0x507010b 0x201 0x0c 0x0f>,
				<0x07 0x507010b 0x201 0x0e 0x0f>,
				<0x08 0x600010b 0x101 0x00 0x0f>,
				<0x09 0x600010b 0x101 0x02 0x0f>,
				<0x0a 0x601010b 0x101 0x04 0x0f>,
				<0x0b 0x601010b 0x101 0x06 0x0f>,
				<0x0c 0x702010b 0x101 0x08 0x0f>,
				<0x0d 0x702010b 0x101 0x0a 0x0f>,
				<0x0e 0x703010b 0x101 0x0c 0x0f>,
				<0x0f 0x703010b 0x101 0x0e 0x0f>,
				<0x10 0x808010a 0x101 0x01 0x0f>,
				<0x11 0x808010b 0x101 0x03 0x0f>;
			#iommu-cells = <0>;
			status = "disabled";
		};

		sysmmu_tnr_s1: iommu@1ccc0000 {
			compatible = "samsung,sysmmu-v9";
			reg = <0x1ccc0000 0x10000>;
			interrupts = <GIC_SPI 687 IRQ_TYPE_LEVEL_HIGH 0>,
				     <GIC_SPI 688 IRQ_TYPE_LEVEL_HIGH 0>;
			power-domains = <&pd_tnr>;
			samsung,qos = <15>;
			samsung,secure-irq;
			samsung,secure-base = <0x1ccd0000>;
			samsung,port-name = "TNR S1";
			samsung,pmmu0-default-stream = <0x10a>;
			samsung,pmmu0-stream-property =
				<0x01 0x000010a 0x101 0x02 0x0f>,
				<0x02 0x001010a 0x101 0x04 0x0f>,
				<0x03 0x001010a 0x101 0x06 0x0f>,
				<0x04 0x102010a 0x101 0x08 0x0f>,
				<0x05 0x102010a 0x101 0x0a 0x0f>,
				<0x06 0x103010a 0x101 0x0c 0x0f>,
				<0x07 0x103010a 0x101 0x0e 0x0f>,
				<0x08 0x804010a 0x201 0x01 0x0f>,
				<0x09 0x804010a 0x201 0x03 0x0f>;
			samsung,pmmu1-default-stream = <0x400010a>;
			samsung,pmmu1-stream-property =
				<0x01 0x400010a 0x201 0x02 0x0f>,
				<0x02 0x402010b 0x101 0x00 0x0f>,
				<0x03 0x402010b 0x101 0x02 0x0f>,
				<0x04 0x501010a 0x201 0x01 0x0f>,
				<0x05 0x501010a 0x201 0x03 0x0f>,
				<0x06 0x503010b 0x101 0x01 0x0f>,
				<0x07 0x503010b 0x101 0x03 0x0f>;
			samsung,pmmu2-default-stream = <0x200010a>;
			samsung,pmmu2-stream-property =
				<0x01 0x200010a 0x101 0x02 0x1f>,
				<0x02 0x201010a 0x101 0x04 0x1f>,
				<0x03 0x201010a 0x101 0x06 0x1f>,
				<0x04 0x302010a 0x101 0x08 0x1f>,
				<0x05 0x302010a 0x101 0x0a 0x1f>,
				<0x06 0x303010a 0x101 0x0c 0x1f>,
				<0x07 0x303010a 0x101 0x0e 0x1f>,
				<0x08 0x704010a 0x201 0x01 0x1f>,
				<0x09 0x704010a 0x201 0x03 0x1f>,
				<0x0a 0x608010b 0x101 0x00 0x1f>,
				<0x0b 0x608010b 0x101 0x03 0x1f>,
				<0x0c 0x705010a 0x201 0x09 0x1f>,
				<0x0d 0x705010a 0x201 0x0b 0x1f>,
				<0x0e 0x609010b 0x101 0x01 0x1f>,
				<0x0f 0x609010b 0x101 0x03 0x1f>,
				<0x10 0x706010a 0x201 0x11 0x1f>,
				<0x11 0x706010a 0x201 0x13 0x1f>,
				<0x12 0x60a010b 0x101 0x01 0x1f>,
				<0x13 0x60a010b 0x101 0x03 0x1f>,
				<0x14 0x707010a 0x201 0x19 0x1f>,
				<0x15 0x707010a 0x201 0x1b 0x1f>,
				<0x16 0x60b010b 0x101 0x01 0x1f>,
				<0x17 0x60b010b 0x101 0x03 0x1f>;
			#iommu-cells = <0>;
			status = "disabled";
		};

		/*
		 * The final MCSC output block has one controller with two PMMUs.
		 * Keep it passive with BLK_MCSC until the processing endpoint owns
		 * reset, completion and buffer-return ordering.
		 */
		sysmmu_mcsc: iommu@1d0a0000 {
			compatible = "samsung,sysmmu-v9";
			reg = <0x1d0a0000 0x10000>;
			interrupts = <GIC_SPI 511 IRQ_TYPE_LEVEL_HIGH 0>,
				     <GIC_SPI 512 IRQ_TYPE_LEVEL_HIGH 0>;
			power-domains = <&pd_mcsc>;
			samsung,qos = <15>;
			samsung,secure-irq;
			samsung,secure-base = <0x1d0b0000>;
			samsung,port-name = "MCSC";
			samsung,pmmu0-default-stream = <0x10b>;
			samsung,pmmu0-stream-property =
				<0x01 0x000010b 0x201 0x04 0x3f>,
				<0x02 0x101010b 0x201 0x08 0x3f>,
				<0x03 0x101010b 0x201 0x0c 0x3f>,
				<0x04 0x202010b 0x201 0x10 0x3f>,
				<0x05 0x202010b 0x201 0x14 0x3f>,
				<0x06 0x303010b 0x201 0x18 0x3f>,
				<0x07 0x303010b 0x201 0x1c 0x3f>,
				<0x08 0x404010b 0x201 0x20 0x3f>,
				<0x09 0x404010b 0x201 0x24 0x3f>,
				<0x0a 0x505010b 0x101 0x00 0x3f>,
				<0x0b 0x505010b 0x101 0x04 0x3f>,
				<0x0c 0x606010b 0x101 0x08 0x3f>,
				<0x0d 0x606010b 0x101 0x0c 0x3f>,
				<0x0e 0x707010b 0x101 0x10 0x3f>,
				<0x0f 0x707010b 0x101 0x14 0x3f>,
				<0x10 0x808010b 0x101 0x18 0x3f>,
				<0x11 0x808010b 0x101 0x1c 0x3f>,
				<0x12 0x909010b 0x101 0x20 0x3f>,
				<0x13 0x909010b 0x101 0x24 0x3f>,
				<0x14 0xa0a010b 0x201 0x01 0x3f>,
				<0x15 0xa0a010b 0x201 0x05 0x3f>,
				<0x16 0xb0b010b 0x201 0x09 0x3f>,
				<0x17 0xb0b010b 0x201 0x0d 0x3f>,
				<0x18 0xc0c010b 0x201 0x11 0x3f>,
				<0x19 0xc0c010b 0x201 0x15 0x3f>,
				<0x1a 0xd0d010b 0x201 0x19 0x3f>,
				<0x1b 0xd0d010b 0x201 0x1d 0x3f>,
				<0x1c 0xe0e010b 0x201 0x21 0x3f>,
				<0x1d 0xe0e010b 0x201 0x25 0x3f>,
				<0x1e 0xf0f010b 0x201 0x02 0x3f>,
				<0x1f 0xf0f010b 0x201 0x06 0x3f>,
				<0x20 0x1010010b 0x201 0x12 0x3f>,
				<0x21 0x1010010b 0x201 0x16 0x3f>,
				<0x22 0x1111010b 0x201 0x22 0x3f>,
				<0x23 0x1111010b 0x201 0x26 0x3f>;
			samsung,pmmu1-default-stream = <0x1200010b>;
			samsung,pmmu1-stream-property =
				<0x01 0x1200010b 0x201 0x04 0x3f>,
				<0x02 0x1301010b 0x201 0x08 0x3f>,
				<0x03 0x1301010b 0x201 0x0c 0x3f>,
				<0x04 0x1402010b 0x201 0x10 0x3f>,
				<0x05 0x1402010b 0x201 0x14 0x3f>,
				<0x06 0x1503010b 0x201 0x18 0x3f>,
				<0x07 0x1503010b 0x201 0x1c 0x3f>,
				<0x08 0x1604010b 0x201 0x20 0x3f>,
				<0x09 0x1604010b 0x201 0x24 0x3f>,
				<0x0a 0x1705010b 0x101 0x00 0x3f>,
				<0x0b 0x1705010b 0x101 0x04 0x3f>,
				<0x0c 0x1806010b 0x101 0x08 0x3f>,
				<0x0d 0x1806010b 0x101 0x0c 0x3f>,
				<0x0e 0x1907010b 0x201 0x01 0x3f>,
				<0x0f 0x1907010b 0x201 0x05 0x3f>,
				<0x10 0x1a08010b 0x201 0x11 0x3f>,
				<0x11 0x1a08010b 0x201 0x15 0x3f>,
				<0x12 0x1b09010b 0x201 0x21 0x3f>,
				<0x13 0x1b09010b 0x201 0x25 0x3f>,
				<0x14 0x1c0a010a 0x101 0x02 0x3f>,
				<0x15 0x1c0a010a 0x101 0x06 0x3f>,
				<0x16 0x1d0b010a 0x201 0x03 0x3f>,
				<0x17 0x1d0b010a 0x201 0x07 0x3f>;
			#iommu-cells = <0>;
			status = "disabled";
		};

		/*
		 * Camera back-end processing core.  Source: downstream
		 * lwis_be_core@1C440000 in research/dumped.dts:13101.  The three
		 * processor windows, seven SSMT windows and RGBP routing register
		 * preserve the downstream resource order.  CMDQ shares each block's
		 * INT0 GIC line, so the downstream nine interrupt entries reduce to
		 * the six unique physical lines below.
		 *
		 * RGBP's command loader resides in BLK_GDC.  Consequently all three
		 * domains and GDC's System MMU are dependencies even though the first
		 * offline path only submits RGBP and YUVP programs.  Keep the complete
		 * complex passive until the board opts into the lifecycle driver.
		 */
		becore: camera@1c440000 {
			compatible = "google,zumapro-becore";
			reg = <0x1c440000 0x10000>,
			      <0x1c470000 0x10000>,
			      <0x1c840000 0x10000>,
			      <0x1c5d4000 0xe00>,
			      <0x1c914000 0xe00>,
			      <0x1c420404 0x4>,
			      <0x1c604000 0xe00>,
			      <0x1c614000 0xe00>,
			      <0x1c624000 0xe00>,
			      <0x1c634000 0xe00>,
			      <0x1c644000 0xe00>;
			reg-names = "rgbp", "mcfp", "yuvp", "ssmt-rgbp",
				    "ssmt-yuvp", "sysreg-rgbp", "ssmt-mcfp0",
				    "ssmt-mcfp1", "ssmt-mcfp2", "ssmt-mcfp3",
				    "ssmt-mcfp4";
			interrupts = <GIC_SPI 673 IRQ_TYPE_LEVEL_HIGH 0>,
				     <GIC_SPI 674 IRQ_TYPE_LEVEL_HIGH 0>,
				     <GIC_SPI 663 IRQ_TYPE_LEVEL_HIGH 0>,
				     <GIC_SPI 664 IRQ_TYPE_LEVEL_HIGH 0>,
				     <GIC_SPI 744 IRQ_TYPE_LEVEL_HIGH 0>,
				     <GIC_SPI 745 IRQ_TYPE_LEVEL_HIGH 0>;
			interrupt-names = "rgbp-int0", "rgbp-int1",
					  "mcfp-int0", "mcfp-int1",
					  "yuvp-int0", "yuvp-int1";
			power-domains = <&pd_yuvp>, <&pd_rgbp>, <&pd_gdc>;
			power-domain-names = "yuvp", "rgbp", "gdc";
			iommus = <&sysmmu_yuvp>, <&sysmmu_rgbp_s0>,
				 <&sysmmu_rgbp_s1>, <&sysmmu_gdc>;
			samsung,iommu-group = <&iommu_group_isp>;
			status = "disabled";
		};

		/*
		 * BLK_ISPFE, the camera receive complex: twelve CSIS links with
		 * nine combo D/C-PHYs behind them, the ISPFE front end, and the
		 * PDMA that carries per-frame descriptors.  Windows are the
		 * reg/reg-names of downstream's lwis_isp_fe@1C000000
		 * (research/dumped.dts:13000-13005).
		 *
		 * Two of those windows nest inside the first: "pdma" and
		 * "pdma-wrap" fall within the 1 MB "isp-fe" range, and downstream
		 * maps them separately because they are separately named blocks.
		 * Keep that split -- a PDMA register is reachable either way, and
		 * treating the whole 1 MB as one opaque window is what made PDMA
		 * traffic look like it did not exist.
		 *
		 * The PMU phandle carries the offset of the word that isolates
		 * the nine D/C-PHYs, which every downstream dcphy node names as
		 * "isolation = <0x3ebc>".  It is a second gate entirely separate
		 * from the per-PHY reset in isp-fe-sysreg, and while it is set
		 * the whole PHY register region reads zero and takes no writes.
		 *
		 * The three "s2mpu" windows are the stage-2 protection units in
		 * front of this block's System MMUs.  They are here rather than
		 * as their own nodes because nothing drives them: they reset
		 * with the power domain into a state that blocks all DMA, and
		 * the vendor's own driver reopens them from its resume path
		 * whenever the hypervisor that would otherwise own them is
		 * absent -- which on mainline is always.  The bootloader
		 * leaving them open, as the GPU bring-up found, only holds
		 * until something power-cycles the domain, and this driver does.
		 *
		 * The "cmu" window is a bring-up shortcut and should not outlive
		 * it.  CMU_ISPFE loses its mux, dividers and Q-channel requests
		 * across a power cycle and mainline models no clock controller for
		 * it, so the driver restores them itself; the right home is a
		 * clock-controller node once CMU_ISPFE is described.  It overlaps
		 * the 4-byte "cmu" window in pd_ispfe, which is fine because both
		 * sides use devm_ioremap() rather than an exclusive request.
		 *
		 * Downstream names 202 interrupts on this block; they land on 17
		 * GIC lines, and all 17 are here.  Each "csis<n>" is one CSIS
		 * link bank's four sources -- int0, int1, frame start and frame
		 * end -- sharing SPI 467 + n.  "csis-core" carries 120 named
		 * sources for the CSIS core and its logical channels.  "fc" is
		 * every frame-controller context, bayer and phase-detect alike;
		 * "lmp-bayer" is the five bayer line-memory instances plus a
		 * debug source, "lmp-pdaf" the four phase-detect ones, and
		 * "pdma" all five PDMA contexts with their error and reset
		 * sources.
		 *
		 * Which link a sensor arrives on is a board property, so the SoC
		 * file names all twelve and the driver asks for the one it is
		 * configured to use.  The same reasoning names the phase-detect
		 * line-memory pool even though a raw Bayer path does not use it:
		 * this describes the block, not one driver's needs.
		 */
		ispfe: camera@1c300000 {
			compatible = "google,zumapro-ispfe";
			reg = <0x1c300000 0x100000>,
			      <0x1c040000 0xd0000>,
			      <0x1c020000 0x10000>,
			      <0x1c390000 0x5000>,
			      <0x1c395000 0x1000>,
			      <0x1c000000 0x8000>,
			      <0x1c140000 0x10000>,
			      <0x1c180000 0x10000>,
			      <0x1c1c0000 0x10000>;
			reg-names = "isp-fe", "csis-link-phy", "isp-fe-sysreg",
				    "pdma", "pdma-wrap", "cmu",
				    "s2mpu0", "s2mpu1", "s2mpu2";
			interrupts = <GIC_SPI 467 IRQ_TYPE_LEVEL_HIGH 0>,
				     <GIC_SPI 468 IRQ_TYPE_LEVEL_HIGH 0>,
				     <GIC_SPI 469 IRQ_TYPE_LEVEL_HIGH 0>,
				     <GIC_SPI 470 IRQ_TYPE_LEVEL_HIGH 0>,
				     <GIC_SPI 471 IRQ_TYPE_LEVEL_HIGH 0>,
				     <GIC_SPI 472 IRQ_TYPE_LEVEL_HIGH 0>,
				     <GIC_SPI 473 IRQ_TYPE_LEVEL_HIGH 0>,
				     <GIC_SPI 474 IRQ_TYPE_LEVEL_HIGH 0>,
				     <GIC_SPI 475 IRQ_TYPE_LEVEL_HIGH 0>,
				     <GIC_SPI 476 IRQ_TYPE_LEVEL_HIGH 0>,
				     <GIC_SPI 477 IRQ_TYPE_LEVEL_HIGH 0>,
				     <GIC_SPI 478 IRQ_TYPE_LEVEL_HIGH 0>,
				     <GIC_SPI 479 IRQ_TYPE_LEVEL_HIGH 0>,
				     <GIC_SPI 480 IRQ_TYPE_LEVEL_HIGH 0>,
				     <GIC_SPI 481 IRQ_TYPE_LEVEL_HIGH 0>,
				     <GIC_SPI 482 IRQ_TYPE_LEVEL_HIGH 0>,
				     <GIC_SPI 483 IRQ_TYPE_LEVEL_HIGH 0>;
			interrupt-names = "csis0", "csis1", "csis2", "csis3",
					  "csis4", "csis5", "csis6", "csis7",
					  "csis8", "csis9", "csis10", "csis11",
					  "csis-core", "fc", "lmp-bayer",
					  "lmp-pdaf", "pdma";
			power-domains = <&pd_ispfe>;
			clocks = <&acpm_ipc ZUMAPRO_CLK_ACPM_DVFS_CAM>;
			clock-names = "cam";
			interconnects = <&bts ZUMAPRO_BTS_MASTER_ISPFE>,
					<&bts ZUMAPRO_BTS_SLAVE_MIF>;
			interconnect-names = "memory";
			google,backend = <&becore>;
			iommus = <&sysmmu_ispfe_s0>, <&sysmmu_ispfe_s1>,
				 <&sysmmu_ispfe_s2>;
			samsung,iommu-group = <&iommu_group_isp>;
			samsung,pmu-syscon = <&pmu_system_controller 0x3ebc>;
			status = "disabled";
		};
	};

	/*
	 * Source: APM SRAM base/size are from the downstream ACPM node in
	 * research/dumped.dts:15296 (0x15700000, 0x58000).  The ACPM channel
	 * table at offset 0xa000 was dumped live over the m1n1 proxy
	 * (scripts/acpm-dump-channels.py, research/tracing/acpm-channels.md).
	 */
	apm_sram: sram@15700000 {
		compatible = "mmio-sram";
		reg = <0x0 0x15700000 0x58000>;
		#address-cells = <1>;
		#size-cells = <1>;
		ranges = <0x0 0x0 0x15700000 0x58000>;
	};

	/*
	 * Source: architectural timer interrupts and CNTFRQ are from
	 * research/dumped.dts:15034-15038.
	 */
	timer {
		compatible = "arm,armv8-timer";
		interrupts =
			<GIC_PPI 13 (GIC_CPU_MASK_SIMPLE(8) | IRQ_TYPE_LEVEL_LOW) 0>,
			<GIC_PPI 14 (GIC_CPU_MASK_SIMPLE(8) | IRQ_TYPE_LEVEL_LOW) 0>,
			<GIC_PPI 11 (GIC_CPU_MASK_SIMPLE(8) | IRQ_TYPE_LEVEL_LOW) 0>,
			<GIC_PPI 10 (GIC_CPU_MASK_SIMPLE(8) | IRQ_TYPE_LEVEL_LOW) 0>;
		clock-frequency = <24576000>;
	};
};
